VERSION ""

NS_ :

BS_:

BU_: FICM_FD Vector__XXX

BO_ 934 SeatAdjust2_FICM: 8 FICM_FD
 SG_ StTrkAdjReq_DR : 1|2@0+ (1,0) [0|2] ""  Vector__XXX
 SG_ StRtaAdjReq_DR : 3|2@0+ (1,0) [0|2] ""  Vector__XXX
 SG_ StRtaAdjReq_3rdL_FICM : 5|2@0+ (1,0) [0|2] ""  Vector__XXX
 SG_ StRtaAdjReq_3rdR_FICM : 7|2@0+ (1,0) [0|2] ""  Vector__XXX
 SG_ StHtReq_RL_HMI : 10|3@0+ (1,0) [0|4] ""  Vector__XXX
 SG_ StVtReq_RL_HMI : 13|3@0+ (1,0) [0|4] ""  Vector__XXX
 SG_ StPstrCmd_RL : 15|2@0+ (1,0) [0|3] ""  Vector__XXX
 SG_ StHtReq_RR_HMI : 18|3@0+ (1,0) [0|4] ""  Vector__XXX
 SG_ StVtReq_RR_HMI : 21|3@0+ (1,0) [0|4] ""  Vector__XXX
 SG_ StPstrCmd_RR : 23|2@0+ (1,0) [0|3] ""  Vector__XXX
 SG_ StLgRtaAdjReq_3rdR_FICM : 25|2@0+ (1,0) [0|2] ""  Vector__XXX
 SG_ StLgRtaAdjReq_3rdL_FICM : 27|2@0+ (1,0) [0|2] ""  Vector__XXX
 SG_ StTiltAdjReq_DR_FICM : 29|2@0+ (1,0) [0|2] ""  Vector__XXX
 SG_ StPhaAdjReq_DR_FICM : 31|2@0+ (1,0) [0|2] ""  Vector__XXX
 SG_ StSldAdjReq_RL_FICM : 33|2@0+ (1,0) [0|2] ""  Vector__XXX
 SG_ StLgLgthAdjReq_RL_FICM : 35|2@0+ (1,0) [0|2] ""  Vector__XXX
 SG_ StLgRtaAdjReq_RL_FICM : 37|2@0+ (1,0) [0|2] ""  Vector__XXX
 SG_ StSldAdjReq_RR_FICM : 39|2@0+ (1,0) [0|2] ""  Vector__XXX
 SG_ StLgLgthAdjReq_RR_FICM : 41|2@0+ (1,0) [0|2] ""  Vector__XXX
 SG_ StLgRtaAdjReq_RR_FICM : 43|2@0+ (1,0) [0|2] ""  Vector__XXX
 SG_ StHdrstAdjReq_RL_FICM : 45|2@0+ (1,0) [0|2] ""  Vector__XXX
 SG_ StHdrstAdjReq_RR_FICM : 47|2@0+ (1,0) [0|2] ""  Vector__XXX
 SG_ StMemCmd_RL_HMI : 49|2@0+ (1,0) [0|3] ""  Vector__XXX
 SG_ StMemPstnCalloutCmd_RL_HMI : 51|2@0+ (1,0) [0|3] ""  Vector__XXX
 SG_ StMemCmd_RR_HMI : 53|2@0+ (1,0) [0|3] ""  Vector__XXX
 SG_ StMemPstnCalloutCmd_RR_HMI : 55|2@0+ (1,0) [0|3] ""  Vector__XXX
 SG_ StPstrCmd_DR : 57|2@0+ (1,0) [0|3] ""  Vector__XXX
 SG_ StPstrCmd_PR : 59|2@0+ (1,0) [0|3] ""  Vector__XXX

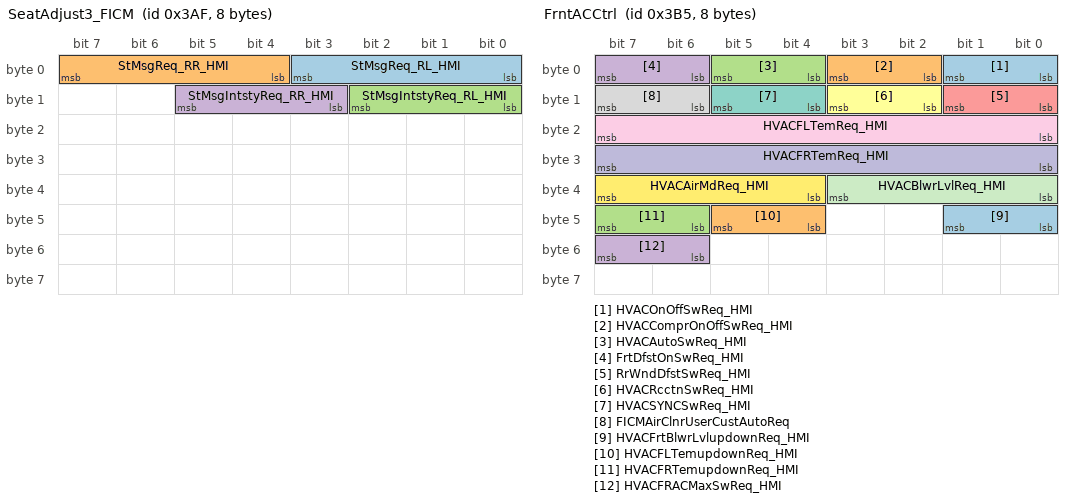
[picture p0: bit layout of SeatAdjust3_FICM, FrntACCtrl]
BO_ 943 SeatAdjust3_FICM: 8 FICM_FD
 SG_ StMsgReq_RL_HMI : 3|4@0+ (1,0) [0|15] ""  Vector__XXX
 SG_ StMsgReq_RR_HMI : 7|4@0+ (1,0) [0|15] ""  Vector__XXX
 SG_ StMsgIntstyReq_RL_HMI : 10|3@0+ (1,0) [0|4] ""  Vector__XXX
 SG_ StMsgIntstyReq_RR_HMI : 13|3@0+ (1,0) [0|4] ""  Vector__XXX

BO_ 944 Settings: 8 FICM_FD
 SG_ SnsSldDrSetReq : 1|2@0+ (1,0) [0|3] ""  Vector__XXX
 SG_ SnsSldDrActnTypSetReq : 4|3@0+ (1,0) [0|7] ""  Vector__XXX
 SG_ PDCBeepOffReq_F : 6|2@0+ (1,0) [0|3] ""  Vector__XXX
 SG_ ShowroomMdSts : 7|1@0+ (1,0) [0|1] ""  Vector__XXX
 SG_ StWelcomeSet_PR : 9|2@0+ (1,0) [0|2] ""  Vector__XXX
 SG_ SldDrOprtMdSt : 11|2@0+ (1,0) [0|3] ""  Vector__XXX
 SG_ FndMyCarSet : 13|2@0+ (1,0) [0|3] ""  Vector__XXX
 SG_ PDCBeepOffReq_R : 15|2@0+ (1,0) [0|3] ""  Vector__XXX
 SG_ RstrFctryDfltSttngRqst : 16|1@0+ (1,0) [0|1] ""  Vector__XXX
 SG_ RemoteLockingFdbckChgReq : 18|2@0+ (1,0) [0|3] ""  Vector__XXX
 SG_ IntLgtOprtMdSet : 20|2@0+ (1,0) [0|3] ""  Vector__XXX
 SG_ VehUnLckFormSet : 22|2@0+ (1,0) [0|3] ""  Vector__XXX
 SG_ SentryMdSetReq : 25|2@0+ (1,0) [0|3] ""  Vector__XXX
 SG_ TmDsplyFmt : 26|1@0+ (1,0) [0|1] ""  Vector__XXX
 SG_ MovingAutoLockChgReq : 29|2@0+ (1,0) [0|3] ""  Vector__XXX
 SG_ LanguageSettingAdj : 35|4@0+ (1,0) [0|15] ""  Vector__XXX
 SG_ DrvMdReq_HMI : 37|2@0+ (1,0) [0|3] ""  Vector__XXX
 SG_ LckAutoWdwClsSet : 39|2@0+ (1,0) [0|3] ""  Vector__XXX
 SG_ AutoUnlockingChgReq : 42|3@0+ (1,0) [0|4] ""  Vector__XXX
 SG_ FolwMeHmSet : 45|3@0+ (1,0) [0|4] ""  Vector__XXX
 SG_ MrrAutoFldSet : 47|2@0+ (1,0) [0|3] ""  Vector__XXX
 SG_ WprSnstvtytSet : 50|3@0+ (1,0) [0|7] ""  Vector__XXX
 SG_ RvsGearActvtRrWprSet : 52|2@0+ (1,0) [0|3] ""  Vector__XXX
 SG_ RainPrvtMdSet : 54|2@0+ (1,0) [0|3] ""  Vector__XXX
 SG_ MemReq : 57|2@0+ (1,0) [0|3] ""  Vector__XXX
 SG_ MemClrReq : 60|3@0+ (1,0) [0|4] ""  Vector__XXX
 SG_ MemCalOtReq : 62|2@0+ (1,0) [0|3] ""  Vector__XXX

BO_ 945 Settings2: 8 FICM_FD
 SG_ FICMOverSpdThreshholdVal : 7|8@0+ (1,0) [0|255] "km/h"  Vector__XXX
 SG_ TempParkReq : 9|2@0+ (1,0) [0|2] ""  Vector__XXX
 SG_ ThemeSettingAdj : 11|2@0+ (1,0) [0|3] ""  Vector__XXX
 SG_ VehMaintenanceSts : 13|2@0+ (1,0) [0|3] ""  Vector__XXX
 SG_ FICMOverSpdSwitchReq : 15|2@0+ (1,0) [0|2] ""  Vector__XXX
 SG_ DrvMdRcmdnDispReqFdbck : 18|3@0+ (1,0) [0|7] ""  Vector__XXX
 SG_ FICMDispRcmdnInfoEnbSts : 19|1@0+ (1,0) [0|1] ""  Vector__XXX
 SG_ HMIMtSwSts_L : 20|1@0+ (1,0) [0|1] ""  Vector__XXX
 SG_ HMICallPhReqSts : 21|1@0+ (1,0) [0|1] ""  Vector__XXX
 SG_ TempParkMdSet : 23|2@0+ (1,0) [0|3] ""  Vector__XXX
 SG_ HMIMtSwSts_R : 24|1@0+ (1,0) [0|1] ""  Vector__XXX
 SG_ RemnDstcDsplyExchgReq : 26|2@0+ (1,0) [0|3] ""  Vector__XXX
 SG_ DspMeasUntSetReq : 28|2@0+ (1,0) [0|3] ""  Vector__XXX
 SG_ IntLgtOffReq : 29|1@0+ (1,0) [0|1] ""  Vector__XXX
 SG_ RemnDstcDsplyCycReq : 31|2@0+ (1,0) [0|3] ""  Vector__XXX
 SG_ ChldLckSw_R : 33|2@0+ (1,0) [0|3] ""  Vector__XXX
 SG_ LockVehRcvrMdSet : 35|2@0+ (1,0) [0|3] ""  Vector__XXX
 SG_ IntltWlcmMdSet : 37|2@0+ (1,0) [0|3] ""  Vector__XXX
 SG_ ThemeSettingAdj_2 : 39|2@0+ (1,0) [0|3] ""  Vector__XXX
 SG_ RunPowMdAutoOffReq : 41|2@0+ (1,0) [0|3] ""  Vector__XXX
 SG_ CPDWrnngLvl : 43|2@0+ (1,0) [0|3] ""  Vector__XXX
 SG_ SldDrCtrlReq_R_HMI : 45|2@0+ (1,0) [0|3] ""  Vector__XXX
 SG_ ChldLckSw_L : 47|2@0+ (1,0) [0|3] ""  Vector__XXX
 SG_ CPDFnSwReq : 53|2@0+ (1,0) [0|3] ""  Vector__XXX
 SG_ RunPowMdAutoOffRmndrFdbck : 55|2@0+ (1,0) [0|3] ""  Vector__XXX
 SG_ ESSSwapCnfmFICM : 56|1@0+ (1,0) [0|1] ""  Vector__XXX
 SG_ ESSSwapCnfmFICMV : 57|1@0+ (1,0) [0|1] ""  Vector__XXX
 SG_ LanguageSettingAdj_2 : 49|8@0+ (1,0) [0|255] ""  Vector__XXX

BO_ 946 BodyCtrl: 8 FICM_FD
 SG_ HdLmpAdjReq : 2|3@0+ (1,0) [0|4] ""  Vector__XXX
 SG_ VisionMdReq : 4|2@0+ (1,0) [0|3] ""  Vector__XXX
 SG_ TlgtOprtMdSt : 6|2@0+ (1,0) [0|3] ""  Vector__XXX
 SG_ TlgtOprtReq : 11|4@0+ (1,0) [0|15] ""  Vector__XXX
 SG_ PDCMainSWReq_ICU : 13|2@0+ (1,0) [0|3] ""  Vector__XXX
 SG_ ChrIndReq_HMI : 15|2@0+ (1,0) [0|3] ""  Vector__XXX
 SG_ WPCEnblReq : 17|2@0+ (1,0) [0|3] ""  Vector__XXX
 SG_ BkltLumSet : 22|5@0+ (5,0) [0|100] "%"  Vector__XXX
 SG_ FrtFogLmpOprtMdSet : 25|2@0+ (1,0) [0|3] ""  Vector__XXX
 SG_ HdLmpOprtMdSet : 28|3@0+ (1,0) [0|4] ""  Vector__XXX
 SG_ FogLmpOprtMdSet : 30|2@0+ (1,0) [0|3] ""  Vector__XXX
 SG_ PMMOFFReq : 32|1@0+ (1,0) [0|1] ""  Vector__XXX
 SG_ TlgtPrkMdPosSt : 39|7@0+ (1,0) [0|100] "%"  Vector__XXX
 SG_ MrrAutoDipSet : 42|3@0+ (1,0) [0|7] ""  Vector__XXX
 SG_ FrtWprOprtReq : 45|3@0+ (1,0) [0|7] ""  Vector__XXX
 SG_ FICMBssMdReq : 47|2@0+ (1,0) [0|3] ""  Vector__XXX
 SG_ BodyCtrl_RllCnt : 51|4@0+ (1,0) [0|15] ""  Vector__XXX
 SG_ PckLgtOprtMdSet : 55|2@0+ (1,0) [0|3] ""  Vector__XXX
 SG_ BodyCtrl_Chksum : 63|8@0+ (1,0) [0|255] ""  Vector__XXX

BO_ 947 Chassis_PowerTrainCtrl: 8 FICM_FD
 SG_ HDCFnSwReq : 1|2@0+ (1,0) [0|3] ""  Vector__XXX
 SG_ ESCFnSwReq : 3|2@0+ (1,0) [0|3] ""  Vector__XXX
 SG_ EPBIgnoffAutoAppFnSwReq : 5|2@0+ (1,0) [0|3] ""  Vector__XXX
 SG_ AVHFnSwReq : 7|2@0+ (1,0) [0|3] ""  Vector__XXX
 SG_ EPBRlseFuSwReq : 9|2@0+ (1,0) [0|3] ""  Vector__XXX
 SG_ EPSCurrModReq : 12|3@0+ (1,0) [0|7] ""  Vector__XXX
 SG_ BrkFlngMdStsReq : 15|3@0+ (1,0) [0|7] ""  Vector__XXX
 SG_ RGNSwReq : 17|2@0+ (1,0) [0|3] ""  Vector__XXX
 SG_ FrtPsngAirbagOnOffReq : 19|2@0+ (1,0) [0|3] ""  Vector__XXX
 SG_ RGNSwReqV : 20|1@0+ (1,0) [0|1] ""  Vector__XXX
 SG_ RGNResReq : 21|1@0+ (1,0) [0|1] ""  Vector__XXX
 SG_ RGNResReqV : 22|1@0+ (1,0) [0|1] ""  Vector__XXX
 SG_ ASSBtnReq : 23|1@0+ (1,0) [0|1] ""  Vector__XXX
 SG_ SBRSetReq_R : 33|2@0+ (1,0) [0|3] ""  Vector__XXX
 SG_ RGNOkNum : 31|14@0+ (1,0) [0|10000] ""  Vector__XXX
 SG_ RGNResNum : 47|8@0+ (1,0) [0|255] ""  Vector__XXX
 SG_ Chassis_PowerTrainCtrl_RllCnt : 51|4@0+ (1,0) [0|15] ""  Vector__XXX
 SG_ CCOFnSoftSw : 53|2@0+ (1,0) [0|3] ""  Vector__XXX
 SG_ WadeModeReq : 55|2@0+ (1,0) [0|3] ""  Vector__XXX
 SG_ Chassis_PowerTrainCtrl_Chksum : 63|8@0+ (1,0) [0|255] ""  Vector__XXX

BO_ 949 FrntACCtrl: 8 FICM_FD
 SG_ HVACOnOffSwReq_HMI : 1|2@0+ (1,0) [0|3] ""  Vector__XXX
 SG_ HVACComprOnOffSwReq_HMI : 3|2@0+ (1,0) [0|3] ""  Vector__XXX
 SG_ HVACAutoSwReq_HMI : 5|2@0+ (1,0) [0|3] ""  Vector__XXX
 SG_ FrtDfstOnSwReq_HMI : 7|2@0+ (1,0) [0|3] ""  Vector__XXX
 SG_ RrWndDfstSwReq_HMI : 9|2@0+ (1,0) [0|3] ""  Vector__XXX
 SG_ HVACRcctnSwReq_HMI : 11|2@0+ (1,0) [0|3] ""  Vector__XXX
 SG_ HVACSYNCSwReq_HMI : 13|2@0+ (1,0) [0|3] ""  Vector__XXX
 SG_ FICMAirClnrUserCustAutoReq : 15|2@0+ (1,0) [0|3] ""  Vector__XXX
 SG_ HVACFLTemReq_HMI : 23|8@0+ (1,0) [17|33] "deg C"  Vector__XXX
 SG_ HVACFRTemReq_HMI : 31|8@0+ (1,0) [17|33] "deg C"  Vector__XXX
 SG_ HVACBlwrLvlReq_HMI : 35|4@0+ (1,0) [0|15] ""  Vector__XXX
 SG_ HVACAirMdReq_HMI : 39|4@0+ (1,0) [0|15] ""  Vector__XXX
 SG_ HVACFrtBlwrLvlupdownReq_HMI : 41|2@0+ (1,0) [0|3] ""  Vector__XXX
 SG_ HVACFLTemupdownReq_HMI : 45|2@0+ (1,0) [0|3] ""  Vector__XXX
 SG_ HVACFRTemupdownReq_HMI : 47|2@0+ (1,0) [0|3] ""  Vector__XXX
 SG_ HVACFRACMaxSwReq_HMI : 55|2@0+ (1,0) [0|3] ""  Vector__XXX

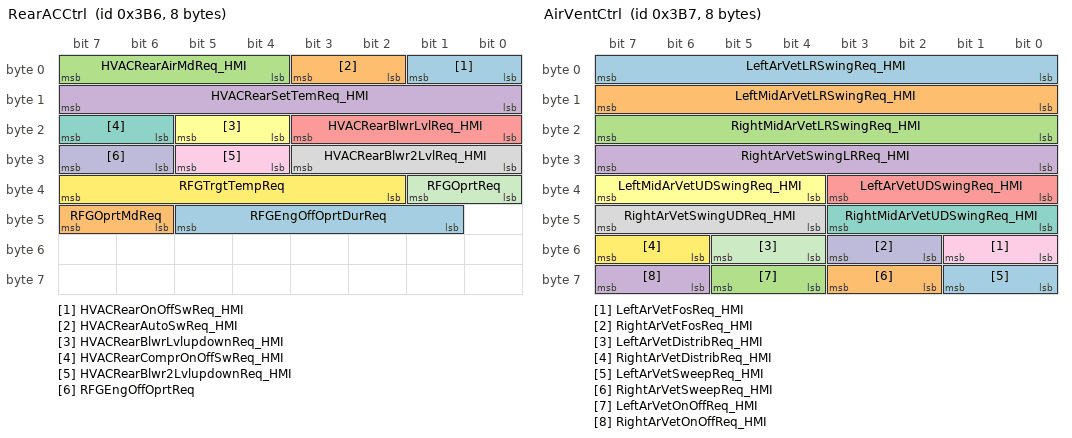
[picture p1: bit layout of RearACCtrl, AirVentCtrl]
BO_ 950 RearACCtrl: 8 FICM_FD
 SG_ HVACRearOnOffSwReq_HMI : 1|2@0+ (1,0) [0|3] ""  Vector__XXX
 SG_ HVACRearAutoSwReq_HMI : 3|2@0+ (1,0) [0|3] ""  Vector__XXX
 SG_ HVACRearAirMdReq_HMI : 7|4@0+ (1,0) [0|15] ""  Vector__XXX
 SG_ HVACRearSetTemReq_HMI : 15|8@0+ (1,0) [17|33] "deg C"  Vector__XXX
 SG_ HVACRearBlwrLvlReq_HMI : 19|4@0+ (1,0) [0|15] ""  Vector__XXX
 SG_ HVACRearBlwrLvlupdownReq_HMI : 21|2@0+ (1,0) [0|3] ""  Vector__XXX
 SG_ HVACRearComprOnOffSwReq_HMI : 23|2@0+ (1,0) [1|3] ""  Vector__XXX
 SG_ HVACRearBlwr2LvlReq_HMI : 27|4@0+ (1,0) [0|15] ""  Vector__XXX
 SG_ HVACRearBlwr2LvlupdownReq_HMI : 29|2@0+ (1,0) [0|3] ""  Vector__XXX
 SG_ RFGEngOffOprtReq : 31|2@0+ (1,0) [0|3] ""  Vector__XXX
 SG_ RFGOprtReq : 33|2@0+ (1,0) [0|3] ""  Vector__XXX
 SG_ RFGTrgtTempReq : 39|6@0+ (1,0) [0|63] "℃"  Vector__XXX
 SG_ RFGEngOffOprtDurReq : 45|5@0+ (1,0) [0|31] "h"  Vector__XXX
 SG_ RFGOprtMdReq : 47|2@0+ (1,0) [0|3] ""  Vector__XXX

BO_ 951 AirVentCtrl: 8 FICM_FD
 SG_ LeftArVetLRSwingReq_HMI : 7|8@0+ (1,0) [0|100] "%"  Vector__XXX
 SG_ LeftMidArVetLRSwingReq_HMI : 15|8@0+ (1,0) [0|100] "%"  Vector__XXX
 SG_ RightMidArVetLRSwingReq_HMI : 23|8@0+ (1,0) [0|100] "%"  Vector__XXX
 SG_ RightArVetSwingLRReq_HMI : 31|8@0+ (1,0) [0|100] "%"  Vector__XXX
 SG_ LeftArVetUDSwingReq_HMI : 35|4@0+ (10,0) [0|100] "%"  Vector__XXX
 SG_ LeftMidArVetUDSwingReq_HMI : 39|4@0+ (10,0) [0|100] "%"  Vector__XXX
 SG_ RightMidArVetUDSwingReq_HMI : 43|4@0+ (10,0) [0|100] "%"  Vector__XXX
 SG_ RightArVetSwingUDReq_HMI : 47|4@0+ (10,0) [0|100] "%"  Vector__XXX
 SG_ LeftArVetFosReq_HMI : 49|2@0+ (1,0) [0|3] ""  Vector__XXX
 SG_ RightArVetFosReq_HMI : 51|2@0+ (1,0) [0|3] ""  Vector__XXX
 SG_ LeftArVetDistribReq_HMI : 53|2@0+ (1,0) [0|3] ""  Vector__XXX
 SG_ RightArVetDistribReq_HMI : 55|2@0+ (1,0) [0|3] ""  Vector__XXX
 SG_ LeftArVetSweepReq_HMI : 57|2@0+ (1,0) [0|3] ""  Vector__XXX
 SG_ RightArVetSweepReq_HMI : 59|2@0+ (1,0) [0|3] ""  Vector__XXX
 SG_ LeftArVetOnOffReq_HMI : 61|2@0+ (1,0) [0|3] ""  Vector__XXX
 SG_ RightArVetOnOffReq_HMI : 63|2@0+ (1,0) [0|3] ""  Vector__XXX

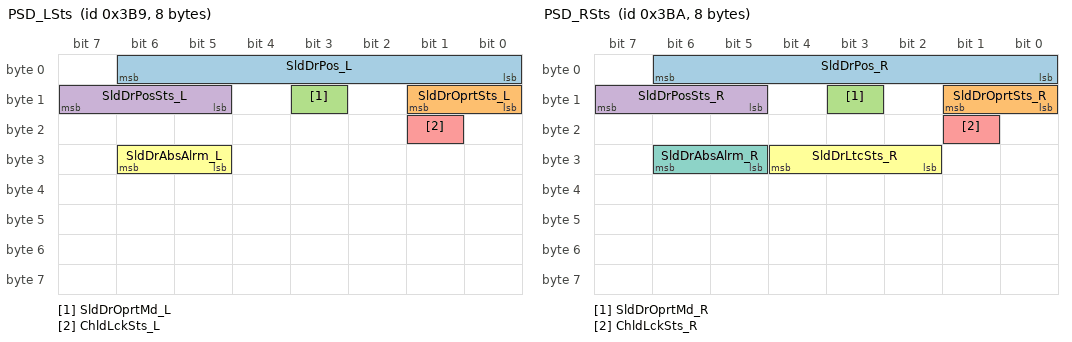
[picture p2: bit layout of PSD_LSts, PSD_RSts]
BO_ 953 PSD_LSts: 8 Vector__XXX
 SG_ SldDrPos_L : 6|7@0+ (1,0) [0|127] "%"  FICM_FD
 SG_ SldDrOprtSts_L : 9|2@0+ (1,0) [0|3] ""  FICM_FD
 SG_ SldDrOprtMd_L : 11|1@0+ (1,0) [0|1] ""  FICM_FD
 SG_ SldDrPosSts_L : 15|3@0+ (1,0) [0|7] ""  FICM_FD
 SG_ ChldLckSts_L : 17|1@0+ (1,0) [0|1] ""  FICM_FD
 SG_ SldDrAbsAlrm_L : 30|2@0+ (1,0) [0|3] ""  FICM_FD

BO_ 954 PSD_RSts: 8 Vector__XXX
 SG_ SldDrPos_R : 6|7@0+ (1,0) [0|127] "%"  FICM_FD
 SG_ SldDrOprtSts_R : 9|2@0+ (1,0) [0|3] ""  FICM_FD
 SG_ SldDrOprtMd_R : 11|1@0+ (1,0) [0|1] ""  FICM_FD
 SG_ SldDrPosSts_R : 15|3@0+ (1,0) [0|7] ""  FICM_FD
 SG_ ChldLckSts_R : 17|1@0+ (1,0) [0|1] ""  FICM_FD
 SG_ SldDrLtcSts_R : 28|3@0+ (1,0) [0|7] ""  FICM_FD
 SG_ SldDrAbsAlrm_R : 30|2@0+ (1,0) [0|3] ""  FICM_FD

BO_ 956 BodyCtrl2: 8 FICM_FD
 SG_ HMIRfLmp1Cmd : 2|2@0+ (1,0) [0|2] ""  Vector__XXX
 SG_ Wdw_DRAutoOprtnReq : 7|5@0+ (5,0) [0|100] "%"  Vector__XXX
 SG_ Wdw_PRAutoOprtnReq : 12|5@0+ (5,0) [0|100] "%"  Vector__XXX
 SG_ AprchngLghtSt : 14|2@0+ (1,0) [0|3] ""  Vector__XXX
 SG_ IntWlcmLampSetReq : 0|2@0+ (1,0) [0|3] ""  Vector__XXX
 SG_ HMIRfLmp2Cmd : 18|2@0+ (1,0) [0|2] ""  Vector__XXX
 SG_ Wdw_RLAutoOprtnReq : 23|5@0+ (5,0) [0|100] "%"  Vector__XXX
 SG_ Wdw_RRAutoOprtnReq : 28|5@0+ (5,0) [0|100] "%"  Vector__XXX
 SG_ DrvrFatigueReminderSetReq : 30|2@0+ (1,0) [0|3] ""  Vector__XXX
 SG_ LogoLgtOnPGearSetReq : 16|2@0+ (1,0) [0|3] ""  Vector__XXX
 SG_ HMIRfLmp3Cmd : 33|2@0+ (1,0) [0|2] ""  Vector__XXX
 SG_ HMIRfLmp4Cmd : 35|2@0+ (1,0) [0|2] ""  Vector__XXX
 SG_ PSRTrgtSlct : 37|2@0+ (1,0) [0|3] ""  Vector__XXX
 SG_ PSRManualOprtReq : 39|2@0+ (1,0) [0|3] ""  Vector__XXX
 SG_ HMIRfLmpTrdRowCmd : 42|2@0+ (1,0) [0|2] ""  Vector__XXX
 SG_ PSRAutoOprtReq : 47|5@0+ (1,0) [0|31] ""  Vector__XXX
 SG_ SRFAutoOprtReq : 52|5@0+ (1,0) [0|31] ""  Vector__XXX
 SG_ SRFManualOprtReq : 54|2@0+ (1,0) [0|3] ""  Vector__XXX
 SG_ HVFuelCmd : 40|2@0+ (1,0) [0|2] ""  Vector__XXX
 SG_ TlgtOprtPosReq : 62|7@0+ (1,0) [0|100] "%"  Vector__XXX

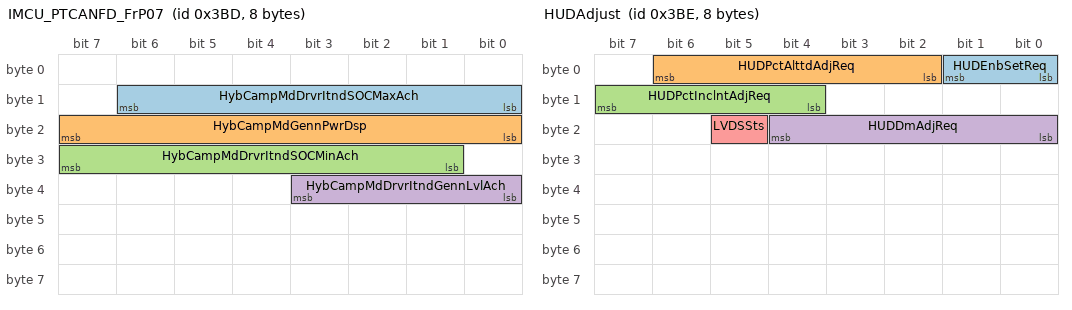
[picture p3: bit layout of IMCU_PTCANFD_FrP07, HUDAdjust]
BO_ 957 IMCU_PTCANFD_FrP07: 8 Vector__XXX
 SG_ HybCampMdDrvrItndSOCMaxAch : 14|7@0+ (1,0) [0|127] ""  FICM_FD
 SG_ HybCampMdGennPwrDsp : 23|8@0+ (0.1,0) [0|25.5] ""  FICM_FD
 SG_ HybCampMdDrvrItndSOCMinAch : 31|7@0+ (1,0) [0|127] ""  FICM_FD
 SG_ HybCampMdDrvrItndGennLvlAch : 35|4@0+ (1,0) [0|15] ""  FICM_FD

BO_ 958 HUDAdjust: 8 FICM_FD
 SG_ HUDEnbSetReq : 1|2@0+ (1,0) [0|3] ""  Vector__XXX
 SG_ HUDPctAlttdAdjReq : 6|5@0+ (1,0) [0|20] ""  Vector__XXX
 SG_ HUDPctInclntAdjReq : 15|4@0+ (1,0) [0|15] ""  Vector__XXX
 SG_ HUDDmAdjReq : 20|5@0+ (1,0) [0|20] ""  Vector__XXX
 SG_ LVDSSts : 21|1@0+ (1,0) [0|1] ""  Vector__XXX

BO_ 965 PersonalSettings: 8 Vector__XXX
 SG_ VehUnLckForm_VAN : 6|3@0+ (1,0) [0|7] ""  FICM_FD
 SG_ RainPrvtMdSts : 8|1@0+ (1,0) [0|1] ""  FICM_FD
 SG_ LckAutoWdwClsSts : 9|1@0+ (1,0) [0|1] ""  FICM_FD
 SG_ StWelcomeSts_DR : 10|1@0+ (1,0) [0|1] ""  FICM_FD
 SG_ TempParkMdSetSts : 11|1@0+ (1,0) [0|1] ""  FICM_FD
 SG_ TempParkMode : 12|1@0+ (1,0) [0|1] ""  FICM_FD
 SG_ VehUnLckForm : 13|1@0+ (1,0) [0|1] ""  FICM_FD
 SG_ LckFdbkSts : 15|2@0+ (1,0) [0|2] ""  FICM_FD
 SG_ MrrAutoDipSts : 17|2@0+ (1,0) [0|3] ""  FICM_FD
 SG_ MrrAutoFldSts : 18|1@0+ (1,0) [0|1] ""  FICM_FD
 SG_ DrvrFatigueReminderSetReqFdbck : 19|1@0+ (1,0) [0|1] ""  FICM_FD
 SG_ StWelcomeSts_PR : 20|1@0+ (1,0) [0|1] ""  FICM_FD
 SG_ FlwMHmSts : 25|2@0+ (1,0) [0|3] ""  FICM_FD
 SG_ IntltWlcmMdSts : 26|1@0+ (1,0) [0|1] ""  FICM_FD
 SG_ LockVehRcvrMdSts : 27|1@0+ (1,0) [0|1] ""  FICM_FD
 SG_ FndMyCarSts : 29|2@0+ (1,0) [0|3] ""  FICM_FD
 SG_ FndMyCarTmSts : 31|2@0+ (1,0) [0|3] ""  FICM_FD
 SG_ DrvMod : 33|2@0+ (1,0) [0|3] ""  FICM_FD
 SG_ DrvMdReqV : 34|1@0+ (1,0) [0|1] ""  FICM_FD
 SG_ MemFdbk : 39|2@0+ (1,0) [0|2] ""  FICM_FD
 SG_ MemClrFdbk : 41|2@0+ (1,0) [0|2] ""  FICM_FD
 SG_ SnsSldDrSetReqFdbck : 42|1@0+ (1,0) [0|1] ""  FICM_FD
 SG_ AutoUnlockingSts : 44|2@0+ (1,0) [0|3] ""  FICM_FD
 SG_ MovingAutoLockSts : 45|1@0+ (1,0) [0|1] ""  FICM_FD
 SG_ iBDUFctryDeftSetFnsh : 47|2@0+ (1,0) [0|3] ""  FICM_FD
 SG_ RunPowMdAutoOffSts : 54|1@0+ (1,0) [0|1] ""  FICM_FD
 SG_ RunPowMdAutoOffRmndrReq : 55|1@0+ (1,0) [0|1] ""  FICM_FD

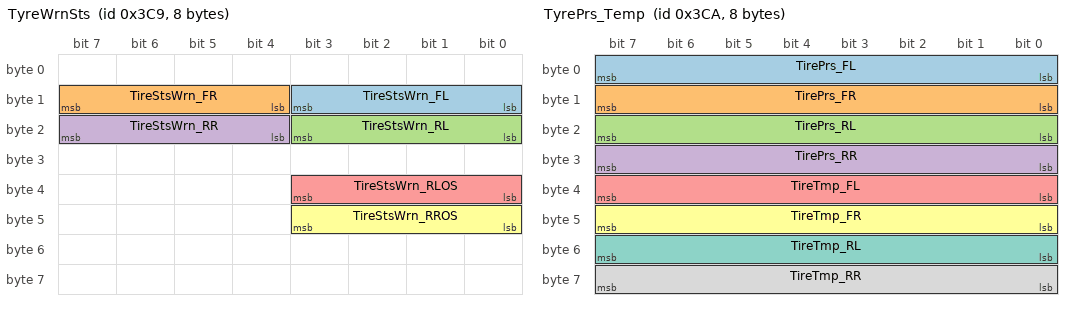
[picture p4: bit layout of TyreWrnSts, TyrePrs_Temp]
BO_ 969 TyreWrnSts: 8 Vector__XXX
 SG_ TireStsWrn_FL : 11|4@0+ (1,0) [0|15] ""  FICM_FD
 SG_ TireStsWrn_FR : 15|4@0+ (1,0) [0|15] ""  FICM_FD
 SG_ TireStsWrn_RL : 19|4@0+ (1,0) [0|15] ""  FICM_FD
 SG_ TireStsWrn_RR : 23|4@0+ (1,0) [0|15] ""  FICM_FD
 SG_ TireStsWrn_RLOS : 35|4@0+ (1,0) [0|15] ""  FICM_FD
 SG_ TireStsWrn_RROS : 43|4@0+ (1,0) [0|15] ""  FICM_FD

BO_ 970 TyrePrs_Temp: 8 Vector__XXX
 SG_ TirePrs_FL : 7|8@0+ (2.75,0) [0|700] "kpa"  FICM_FD
 SG_ TirePrs_FR : 15|8@0+ (2.75,0) [0|700] "kpa"  FICM_FD
 SG_ TirePrs_RL : 23|8@0+ (2.75,0) [0|700] "kpa"  FICM_FD
 SG_ TirePrs_RR : 31|8@0+ (2.75,0) [0|700] "kpa"  FICM_FD
 SG_ TireTmp_FL : 39|8@0+ (1,-60) [-60|194] ""  FICM_FD
 SG_ TireTmp_FR : 47|8@0+ (1,-60) [-60|194] ""  FICM_FD
 SG_ TireTmp_RL : 55|8@0+ (1,-60) [-60|194] ""  FICM_FD
 SG_ TireTmp_RR : 63|8@0+ (1,-60) [-60|194] ""  FICM_FD

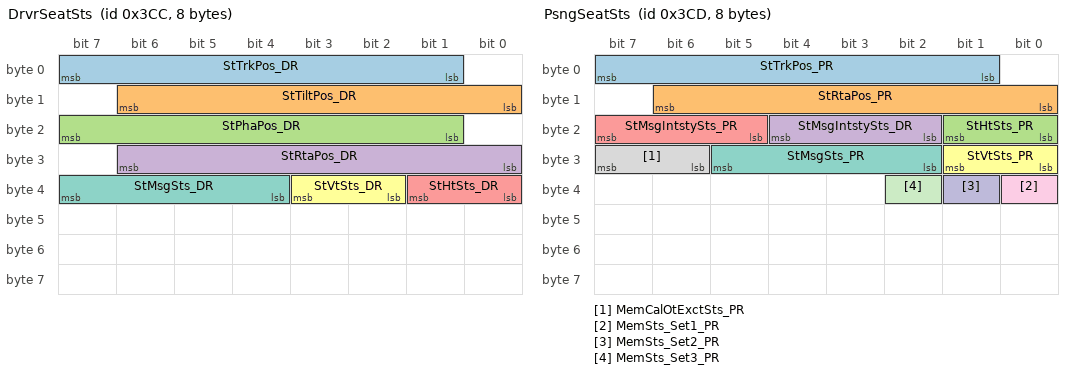
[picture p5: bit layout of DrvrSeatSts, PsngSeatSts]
BO_ 972 DrvrSeatSts: 8 Vector__XXX
 SG_ StTrkPos_DR : 7|7@0+ (1,0) [0|127] "%"  FICM_FD
 SG_ StTiltPos_DR : 14|7@0+ (1,0) [0|127] "%"  FICM_FD
 SG_ StPhaPos_DR : 23|7@0+ (1,0) [0|127] "%"  FICM_FD
 SG_ StRtaPos_DR : 30|7@0+ (1,0) [0|127] "%"  FICM_FD
 SG_ StHtSts_DR : 33|2@0+ (1,0) [0|3] ""  FICM_FD
 SG_ StVtSts_DR : 35|2@0+ (1,0) [0|3] ""  FICM_FD
 SG_ StMsgSts_DR : 39|4@0+ (1,0) [0|15] ""  FICM_FD

BO_ 973 PsngSeatSts: 8 Vector__XXX
 SG_ StTrkPos_PR : 7|7@0+ (1,0) [0|127] "%"  FICM_FD
 SG_ StRtaPos_PR : 14|7@0+ (1,0) [0|127] "%"  FICM_FD
 SG_ StHtSts_PR : 17|2@0+ (1,0) [0|3] ""  FICM_FD
 SG_ StMsgIntstySts_DR : 20|3@0+ (1,0) [0|7] ""  FICM_FD
 SG_ StMsgIntstySts_PR : 23|3@0+ (1,0) [0|7] ""  FICM_FD
 SG_ StVtSts_PR : 25|2@0+ (1,0) [0|3] ""  FICM_FD
 SG_ StMsgSts_PR : 29|4@0+ (1,0) [0|15] ""  FICM_FD
 SG_ MemCalOtExctSts_PR : 31|2@0+ (1,0) [0|3] ""  FICM_FD
 SG_ MemSts_Set1_PR : 32|1@0+ (1,0) [0|1] ""  FICM_FD
 SG_ MemSts_Set2_PR : 33|1@0+ (1,0) [0|1] ""  FICM_FD
 SG_ MemSts_Set3_PR : 34|1@0+ (1,0) [0|1] ""  FICM_FD

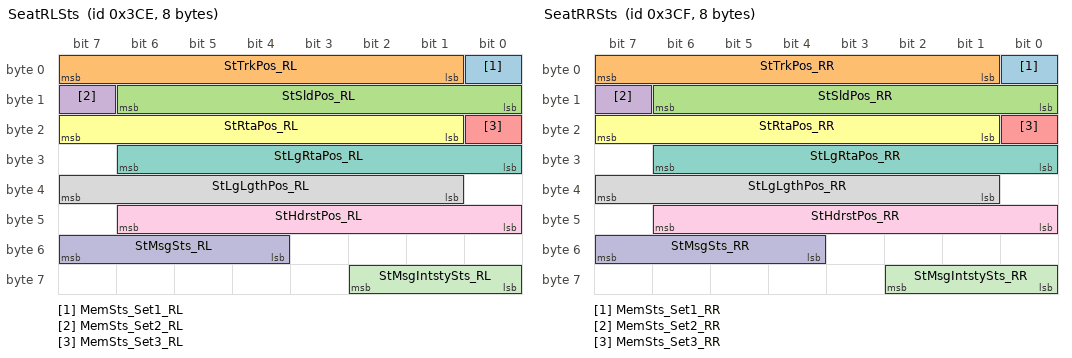
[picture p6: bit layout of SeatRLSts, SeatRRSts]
BO_ 974 SeatRLSts: 8 Vector__XXX
 SG_ MemSts_Set1_RL : 0|1@0+ (1,0) [0|1] ""  FICM_FD
 SG_ StTrkPos_RL : 7|7@0+ (1,0) [0|127] "%"  FICM_FD
 SG_ StSldPos_RL : 14|7@0+ (1,0) [0|127] "%"  FICM_FD
 SG_ MemSts_Set2_RL : 15|1@0+ (1,0) [0|1] ""  FICM_FD
 SG_ MemSts_Set3_RL : 16|1@0+ (1,0) [0|1] ""  FICM_FD
 SG_ StRtaPos_RL : 23|7@0+ (1,0) [0|127] "%"  FICM_FD
 SG_ StLgRtaPos_RL : 30|7@0+ (1,0) [0|127] "%"  FICM_FD
 SG_ StLgLgthPos_RL : 39|7@0+ (1,0) [0|127] "%"  FICM_FD
 SG_ StHdrstPos_RL : 46|7@0+ (1,0) [0|127] "%"  FICM_FD
 SG_ StMsgSts_RL : 55|4@0+ (1,0) [0|15] ""  FICM_FD
 SG_ StMsgIntstySts_RL : 58|3@0+ (1,0) [0|7] ""  FICM_FD

BO_ 975 SeatRRSts: 8 Vector__XXX
 SG_ MemSts_Set1_RR : 0|1@0+ (1,0) [0|1] ""  FICM_FD
 SG_ StTrkPos_RR : 7|7@0+ (1,0) [0|127] "%"  FICM_FD
 SG_ StSldPos_RR : 14|7@0+ (1,0) [0|127] "%"  FICM_FD
 SG_ MemSts_Set2_RR : 15|1@0+ (1,0) [0|1] ""  FICM_FD
 SG_ MemSts_Set3_RR : 16|1@0+ (1,0) [0|1] ""  FICM_FD
 SG_ StRtaPos_RR : 23|7@0+ (1,0) [0|127] "%"  FICM_FD
 SG_ StLgRtaPos_RR : 30|7@0+ (1,0) [0|127] "%"  FICM_FD
 SG_ StLgLgthPos_RR : 39|7@0+ (1,0) [0|127] "%"  FICM_FD
 SG_ StHdrstPos_RR : 46|7@0+ (1,0) [0|127] "%"  FICM_FD
 SG_ StMsgSts_RR : 55|4@0+ (1,0) [0|15] ""  FICM_FD
 SG_ StMsgIntstySts_RR : 58|3@0+ (1,0) [0|7] ""  FICM_FD

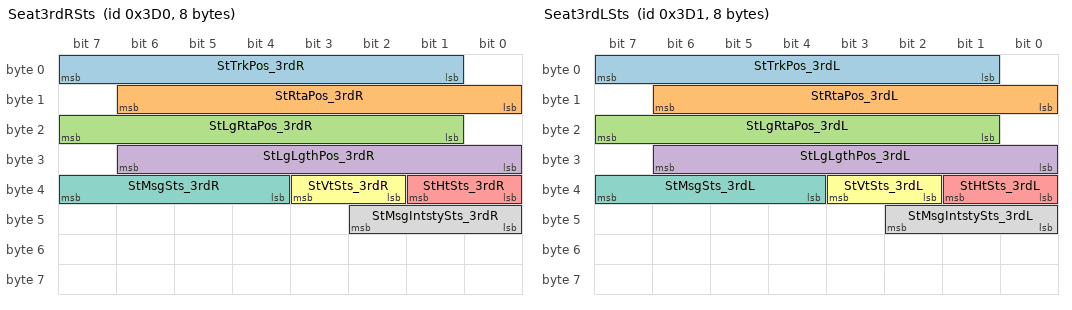
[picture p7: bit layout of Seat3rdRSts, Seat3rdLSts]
BO_ 976 Seat3rdRSts: 8 Vector__XXX
 SG_ StTrkPos_3rdR : 7|7@0+ (1,0) [0|127] ""  FICM_FD
 SG_ StRtaPos_3rdR : 14|7@0+ (1,0) [0|127] ""  FICM_FD
 SG_ StLgRtaPos_3rdR : 23|7@0+ (1,0) [0|127] ""  FICM_FD
 SG_ StLgLgthPos_3rdR : 30|7@0+ (1,0) [0|127] ""  FICM_FD
 SG_ StHtSts_3rdR : 33|2@0+ (1,0) [0|3] ""  FICM_FD
 SG_ StVtSts_3rdR : 35|2@0+ (1,0) [0|3] ""  FICM_FD
 SG_ StMsgSts_3rdR : 39|4@0+ (1,0) [0|15] ""  FICM_FD
 SG_ StMsgIntstySts_3rdR : 42|3@0+ (1,0) [0|7] ""  FICM_FD

BO_ 977 Seat3rdLSts: 8 Vector__XXX
 SG_ StTrkPos_3rdL : 7|7@0+ (1,0) [0|127] ""  FICM_FD
 SG_ StRtaPos_3rdL : 14|7@0+ (1,0) [0|127] ""  FICM_FD
 SG_ StLgRtaPos_3rdL : 23|7@0+ (1,0) [0|127] ""  FICM_FD
 SG_ StLgLgthPos_3rdL : 30|7@0+ (1,0) [0|127] ""  FICM_FD
 SG_ StHtSts_3rdL : 33|2@0+ (1,0) [0|3] ""  FICM_FD
 SG_ StVtSts_3rdL : 35|2@0+ (1,0) [0|3] ""  FICM_FD
 SG_ StMsgSts_3rdL : 39|4@0+ (1,0) [0|15] ""  FICM_FD
 SG_ StMsgIntstySts_3rdL : 42|3@0+ (1,0) [0|7] ""  FICM_FD

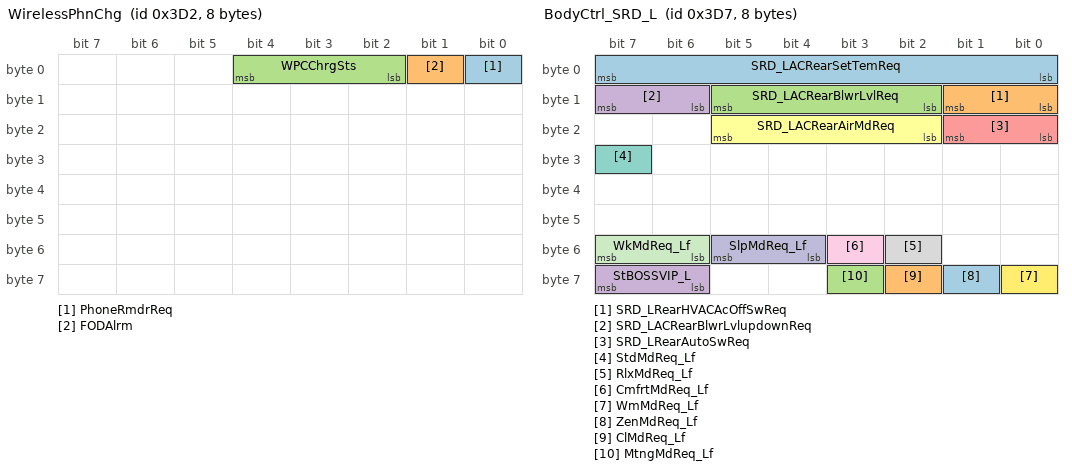
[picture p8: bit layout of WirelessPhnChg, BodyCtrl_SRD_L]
BO_ 978 WirelessPhnChg: 8 Vector__XXX
 SG_ PhoneRmdrReq : 0|1@0+ (1,0) [0|1] ""  FICM_FD
 SG_ FODAlrm : 1|1@0+ (1,0) [0|1] ""  FICM_FD
 SG_ WPCChrgSts : 4|3@0+ (1,0) [0|7] ""  FICM_FD

BO_ 983 BodyCtrl_SRD_L: 8 Vector__XXX
 SG_ SRD_LACRearSetTemReq : 7|8@0+ (1,0) [17|33] ""  FICM_FD
 SG_ SRD_LRearHVACAcOffSwReq : 9|2@0+ (1,0) [0|3] ""  FICM_FD
 SG_ SRD_LACRearBlwrLvlReq : 13|4@0+ (1,0) [0|15] ""  FICM_FD
 SG_ SRD_LACRearBlwrLvlupdownReq : 15|2@0+ (1,0) [0|3] ""  FICM_FD
 SG_ SRD_LRearAutoSwReq : 17|2@0+ (1,0) [0|3] ""  FICM_FD
 SG_ SRD_LACRearAirMdReq : 21|4@0+ (1,0) [0|15] ""  FICM_FD
 SG_ StdMdReq_Lf : 31|1@0+ (1,0) [0|1] ""  FICM_FD
 SG_ RlxMdReq_Lf : 50|1@0+ (1,0) [0|1] ""  FICM_FD
 SG_ CmfrtMdReq_Lf : 51|1@0+ (1,0) [0|1] ""  FICM_FD
 SG_ SlpMdReq_Lf : 53|2@0+ (1,0) [0|3] ""  FICM_FD
 SG_ WkMdReq_Lf : 55|2@0+ (1,0) [0|3] ""  FICM_FD
 SG_ WmMdReq_Lf : 56|1@0+ (1,0) [0|1] ""  FICM_FD
 SG_ ZenMdReq_Lf : 57|1@0+ (1,0) [0|1] ""  FICM_FD
 SG_ ClMdReq_Lf : 58|1@0+ (1,0) [0|1] ""  FICM_FD
 SG_ MtngMdReq_Lf : 59|1@0+ (1,0) [0|1] ""  FICM_FD
 SG_ StBOSSVIP_L : 63|2@0+ (1,0) [0|3] ""  FICM_FD

BO_ 984 BodyCtrl_SRD_R: 8 Vector__XXX
 SG_ SRD_RACRearSetTemReq : 7|8@0+ (1,0) [17|33] ""  FICM_FD
 SG_ SRD_RRearHVACAcOffSwReq : 9|2@0+ (1,0) [0|3] ""  FICM_FD
 SG_ SRD_RACRearBlwrLvlReq : 13|4@0+ (1,0) [0|15] ""  FICM_FD
 SG_ SRD_RACRearBlwrLvlupdownReq : 15|2@0+ (1,0) [0|3] ""  FICM_FD
 SG_ SRD_RRearAutoSwReq : 17|2@0+ (1,0) [0|3] ""  FICM_FD
 SG_ SRD_RACRearAirMdReq : 21|4@0+ (1,0) [0|15] ""  FICM_FD
 SG_ StdMdReq_Rt : 31|1@0+ (1,0) [0|1] ""  FICM_FD
 SG_ RlxMdReq_Rt : 50|1@0+ (1,0) [0|1] ""  FICM_FD
 SG_ CmfrtMdReq_Rt : 51|1@0+ (1,0) [0|1] ""  FICM_FD
 SG_ SlpMdReq_Rt : 53|2@0+ (1,0) [0|3] ""  FICM_FD
 SG_ WkMdReq_Rt : 55|2@0+ (1,0) [0|3] ""  FICM_FD
 SG_ WmMdReq_Rt : 56|1@0+ (1,0) [0|1] ""  FICM_FD
 SG_ ZenMdReq_Rt : 57|1@0+ (1,0) [0|1] ""  FICM_FD
 SG_ ClMdReq_Rt : 58|1@0+ (1,0) [0|1] ""  FICM_FD
 SG_ MtngMdReq_Rt : 59|1@0+ (1,0) [0|1] ""  FICM_FD
 SG_ SmkMdReq_Rt : 61|2@0+ (1,0) [0|3] ""  FICM_FD
 SG_ StBOSSVIP_R : 63|2@0+ (1,0) [0|3] ""  FICM_FD

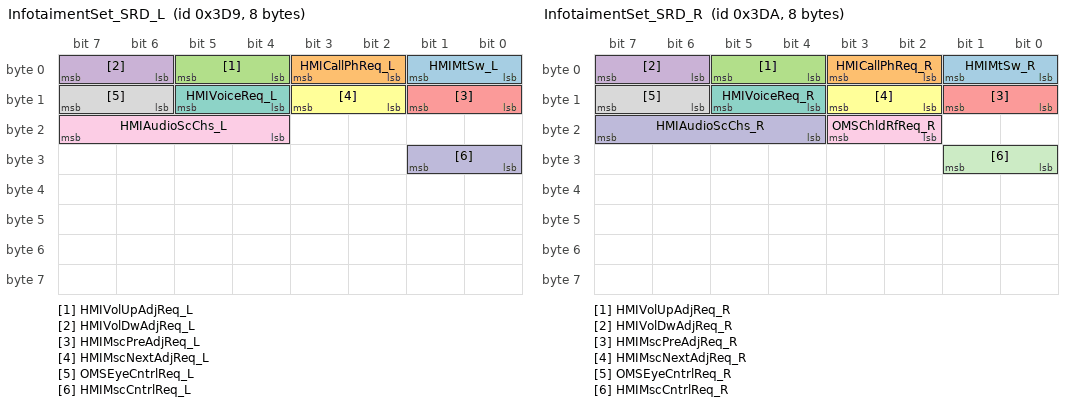
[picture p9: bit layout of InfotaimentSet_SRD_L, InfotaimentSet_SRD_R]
BO_ 985 InfotaimentSet_SRD_L: 8 Vector__XXX
 SG_ HMIMtSw_L : 1|2@0+ (1,0) [0|3] ""  FICM_FD
 SG_ HMICallPhReq_L : 3|2@0+ (1,0) [0|3] ""  FICM_FD
 SG_ HMIVolUpAdjReq_L : 5|2@0+ (1,0) [0|3] ""  FICM_FD
 SG_ HMIVolDwAdjReq_L : 7|2@0+ (1,0) [0|3] ""  FICM_FD
 SG_ HMIMscPreAdjReq_L : 9|2@0+ (1,0) [0|3] ""  FICM_FD
 SG_ HMIMscNextAdjReq_L : 11|2@0+ (1,0) [0|3] ""  FICM_FD
 SG_ HMIVoiceReq_L : 13|2@0+ (1,0) [0|3] ""  FICM_FD
 SG_ OMSEyeCntrlReq_L : 15|2@0+ (1,0) [0|3] ""  FICM_FD
 SG_ HMIAudioScChs_L : 23|4@0+ (1,0) [0|15] ""  FICM_FD
 SG_ HMIMscCntrlReq_L : 25|2@0+ (1,0) [0|3] ""  FICM_FD

BO_ 986 InfotaimentSet_SRD_R: 8 Vector__XXX
 SG_ HMIMtSw_R : 1|2@0+ (1,0) [0|3] ""  FICM_FD
 SG_ HMICallPhReq_R : 3|2@0+ (1,0) [0|3] ""  FICM_FD
 SG_ HMIVolUpAdjReq_R : 5|2@0+ (1,0) [0|3] ""  FICM_FD
 SG_ HMIVolDwAdjReq_R : 7|2@0+ (1,0) [0|3] ""  FICM_FD
 SG_ HMIMscPreAdjReq_R : 9|2@0+ (1,0) [0|3] ""  FICM_FD
 SG_ HMIMscNextAdjReq_R : 11|2@0+ (1,0) [0|3] ""  FICM_FD
 SG_ HMIVoiceReq_R : 13|2@0+ (1,0) [0|3] ""  FICM_FD
 SG_ OMSEyeCntrlReq_R : 15|2@0+ (1,0) [0|3] ""  FICM_FD
 SG_ OMSChldRfReq_R : 19|2@0+ (1,0) [0|3] ""  FICM_FD
 SG_ HMIAudioScChs_R : 23|4@0+ (1,0) [0|15] ""  FICM_FD
 SG_ HMIMscCntrlReq_R : 25|2@0+ (1,0) [0|3] ""  FICM_FD

BO_ 993 RegenerativeLvReq: 8 FICM_FD
 SG_ RgnLvReq_HMI : 2|3@0+ (1,0) [0|7] ""  Vector__XXX
 SG_ RgnLvReq_HMIV : 3|1@0+ (1,0) [0|1] ""  Vector__XXX

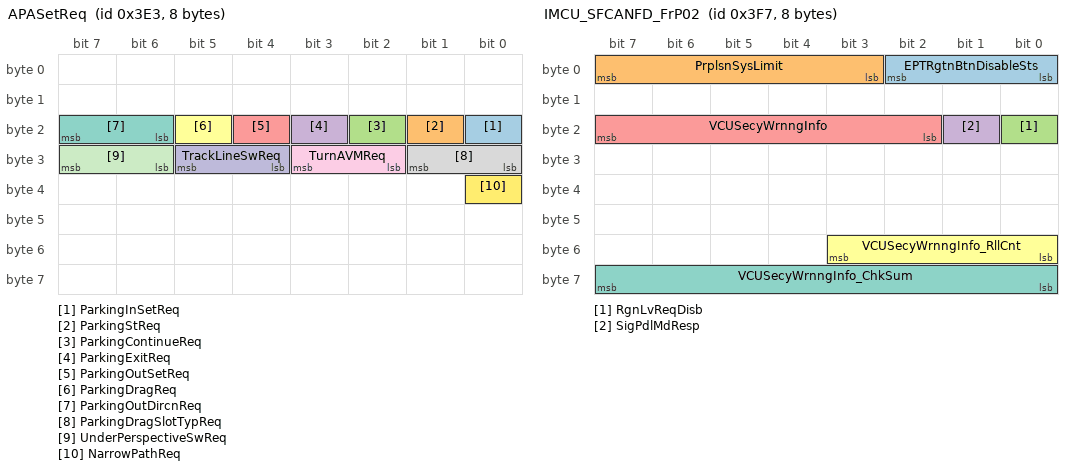
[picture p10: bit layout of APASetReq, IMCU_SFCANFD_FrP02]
BO_ 995 APASetReq: 8 FICM_FD
 SG_ ParkingInSetReq : 16|1@0+ (1,0) [0|1] ""  Vector__XXX
 SG_ ParkingStReq : 17|1@0+ (1,0) [0|1] ""  Vector__XXX
 SG_ ParkingContinueReq : 18|1@0+ (1,0) [0|1] ""  Vector__XXX
 SG_ ParkingExitReq : 19|1@0+ (1,0) [0|1] ""  Vector__XXX
 SG_ ParkingOutSetReq : 20|1@0+ (1,0) [0|1] ""  Vector__XXX
 SG_ ParkingDragReq : 21|1@0+ (1,0) [0|1] ""  Vector__XXX
 SG_ ParkingOutDircnReq : 23|2@0+ (1,0) [0|3] ""  Vector__XXX
 SG_ ParkingDragSlotTypReq : 25|2@0+ (1,0) [0|3] ""  Vector__XXX
 SG_ TurnAVMReq : 27|2@0+ (1,0) [0|3] ""  Vector__XXX
 SG_ TrackLineSwReq : 29|2@0+ (1,0) [0|3] ""  Vector__XXX
 SG_ UnderPerspectiveSwReq : 31|2@0+ (1,0) [0|3] ""  Vector__XXX
 SG_ NarrowPathReq : 32|1@0+ (1,0) [0|1] ""  Vector__XXX

BO_ 1015 IMCU_SFCANFD_FrP02: 8 Vector__XXX
 SG_ EPTRgtnBtnDisableSts : 2|3@0+ (1,0) [0|7] ""  FICM_FD
 SG_ PrplsnSysLimit : 7|5@0+ (1,0) [0|31] ""  FICM_FD
 SG_ RgnLvReqDisb : 16|1@0+ (1,0) [0|1] ""  FICM_FD
 SG_ SigPdlMdResp : 17|1@0+ (1,0) [0|1] ""  FICM_FD
 SG_ VCUSecyWrnngInfo : 23|6@0+ (1,0) [0|63] ""  FICM_FD
 SG_ VCUSecyWrnngInfo_RllCnt : 51|4@0+ (1,0) [0|15] ""  FICM_FD
 SG_ VCUSecyWrnngInfo_ChkSum : 63|8@0+ (1,0) [0|255] ""  FICM_FD

BO_ 1089 AsrNM_FICM: 8 FICM_FD
 SG_ FICM_SrcNdID : 7|8@0+ (1,0) [0|255] ""  Vector__XXX
 SG_ FICM_CBV_RMR : 8|1@0+ (1,0) [0|1] ""  Vector__XXX
 SG_ FICM_CBV_CS : 11|1@0+ (1,0) [0|1] ""  Vector__XXX
 SG_ FICM_CBV_AW : 12|1@0+ (1,0) [0|1] ""  Vector__XXX
 SG_ FICM_CBV_PNI : 14|1@0+ (1,0) [0|1] ""  Vector__XXX
 SG_ FICM_NM_BSMtoRMS : 16|1@0+ (1,0) [0|1] ""  Vector__XXX
 SG_ FICM_NM_PBSMtoRMS : 17|1@0+ (1,0) [0|1] ""  Vector__XXX
 SG_ FICM_NM_RMStoNOS : 18|1@0+ (1,0) [0|1] ""  Vector__XXX
 SG_ FICM_NM_RSStoNOS : 19|1@0+ (1,0) [0|1] ""  Vector__XXX
 SG_ FICM_NM_RSStoRMS : 20|1@0+ (1,0) [0|1] ""  Vector__XXX
 SG_ FICM_NM_NOStoRMS : 21|1@0+ (1,0) [0|1] ""  Vector__XXX
 SG_ FICM_NM_NOSSta : 22|1@0+ (1,0) [0|1] ""  Vector__XXX
 SG_ FICM_NM_RMSSta : 23|1@0+ (1,0) [0|1] ""  Vector__XXX
 SG_ FICM_UD_WR : 31|8@0+ (1,0) [0|255] ""  Vector__XXX
 SG_ FICM_UD_PNC : 39|16@0+ (1,0) [0|65535] ""  Vector__XXX
 SG_ FICM_UD_KWR_IGN : 56|1@0+ (1,0) [0|1] ""  Vector__XXX
 SG_ FICM_UD_KWR_Diag : 57|1@0+ (1,0) [0|1] ""  Vector__XXX
 SG_ FICM_UD_KWR_RMRNotExpired : 58|1@0+ (1,0) [0|1] ""  Vector__XXX
 SG_ FICM_UD_KWR_ECU_Def1 : 59|1@0+ (1,0) [0|1] ""  Vector__XXX
 SG_ FICM_UD_KWR_ECU_Def2 : 60|1@0+ (1,0) [0|1] ""  Vector__XXX
 SG_ FICM_UD_KWR_ECU_Def3 : 61|1@0+ (1,0) [0|1] ""  Vector__XXX
 SG_ FICM_UD_KWR_ECU_Def4 : 62|1@0+ (1,0) [0|1] ""  Vector__XXX
 SG_ FICM_UD_KWR_ECU_Def5 : 63|1@0+ (1,0) [0|1] ""  Vector__XXX
 SG_ FICM_UD_KWR_ECU_Def6 : 48|1@0+ (1,0) [0|1] ""  Vector__XXX
 SG_ FICM_UD_KWR_ECU_Def7 : 49|1@0+ (1,0) [0|1] ""  Vector__XXX
 SG_ FICM_UD_KWR_ECU_Def8 : 50|1@0+ (1,0) [0|1] ""  Vector__XXX
 SG_ FICM_UD_KWR_ECU_Def9 : 51|1@0+ (1,0) [0|1] ""  Vector__XXX
 SG_ FICM_UD_KWR_ECU_Def10 : 52|1@0+ (1,0) [0|1] ""  Vector__XXX
 SG_ FICM_UD_KWR_ECU_Def11 : 53|1@0+ (1,0) [0|1] ""  Vector__XXX
 SG_ FICM_UD_KWR_ECU_Def12 : 54|1@0+ (1,0) [0|1] ""  Vector__XXX
 SG_ FICM_UD_KWR_ECU_Def13 : 55|1@0+ (1,0) [0|1] ""  Vector__XXX

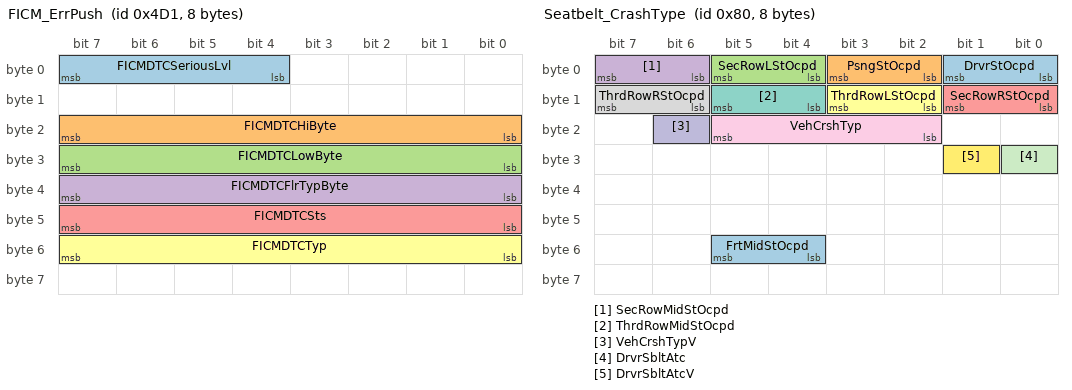
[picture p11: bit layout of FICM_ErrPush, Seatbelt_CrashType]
BO_ 1233 FICM_ErrPush: 8 FICM_FD
 SG_ FICMDTCSeriousLvl : 7|4@0+ (1,0) [0|15] ""  Vector__XXX
 SG_ FICMDTCHiByte : 23|8@0+ (1,0) [0|255] ""  Vector__XXX
 SG_ FICMDTCLowByte : 31|8@0+ (1,0) [0|255] ""  Vector__XXX
 SG_ FICMDTCFlrTypByte : 39|8@0+ (1,0) [0|255] ""  Vector__XXX
 SG_ FICMDTCSts : 47|8@0+ (1,0) [0|255] ""  Vector__XXX
 SG_ FICMDTCTyp : 55|8@0+ (1,0) [0|255] ""  Vector__XXX

BO_ 1745 FICM_Session_Status: 8 FICM_FD
 SG_ FICM_MCUDiagSession : 2|3@0+ (1,0) [0|7] ""  Vector__XXX

BO_ 1857 DiagReq_FICM: 8 Vector__XXX
 SG_ DiagReqData_FICM : 7|64@0+ (1,0) [0|18446744073709551615] ""  FICM_FD

BO_ 1969 DiagResp_FICM: 8 FICM_FD
 SG_ DiagRespData_FICM : 7|64@0+ (1,0) [0|18446744073709551615] ""  Vector__XXX

BO_ 2015 DiagReq_Func: 8 Vector__XXX
 SG_ DiagReqData_Func : 7|64@0+ (1,0) [0|18446744073709551615] ""  FICM_FD

BO_ 128 Seatbelt_CrashType: 8 Vector__XXX
 SG_ DrvrStOcpd : 1|2@0+ (1,0) [0|3] ""  FICM_FD
 SG_ PsngStOcpd : 3|2@0+ (1,0) [0|3] ""  FICM_FD
 SG_ SecRowLStOcpd : 5|2@0+ (1,0) [0|3] ""  FICM_FD
 SG_ SecRowMidStOcpd : 7|2@0+ (1,0) [0|3] ""  FICM_FD
 SG_ SecRowRStOcpd : 9|2@0+ (1,0) [0|3] ""  FICM_FD
 SG_ ThrdRowLStOcpd : 11|2@0+ (1,0) [0|3] ""  FICM_FD
 SG_ ThrdRowMidStOcpd : 13|2@0+ (1,0) [0|3] ""  FICM_FD
 SG_ ThrdRowRStOcpd : 15|2@0+ (1,0) [0|3] ""  FICM_FD
 SG_ VehCrshTyp : 21|4@0+ (1,0) [0|15] ""  FICM_FD
 SG_ VehCrshTypV : 22|1@0+ (1,0) [0|1] ""  FICM_FD
 SG_ DrvrSbltAtc : 24|1@0+ (1,0) [0|1] ""  FICM_FD
 SG_ DrvrSbltAtcV : 25|1@0+ (1,0) [0|1] ""  FICM_FD
 SG_ FrtMidStOcpd : 53|2@0+ (1,0) [0|3] ""  FICM_FD

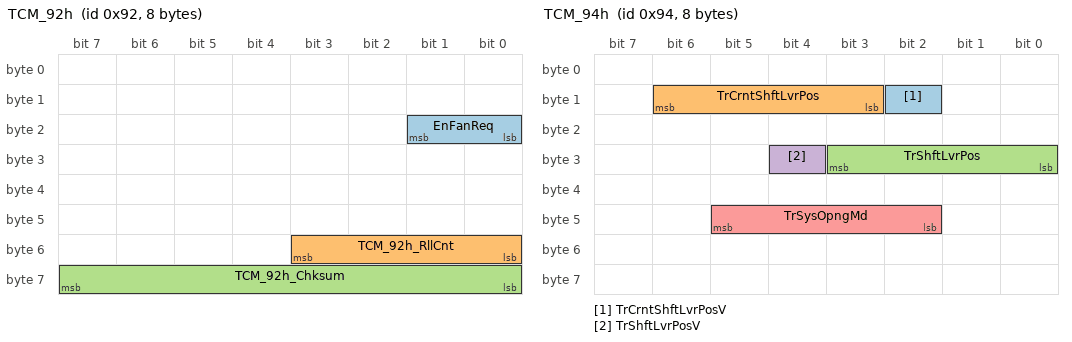
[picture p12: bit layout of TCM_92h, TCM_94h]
BO_ 146 TCM_92h: 8 Vector__XXX
 SG_ EnFanReq : 17|2@0+ (1,0) [0|3] ""  FICM_FD
 SG_ TCM_92h_RllCnt : 51|4@0+ (1,0) [0|15] ""  FICM_FD
 SG_ TCM_92h_Chksum : 63|8@0+ (1,0) [0|255] ""  FICM_FD

BO_ 148 TCM_94h: 8 Vector__XXX
 SG_ TrCrntShftLvrPosV : 10|1@0+ (1,0) [0|1] ""  FICM_FD
 SG_ TrCrntShftLvrPos : 14|4@0+ (1,0) [0|15] ""  FICM_FD
 SG_ TrShftLvrPos : 27|4@0+ (1,0) [0|15] ""  FICM_FD
 SG_ TrShftLvrPosV : 28|1@0+ (1,0) [0|1] ""  FICM_FD
 SG_ TrSysOpngMd : 45|4@0+ (1,0) [0|15] ""  FICM_FD

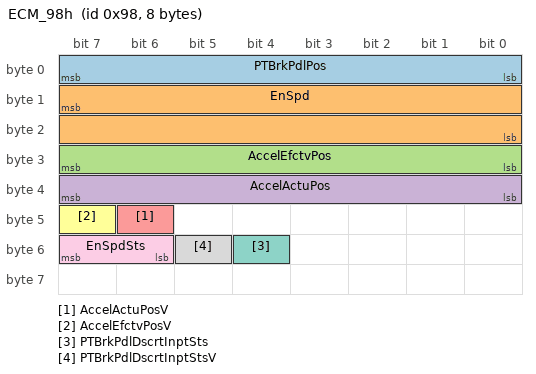
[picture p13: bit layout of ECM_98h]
BO_ 152 ECM_98h: 8 Vector__XXX
 SG_ PTBrkPdlPos : 7|8@0+ (0.4,0) [0|100] "%"  FICM_FD
 SG_ EnSpd : 15|16@0+ (0.25,0) [0|16383.75] "rpm"  FICM_FD
 SG_ AccelEfctvPos : 31|8@0+ (0.4,0) [0|100] "%"  FICM_FD
 SG_ AccelActuPos : 39|8@0+ (0.4,0) [0|100] "%"  FICM_FD
 SG_ AccelActuPosV : 46|1@0+ (1,0) [0|1] ""  FICM_FD
 SG_ AccelEfctvPosV : 47|1@0+ (1,0) [0|1] ""  FICM_FD
 SG_ PTBrkPdlDscrtInptSts : 52|1@0+ (1,0) [0|1] ""  FICM_FD
 SG_ PTBrkPdlDscrtInptStsV : 53|1@0+ (1,0) [0|1] ""  FICM_FD
 SG_ EnSpdSts : 55|2@0+ (1,0) [0|3] ""  FICM_FD

CM_ SG_ 934 StTrkAdjReq_DR "Seat_DR水平动作指令";
CM_ SG_ 934 StRtaAdjReq_DR "Seat_DR椅背动作指令";
CM_ SG_ 934 StRtaAdjReq_3rdL_FICM "Seat_3rdL椅背动作指令";
CM_ SG_ 934 StRtaAdjReq_3rdR_FICM "Seat_3rdR椅背动作指令";
CM_ SG_ 934 StHtReq_RL_HMI "Seat_RL加热命令请求（目前只用低和中）";
CM_ SG_ 934 StVtReq_RL_HMI "Seat_RL通风命令请求（目前只用低和中）";
CM_ SG_ 934 StPstrCmd_RL "Seat_RL座椅姿态命令";
CM_ SG_ 934 StHtReq_RR_HMI "Seat_RR加热命令请求（目前只用低和中）";
CM_ SG_ 934 StVtReq_RR_HMI "Seat_RR通风命令请求（目前只用低和中）";
CM_ SG_ 934 StPstrCmd_RR "Seat_RR座椅姿态命令";
CM_ SG_ 934 StLgRtaAdjReq_3rdR_FICM "Seat_3rdR腿托角度调节指令";
CM_ SG_ 934 StLgRtaAdjReq_3rdL_FICM "Seat_3rdL腿托角度调节指令";
CM_ SG_ 934 StTiltAdjReq_DR_FICM "Seat_DR前提升调节指令";
CM_ SG_ 934 StPhaAdjReq_DR_FICM "Seat_DR后提升调节指令";
CM_ SG_ 934 StSldAdjReq_RL_FICM "Seat_RL侧滑调节指令";
CM_ SG_ 934 StLgLgthAdjReq_RL_FICM "Seat_RL腿托伸展调节指令";
CM_ SG_ 934 StLgRtaAdjReq_RL_FICM "Seat_RL腿托角度调节指令";
CM_ SG_ 934 StSldAdjReq_RR_FICM "Seat_RR侧滑调节指令";
CM_ SG_ 934 StLgLgthAdjReq_RR_FICM "Seat_RR腿托伸展调节指令";
CM_ SG_ 934 StLgRtaAdjReq_RR_FICM "Seat_RR腿托角度调节指令";
CM_ SG_ 934 StHdrstAdjReq_RL_FICM "二排左头枕位置";
CM_ SG_ 934 StHdrstAdjReq_RR_FICM "二排右头枕位置";
CM_ SG_ 934 StMemCmd_RL_HMI "Seat_RL记忆命令";
CM_ SG_ 934 StMemPstnCalloutCmd_RL_HMI "Seat_RL记忆位置调出命令";
CM_ SG_ 934 StMemCmd_RR_HMI "Seat_RR记忆命令";
CM_ SG_ 934 StMemPstnCalloutCmd_RR_HMI "Seat_RR记忆位置调出命令";
CM_ SG_ 934 StPstrCmd_DR "主驾座椅姿态命令";
CM_ SG_ 934 StPstrCmd_PR "副驾座椅姿态命令";

CM_ BO_ 944 "除单 IPK 配置车型外，IPK 都不能发送！！！";
CM_ SG_ 944 ShowroomMdSts "展厅模式状态";
CM_ SG_ 944 SldDrOprtMdSt "移门模式设置";
CM_ SG_ 944 FndMyCarSet "寻车功能反馈方式";
CM_ SG_ 944 PDCBeepOffReq_R "后雷达开关";
CM_ SG_ 944 RstrFctryDfltSttngRqst "恢复出厂设置";
CM_ SG_ 944 RemoteLockingFdbckChgReq "闭锁反馈方式设置";
CM_ SG_ 944 IntLgtOprtMdSet "顶灯工作模式设置请求";
CM_ SG_ 944 VehUnLckFormSet "解锁反馈方式设置";
CM_ SG_ 944 SentryMdSetReq "哨兵模式设置";
CM_ SG_ 944 TmDsplyFmt "时间制式调节";
CM_ SG_ 944 MovingAutoLockChgReq "行车自动闭锁功能设置(预留）";
CM_ SG_ 944 LckAutoWdwClsSet "锁车自动关窗功能设置";
CM_ SG_ 944 AutoUnlockingChgReq "自动解锁设置（预留）";
CM_ SG_ 944 FolwMeHmSet "伴我回家时长设置";
CM_ SG_ 944 MrrAutoFldSet "后视镜自动折叠功能设置";
CM_ SG_ 944 WprSnstvtytSet "语音设置前雨刮灵敏度";
CM_ SG_ 944 RvsGearActvtRrWprSet "倒挡激活后雨刮功能设置";
CM_ SG_ 944 RainPrvtMdSet "雨天自动关窗设置";
CM_ SG_ 944 MemReq "外后视镜记忆";
CM_ SG_ 944 MemClrReq "外后视镜记忆清除";
CM_ SG_ 944 MemCalOtReq "外后视镜记忆调出";

CM_ SG_ 945 TempParkReq "临时停车开关";
CM_ SG_ 945 ThemeSettingAdj "主题";
CM_ SG_ 945 VehMaintenanceSts "保养提醒";
CM_ SG_ 945 DrvMdRcmdnDispReqFdbck "驾驶模式推送-用户操作反馈（ICGM）";
CM_ SG_ 945 FICMDispRcmdnInfoEnbSts "FICM弹框使能";
CM_ SG_ 945 HMIMtSwSts_L "静音状态左侧";
CM_ SG_ 945 HMICallPhReqSts "电话状态";
CM_ SG_ 945 TempParkMdSet "临时停车模式设置";
CM_ SG_ 945 HMIMtSwSts_R "静音状态右侧";
CM_ SG_ 945 IntLgtOffReq "阅读灯关闭请求";
CM_ SG_ 945 ChldLckSw_R "右侧童锁闭锁请求";
CM_ SG_ 945 LockVehRcvrMdSet "锁车回位模式设置";
CM_ SG_ 945 IntltWlcmMdSet "智能迎宾模式设置";
CM_ SG_ 945 RunPowMdAutoOffReq "超时下电开启/关闭请求信号";
CM_ SG_ 945 CPDWrnngLvl "CPD遗留报警等级";
CM_ SG_ 945 SldDrCtrlReq_R_HMI "右滑移门开门请求";
CM_ SG_ 945 ChldLckSw_L "左侧童锁闭锁请求";
CM_ SG_ 945 CPDFnSwReq "CPD功能开关请求";
CM_ SG_ 945 RunPowMdAutoOffRmndrFdbck "超时下电倒计时提醒弹框确认/取消信号";
CM_ SG_ 945 LanguageSettingAdj_2 "语言设置";

CM_ SG_ 946 HdLmpAdjReq "软开关调节大灯高度指令";
CM_ SG_ 946 VisionMdReq "Vision模式请求";
CM_ SG_ 946 TlgtOprtMdSt "尾门工作模式设置";
CM_ SG_ 946 TlgtOprtReq "尾门动作请求";
CM_ SG_ 946 PDCMainSWReq_ICU "ICU端PDC主雷达开关";
CM_ SG_ 946 ChrIndReq_HMI "FICM的充电指示灯使能设置开关";
CM_ SG_ 946 WPCEnblReq "无线充电使能信号";
CM_ SG_ 946 BkltLumSet "背光灯亮度设置";
CM_ SG_ 946 FrtFogLmpOprtMdSet "前雾灯点亮请求";
CM_ SG_ 946 HdLmpOprtMdSet "大灯软开关请求";
CM_ SG_ 946 FogLmpOprtMdSet "雾灯软开关请求(后雾灯开启，前雾灯一定开启）";
CM_ SG_ 946 PMMOFFReq "车辆下电开关(车身域）";
CM_ SG_ 946 TlgtPrkMdPosSt "尾门车库模式开度设置";
CM_ SG_ 946 MrrAutoDipSet "后视镜自动下翻功能设置";
CM_ SG_ 946 FrtWprOprtReq "语音控制前雨刮请求";
CM_ SG_ 946 FICMBssMdReq "FICM老板模式请求";
CM_ SG_ 946 PckLgtOprtMdSet "货斗灯工作模式设置";

CM_ BO_ 947 "除单 IPK 配置车型外，IPK 都不能发送！！！";
CM_ SG_ 947 HDCFnSwReq "开启/关闭HDC个性化设置请求";
CM_ SG_ 947 ESCFnSwReq "开启/关闭ESC个性化设置请求, 单IPK配置由IPK发送";
CM_ SG_ 947 EPBIgnoffAutoAppFnSwReq "开启/关闭“熄火自动夹紧”个性化设置请求";
CM_ SG_ 947 AVHFnSwReq "开启/关闭AVH个性化设置请求";
CM_ SG_ 947 EPBRlseFuSwReq "释放EPB请求";
CM_ SG_ 947 EPSCurrModReq "转向助力模式个性化设置请求
备注：多预留1个bit（为满足＞3种助力模式方案预留）";
CM_ SG_ 947 BrkFlngMdStsReq "制动踏板感模式设置请求";
CM_ SG_ 947 RGNSwReq "一键再生开关请求（只有柴油车）";
CM_ SG_ 947 FrtPsngAirbagOnOffReq "PAB(禁用副驾驶安全气囊请求)";
CM_ SG_ 947 RGNSwReqV "开始/停止再生有效性";
CM_ SG_ 947 RGNResReq "重置DPF";
CM_ SG_ 947 RGNResReqV "重置DPF有效性";
CM_ SG_ 947 ASSBtnReq "启停软开关请求状态";
CM_ SG_ 947 SBRSetReq_R "后排SBR打开关闭请求信号";
CM_ SG_ 947 RGNOkNum "基于大屏操作的原地再生成功次数累计";
CM_ SG_ 947 RGNResNum "基于大屏操作的DPF重置次数累计";
CM_ SG_ 947 WadeModeReq "涉水模式起动发动机请求";

CM_ SG_ 949 HVACOnOffSwReq_HMI "前空调开关请求信号";
CM_ SG_ 949 HVACComprOnOffSwReq_HMI "前空调压缩机开关请求信号";
CM_ SG_ 949 HVACAutoSwReq_HMI "空调自动挡开关请求";
CM_ SG_ 949 FrtDfstOnSwReq_HMI "前除霜开关请求";
CM_ SG_ 949 RrWndDfstSwReq_HMI "后除霜开关请求";
CM_ SG_ 949 HVACRcctnSwReq_HMI "空调内外循环开关请求";
CM_ SG_ 949 HVACSYNCSwReq_HMI "空调同步设置请求";
CM_ SG_ 949 FICMAirClnrUserCustAutoReq "空气净化器自动开关请求(预留，后期会用PM2.5开关代替）";
CM_ SG_ 949 HVACFLTemReq_HMI "前左区温度设置请求";
CM_ SG_ 949 HVACFRTemReq_HMI "前右区温度设置请求";
CM_ SG_ 949 HVACBlwrLvlReq_HMI "前空调风量设置请求";
CM_ SG_ 949 HVACAirMdReq_HMI "前空调风量模式请求";
CM_ SG_ 949 HVACFrtBlwrLvlupdownReq_HMI "前空调风量加减设置请求";
CM_ SG_ 949 HVACFLTemupdownReq_HMI "前空调风量加减设置请求";
CM_ SG_ 949 HVACFRTemupdownReq_HMI "前空调风量加减设置请求";
CM_ SG_ 949 HVACFRACMaxSwReq_HMI "前空调ACMax开关请求";

CM_ SG_ 950 HVACRearOnOffSwReq_HMI "后空调开关请求信号";
CM_ SG_ 950 HVACRearAutoSwReq_HMI "后空调自动挡开关请求";
CM_ SG_ 950 HVACRearAirMdReq_HMI "后空调风量模式请求";
CM_ SG_ 950 HVACRearSetTemReq_HMI "后区温度设置请求";
CM_ SG_ 950 HVACRearBlwrLvlReq_HMI "后空调风量设置请求";
CM_ SG_ 950 HVACRearBlwrLvlupdownReq_HMI "后空调风量加减设置请求";
CM_ SG_ 950 HVACRearComprOnOffSwReq_HMI "后压缩机A/C请求";
CM_ SG_ 950 HVACRearBlwr2LvlReq_HMI "后暖风空调风量设置请求
配置T07A（后冷暖一体空调）：0x0、0x5~0x9不允许发送
配置T07C（后单暖空调）：0x0、0x9不允许发送";
CM_ SG_ 950 HVACRearBlwr2LvlupdownReq_HMI "后暖风空调风量加减设置请求";
CM_ SG_ 950 RFGEngOffOprtReq "冰箱熄火保持请求";
CM_ SG_ 950 RFGOprtReq "冰箱启动/停止开关";
CM_ SG_ 950 RFGTrgtTempReq "冰箱工作的目标温度值请求E = N*1(0℃~50℃)";
CM_ SG_ 950 RFGEngOffOprtDurReq "冰箱熄火保持时长E = N (1h~24h)";
CM_ SG_ 950 RFGOprtMdReq "冰箱的工作模式请求";

CM_ SG_ 953 SldDrPos_L "左移门位置";
CM_ SG_ 953 SldDrOprtSts_L "动作状态";
CM_ SG_ 953 SldDrOprtMd_L "左移门工作模式";
CM_ SG_ 953 SldDrPosSts_L "左移门位置状态";
CM_ SG_ 953 ChldLckSts_L "左移门童锁状态";
CM_ SG_ 953 SldDrAbsAlrm_L "左移门异常提示";

CM_ SG_ 954 SldDrPos_R "右移门位置";
CM_ SG_ 954 SldDrOprtSts_R "动作状态";
CM_ SG_ 954 SldDrOprtMd_R "右移门工作模式";
CM_ SG_ 954 SldDrPosSts_R "右移门位置状态";
CM_ SG_ 954 ChldLckSts_R "右移门童锁状态";
CM_ SG_ 954 SldDrLtcSts_R "右移门锁状态";
CM_ SG_ 954 SldDrAbsAlrm_R "右移门异常提示";

CM_ SG_ 956 HMIRfLmp1Cmd "顶灯1点亮请求";
CM_ SG_ 956 Wdw_DRAutoOprtnReq "车窗DR位置调节命令";
CM_ SG_ 956 Wdw_PRAutoOprtnReq "车窗PR位置调节命令";
CM_ SG_ 956 AprchngLghtSt "迎宾灯功能个性化设置请求";
CM_ SG_ 956 IntWlcmLampSetReq "迎宾灯语设置请求";
CM_ SG_ 956 HMIRfLmp2Cmd "顶灯2点亮请求";
CM_ SG_ 956 Wdw_RLAutoOprtnReq "车窗RL位置调节命令";
CM_ SG_ 956 Wdw_RRAutoOprtnReq "车窗RR位置调节命令";
CM_ SG_ 956 DrvrFatigueReminderSetReq "疲劳驾驶提醒请求";
CM_ SG_ 956 LogoLgtOnPGearSetReq "P档点亮Logo灯设置请求";
CM_ SG_ 956 HMIRfLmp3Cmd "顶灯3点亮请求";
CM_ SG_ 956 HMIRfLmp4Cmd "顶灯4点亮请求";
CM_ SG_ 956 PSRTrgtSlct "后天窗OR遮阳帘目标选择";
CM_ SG_ 956 PSRManualOprtReq "后天窗随动控制";
CM_ SG_ 956 HMIRfLmpTrdRowCmd "三排顶灯点亮请求";
CM_ SG_ 956 PSRAutoOprtReq "后天窗&遮阳帘目标调节位置";
CM_ SG_ 956 SRFAutoOprtReq "前天窗目标调节位置";
CM_ SG_ 956 SRFManualOprtReq "前天窗随动控制";
CM_ SG_ 956 HVFuelCmd "高压油箱开启命令";
CM_ SG_ 956 TlgtOprtPosReq "尾门百分比开门请求";

CM_ SG_ 957 HybCampMdDrvrItndSOCMaxAch "Hybrid Camp Mode Driver Intended State Of Charge Maximum Achieved";
CM_ SG_ 957 HybCampMdGennPwrDsp "Hybrid Camp Mode Generation Power Display";
CM_ SG_ 957 HybCampMdDrvrItndSOCMinAch "Hybrid Camp Mode Driver Intended State Of Charge Minimum Achieved";
CM_ SG_ 957 HybCampMdDrvrItndGennLvlAch "Hybrid Camp Mode Driver Intended Generation Level ";

CM_ SG_ 958 LVDSSts "HUD LVDS状态";

CM_ SG_ 965 VehUnLckForm_VAN "解锁形式（仅VAN车用）";
CM_ SG_ 965 RainPrvtMdSts "雨天关窗功能状态";
CM_ SG_ 965 TempParkMdSetSts "临时停车模式设置状态";
CM_ SG_ 965 TempParkMode "临时停车模式状态";
CM_ SG_ 965 VehUnLckForm "解锁形式";
CM_ SG_ 965 LckFdbkSts "闭锁反馈";
CM_ SG_ 965 MrrAutoDipSts "倒车下翻功能设置反馈";
CM_ SG_ 965 MrrAutoFldSts "后视镜自动折叠功能状态";
CM_ SG_ 965 DrvrFatigueReminderSetReqFdbck "疲劳驾驶提醒请求反馈";
CM_ SG_ 965 StWelcomeSts_PR "副驾座椅迎宾状态";
CM_ SG_ 965 FlwMHmSts "伴我回家功能状态";
CM_ SG_ 965 IntltWlcmMdSts "智能迎宾模式状态";
CM_ SG_ 965 LockVehRcvrMdSts "锁车回位模式状态";
CM_ SG_ 965 FndMyCarSts "寻车反馈形式";
CM_ SG_ 965 FndMyCarTmSts "寻车响应时间";
CM_ SG_ 965 DrvMod "驾驶模式信号";
CM_ SG_ 965 DrvMdReqV "驾驶模式信号有效位";
CM_ SG_ 965 MemFdbk "记忆执行结果";
CM_ SG_ 965 MemClrFdbk "记忆清除执行结果";
CM_ SG_ 965 SnsSldDrSetReqFdbck "开启/关闭功能反馈";
CM_ SG_ 965 MovingAutoLockSts "行车自动闭锁功能设置";
CM_ SG_ 965 iBDUFctryDeftSetFnsh "恢复出厂设置和一键模式设置操作（成功）完成标志位";
CM_ SG_ 965 RunPowMdAutoOffSts "超时下电开启/关闭状态信号";
CM_ SG_ 965 RunPowMdAutoOffRmndrReq "超时下电倒计时提醒弹框请求信号";

CM_ SG_ 969 TireStsWrn_FL "左前轮压力报警";
CM_ SG_ 969 TireStsWrn_FR "右前轮压力报警";
CM_ SG_ 969 TireStsWrn_RL "左后轮压力报警";
CM_ SG_ 969 TireStsWrn_RR "右后轮压力报警";
CM_ SG_ 969 TireStsWrn_RLOS "轮胎状态异常报警_RLOS";
CM_ SG_ 969 TireStsWrn_RROS "轮胎状态异常报警_RROS";

CM_ SG_ 970 TirePrs_FL "左前轮胎压";
CM_ SG_ 970 TirePrs_FR "右前轮胎压";
CM_ SG_ 970 TirePrs_RL "左后轮胎压";
CM_ SG_ 970 TirePrs_RR "右后轮胎压";
CM_ SG_ 970 TireTmp_FL "左前轮温度";
CM_ SG_ 970 TireTmp_FR "右前轮温度";
CM_ SG_ 970 TireTmp_RL "左后轮温度";
CM_ SG_ 970 TireTmp_RR "右后轮温度";

CM_ BO_ 972 "EV&SV65、MILA项目iBDU仅发送StHtSts_DR[不发送其他信号]；其他项目保持SCM_DR发送，iBDU接收";
CM_ SG_ 972 StTrkPos_DR "Seat_DR前后位置";
CM_ SG_ 972 StTiltPos_DR "Seat_DR前提升位置";
CM_ SG_ 972 StPhaPos_DR "Seat_DR后提升位置";
CM_ SG_ 972 StRtaPos_DR "Seat_DR靠背位置";
CM_ SG_ 972 StHtSts_DR "Seat_DR加热状态";
CM_ SG_ 972 StVtSts_DR "Seat_DR通风状态";
CM_ SG_ 972 StMsgSts_DR "座椅按摩状态_DR";

CM_ BO_ 973 "EV&SV65、MILA项目iBDU仅发送StHtSts_PR[不发送其他信号]；其他项目保持SCM_PR发送，iBDU接收";
CM_ SG_ 973 StTrkPos_PR "Seat_PR前后位置";
CM_ SG_ 973 StRtaPos_PR "Seat_PR靠背位置";
CM_ SG_ 973 StHtSts_PR "Seat_PR加热状态";
CM_ SG_ 973 StMsgIntstySts_DR "座椅按摩强度_DR";
CM_ SG_ 973 StMsgIntstySts_PR "座椅按摩强度_PR";
CM_ SG_ 973 StVtSts_PR "Seat_PR通风状态";
CM_ SG_ 973 StMsgSts_PR "座椅按摩状态_PR";
CM_ SG_ 973 MemCalOtExctSts_PR "副驾座椅记忆调出执行状态反馈";

CM_ SG_ 974 StTrkPos_RL "Seat_RL水平位置";
CM_ SG_ 974 StSldPos_RL "Seat_RL侧滑位置";
CM_ SG_ 974 StRtaPos_RL "Seat_RL靠背位置";
CM_ SG_ 974 StLgRtaPos_RL "Seat_RL腿托上下位置";
CM_ SG_ 974 StLgLgthPos_RL "Seat_RL腿托伸展位置";
CM_ SG_ 974 StHdrstPos_RL "Seat_RL头枕位置";
CM_ SG_ 974 StMsgSts_RL "座椅按摩状态_RL";
CM_ SG_ 974 StMsgIntstySts_RL "座椅按摩强度_RL";

CM_ SG_ 975 StTrkPos_RR "Seat_RR水平位置";
CM_ SG_ 975 StSldPos_RR "Seat_RR侧滑位置";
CM_ SG_ 975 StRtaPos_RR "Seat_RR靠背位置";
CM_ SG_ 975 StLgRtaPos_RR "Seat_RR腿托上下位置";
CM_ SG_ 975 StLgLgthPos_RR "Seat_RR腿托伸展位置";
CM_ SG_ 975 StHdrstPos_RR "Seat_RR头枕位置";
CM_ SG_ 975 StMsgSts_RR "座椅按摩状态_RR";
CM_ SG_ 975 StMsgIntstySts_RR "座椅按摩强度_RR";

CM_ SG_ 978 PhoneRmdrReq "手机遗忘提醒";
CM_ SG_ 978 FODAlrm "异物提醒";
CM_ SG_ 978 WPCChrgSts "充电状态";

CM_ SG_ 983 SRD_LACRearSetTemReq "左扶手屏调节温度
SRD_LACRearSetTemRequest";
CM_ SG_ 983 SRD_LRearHVACAcOffSwReq "通过扶手屏控制后排空调开关请求号
SRD_LRearHVACAcOffSwRequest";
CM_ SG_ 983 SRD_LACRearBlwrLvlReq "通过扶手屏控制后空调风量请求";
CM_ SG_ 983 SRD_LACRearBlwrLvlupdownReq "通过扶手屏加减控制后空调风量（预留）";
CM_ SG_ 983 SRD_LRearAutoSwReq "通过扶手屏控制后空调自动模式开关请求";
CM_ SG_ 983 SRD_LACRearAirMdReq "通过扶手屏控制空调出风模式";
CM_ SG_ 983 StdMdReq_Lf "左扶手屏标准模式请求";
CM_ SG_ 983 RlxMdReq_Lf "左扶手屏小憩模式请求";
CM_ SG_ 983 CmfrtMdReq_Lf "左扶手屏舒畅模式请求 ";
CM_ SG_ 983 SlpMdReq_Lf "左扶手屏一键深度放松模式请求
SleepModeRequest_Left";
CM_ SG_ 983 WkMdReq_Lf "左扶手屏一键工作模式请求
WorkModeRequest_Left";
CM_ SG_ 983 WmMdReq_Lf "左扶手屏温暖模式请求";
CM_ SG_ 983 ZenMdReq_Lf "左扶手屏禅境模式请求";
CM_ SG_ 983 ClMdReq_Lf "左扶手屏清凉模式请求";
CM_ SG_ 983 MtngMdReq_Lf "左扶手屏会议模式请求";
CM_ SG_ 983 StBOSSVIP_L "座椅水平目标位置(老板按键功能)
Seat Track Position Command";

CM_ SG_ 984 SRD_RACRearSetTemReq "左扶手屏调节温度
SRD_LACRearSetTemRequest";
CM_ SG_ 984 SRD_RRearHVACAcOffSwReq "通过扶手屏控制后排空调开关请求号
SRD_LRearHVACAcOffSwRequest";
CM_ SG_ 984 SRD_RACRearBlwrLvlReq "通过扶手屏控制后空调风量请求";
CM_ SG_ 984 SRD_RACRearBlwrLvlupdownReq "通过扶手屏加减控制后空调风量（预留）";
CM_ SG_ 984 SRD_RRearAutoSwReq "通过扶手屏控制后空调自动模式开关请求";
CM_ SG_ 984 SRD_RACRearAirMdReq "通过扶手屏控制空调出风模式";
CM_ SG_ 984 StdMdReq_Rt "右扶手屏标准模式请求";
CM_ SG_ 984 RlxMdReq_Rt "右扶手屏小憩模式请求";
CM_ SG_ 984 CmfrtMdReq_Rt "右扶手屏舒畅模式请求 ";
CM_ SG_ 984 SlpMdReq_Rt "右扶手屏一键深度放松模式请求
SleepModeRequest_Left";
CM_ SG_ 984 WkMdReq_Rt "右扶手屏一键工作模式请求
WorkModeRequest_Left";
CM_ SG_ 984 WmMdReq_Rt "右扶手屏温暖模式请求";
CM_ SG_ 984 ZenMdReq_Rt "右扶手屏禅境模式请求";
CM_ SG_ 984 ClMdReq_Rt "右扶手屏清凉模式请求";
CM_ SG_ 984 MtngMdReq_Rt "右扶手屏会议模式请求";
CM_ SG_ 984 SmkMdReq_Rt "右扶手屏一键抽烟（通风）模式请求
SmokingModeRequest_Left";
CM_ SG_ 984 StBOSSVIP_R "座椅靠背目标位置(老板按键功能)
Seat Rotation Position Command";

CM_ SG_ 985 HMIMtSw_L "HMIMuteSwitch";
CM_ SG_ 985 HMICallPhReq_L "HMICall the PhoneRequest";
CM_ SG_ 985 HMIVolUpAdjReq_L "HMIVolumeAdjustment(音量增加）(开环）（需要UI设计时，
无需考虑状态变化，只做成加减 与方控保持一致）";
CM_ SG_ 985 HMIVolDwAdjReq_L "HMIVolumeAdjustment(音量减少）(开环）";
CM_ SG_ 985 HMIMscPreAdjReq_L "HMIMusicAdj(音乐上一首）(开环）";
CM_ SG_ 985 HMIMscNextAdjReq_L "HMIMusicAdj(音乐下一首）(开环）";
CM_ SG_ 985 HMIVoiceReq_L "语音识别开关请求（预留）(开环）";
CM_ SG_ 985 OMSEyeCntrlReq_L "OMS眼动开关个性化设置（左扶手屏)
OMSEyeControlRequest";
CM_ SG_ 985 HMIAudioScChs_L "音源选择切换请求";
CM_ SG_ 985 HMIMscCntrlReq_L "音乐暂停/播放请求";

CM_ SG_ 986 HMIMtSw_R "HMIMuteSwitch";
CM_ SG_ 986 HMICallPhReq_R "HMICall the PhoneRequest";
CM_ SG_ 986 HMIVolUpAdjReq_R "HMIVolumeAdjustment(音量增加）(开环）（需要UI设计时，
无需考虑状态变化，只做成加减 与方控保持一致）";
CM_ SG_ 986 HMIVolDwAdjReq_R "HMIVolumeAdjustment(音量减少）(开环）";
CM_ SG_ 986 HMIMscPreAdjReq_R "HMIMusicAdj(音乐上一首）(开环）";
CM_ SG_ 986 HMIMscNextAdjReq_R "HMIMusicAdj(音乐下一首）(开环）";
CM_ SG_ 986 HMIVoiceReq_R "语音识别开关请求（预留）(开环）";
CM_ SG_ 986 OMSEyeCntrlReq_R "OMS眼动开关个性化设置（左扶手屏)
OMSEyeControlRequest";
CM_ SG_ 986 OMSChldRfReq_R "OMS儿童遗留功能开关请求
OMSChildLeftRequest";
CM_ SG_ 986 HMIAudioScChs_R "音源选择切换请求";
CM_ SG_ 986 HMIMscCntrlReq_R "音乐暂停/播放请求";

CM_ SG_ 995 ParkingInSetReq "FICM发送进入泊入界面请求";
CM_ SG_ 995 ParkingStReq "FICM发送泊车界面泊车开始请求";
CM_ SG_ 995 ParkingContinueReq "FICM发送泊车界面泊车继续请求";
CM_ SG_ 995 ParkingExitReq "FICM发送泊车界面泊车退出请求";
CM_ SG_ 995 ParkingOutSetReq "FICM发送泊车泊出界面请求";
CM_ SG_ 995 ParkingDragReq "FICM发送泊车界面拖拽泊车请求";
CM_ SG_ 995 ParkingOutDircnReq "FICM发送泊出方向请求";
CM_ SG_ 995 ParkingDragSlotTypReq "FICM发送拖拽车位类型请求";
CM_ SG_ 995 TurnAVMReq "转向触发全景请求";
CM_ SG_ 995 TrackLineSwReq "轨迹线开关请求";
CM_ SG_ 995 UnderPerspectiveSwReq "车底透视请求";
CM_ SG_ 995 NarrowPathReq "窄路通行开关请求";

CM_ SG_ 1015 PrplsnSysLimit "仪表文字提示";
CM_ SG_ 1015 SigPdlMdResp "单踏板开启状态";

CM_ SG_ 1089 FICM_NM_BSMtoRMS "CAN网络管理状态从总线睡眠模式进入重复消息状态";
CM_ SG_ 1089 FICM_NM_PBSMtoRMS "CAN网络管理状态从总线预睡眠模式进入重复消息状态";
CM_ SG_ 1089 FICM_NM_RMStoNOS "CAN网络管理状态从重复消息状态进入正常运行状态";
CM_ SG_ 1089 FICM_NM_RSStoNOS "CAN网络管理状态从准备睡眠状态进入正常运行状态";
CM_ SG_ 1089 FICM_NM_RSStoRMS "CAN网络管理状态从准备睡眠状态进入重复消息状态";
CM_ SG_ 1089 FICM_NM_NOStoRMS "CAN网络管理状态从正常运行状态进入重复消息状态";
CM_ SG_ 1089 FICM_NM_NOSSta "CAN网络管理处于正常运行状态";
CM_ SG_ 1089 FICM_NM_RMSSta "CAN网络管理处于重复消息状态";
CM_ SG_ 1089 FICM_UD_WR "指示ECU 的唤醒原因";
CM_ SG_ 1089 FICM_UD_KWR_IGN "指示ECU 保持唤醒的原因：电源模式";
CM_ SG_ 1089 FICM_UD_KWR_Diag "指示ECU 保持唤醒的原因：诊断";
CM_ SG_ 1089 FICM_UD_KWR_RMRNotExpired "指示ECU 保持唤醒的原因：重复消息时间未到期";
CM_ SG_ 1089 FICM_UD_KWR_ECU_Def1 "指示ECU 保持唤醒的原因：ECU定义1";
CM_ SG_ 1089 FICM_UD_KWR_ECU_Def2 "指示ECU 保持唤醒的原因：ECU定义2";
CM_ SG_ 1089 FICM_UD_KWR_ECU_Def3 "指示ECU 保持唤醒的原因：ECU定义3";
CM_ SG_ 1089 FICM_UD_KWR_ECU_Def4 "指示ECU 保持唤醒的原因：ECU定义4";
CM_ SG_ 1089 FICM_UD_KWR_ECU_Def5 "指示ECU 保持唤醒的原因：ECU定义5";
CM_ SG_ 1089 FICM_UD_KWR_ECU_Def6 "指示ECU 保持唤醒的原因：ECU定义6";
CM_ SG_ 1089 FICM_UD_KWR_ECU_Def7 "指示ECU 保持唤醒的原因：ECU定义7";
CM_ SG_ 1089 FICM_UD_KWR_ECU_Def8 "指示ECU 保持唤醒的原因：ECU定义8";
CM_ SG_ 1089 FICM_UD_KWR_ECU_Def9 "指示ECU 保持唤醒的原因：ECU定义9";
CM_ SG_ 1089 FICM_UD_KWR_ECU_Def10 "指示ECU 保持唤醒的原因：ECU定义10";
CM_ SG_ 1089 FICM_UD_KWR_ECU_Def11 "指示ECU 保持唤醒的原因：ECU定义11";
CM_ SG_ 1089 FICM_UD_KWR_ECU_Def12 "指示ECU 保持唤醒的原因：ECU定义12";
CM_ SG_ 1089 FICM_UD_KWR_ECU_Def13 "指示ECU 保持唤醒的原因：ECU定义13";

CM_ SG_ 1233 FICMDTCSeriousLvl "具体信号定义可参考诊断技术规范";
CM_ SG_ 1233 FICMDTCHiByte "具体信号定义可参考诊断技术规范";
CM_ SG_ 1233 FICMDTCLowByte "具体信号定义可参考诊断技术规范";
CM_ SG_ 1233 FICMDTCFlrTypByte "具体信号定义可参考诊断技术规范";
CM_ SG_ 1233 FICMDTCSts "具体信号定义可参考诊断技术规范";
CM_ SG_ 1233 FICMDTCTyp "具体信号定义可参考诊断技术规范";

CM_ SG_ 1857 DiagReqData_FICM "诊断请求物理寻址";

CM_ SG_ 1969 DiagRespData_FICM "诊断响应";

CM_ SG_ 2015 DiagReqData_Func "诊断请求功能寻址";

CM_ SG_ 128 VehCrshTyp "Vehicle Crash Type";
CM_ SG_ 128 DrvrSbltAtc "Driver Seatbelt buckle Switch Status";
CM_ SG_ 128 DrvrSbltAtcV "Driver Seatbelt buckle Switch Status Validity";
CM_ SG_ 128 FrtMidStOcpd "前排中间座占位信号";

CM_ SG_ 146 EnFanReq "This signal is transmitted by powertrain control unit TCM. It stands for the cooling requirement from transmission side. For PWM type cooling fan, it stands for the duty ratio output requirement.";

CM_ SG_ 148 TrCrntShftLvrPosV "Validity of the Trasmission Current Shift Lever Position。";
CM_ SG_ 148 TrCrntShftLvrPos "It represents the actual shift level positon. ";
CM_ SG_ 148 TrShftLvrPos "Transmission Shift Lever Position provides an indication of the state of the transmission lever position as selected by the driver. In automatic transmissions, vehicle standards define the order of ranges to be Park, Reverse and Neutral, followed by one or more forward ranges. If powertrain detects that the transmission shift lever system is between states, this signal shall be set to Between Ranges.
In vehicle using Electronic Range Selection (Tap Up/Down Mode Request is set to 'Enable Electronic Range Select') this signal will reflect the forward range selected by the driver by ERS switches.
The IPK shall use this signal for displaying the range selected.";
CM_ SG_ 148 TrShftLvrPosV "If any diagnostics determine that the sensor information used to create Transmission Shift Lever Position is unreliable and a corresponding emissions related DTC has been set, this signal shall be set to Invalid.";

CM_ SG_ 152 PTBrkPdlPos "This signal is received by powertrain control unit TCM. It is used by creep control function and neutral idle control function.";
CM_ SG_ 152 EnSpd "This signal is transmitted by powertrain control unit ECM. It represents the unfiltered, high resolution engine speed in revolutions per minute, determined from the engine sensors available.";
CM_ SG_ 152 AccelEfctvPos "This signal is transmitted by the ECM. It represents
the larger of the driver request via the accelerator
pedal (pedal position, mode switches and other
parameters as well as filtering) and vehicle speed
control request. When cruise control is active, this
signal is calculated based on cruise torque requirement. When cruise control is not active, this signal equals to “Accelerator Actual Position”.If “Accelerator Actual Position Validity” is “Invalid”,
“Accelerator Effective Position” should always be “0”";
CM_ SG_ 152 AccelActuPos "Accelerator Actual Position” will not be used by ECM to honor driver's torque request, but will be used to control the throttle position in KL15 state.Throttle position should have linear relationship with accelerator pedal position.When the validity flag is received as “Invalid”, ECM should consider “Accelerator Actual Postion”as 0. ";
CM_ SG_ 152 AccelActuPosV "When either one sensor input failure or two sensor
inputs are not coherent, “Electric Powertrain
Accelerator Actual Position Validity” will be set to 'Invalid'. “Electric Powertrain Accelerator Actual Position” should always be 0 in this situation. ";
CM_ SG_ 152 AccelEfctvPosV "Accelerator Effective Position Validty( to ADAS)";
CM_ SG_ 152 PTBrkPdlDscrtInptSts "Powertrain Brake Pedal Discrete Input Status
The ECM shall report the state of the hardwire brake switch input through this signal. This signal only indicates whether the brake pedal has been applied, and it is not necessarily indicative of the state of the stop lamps.";
CM_ SG_ 152 PTBrkPdlDscrtInptStsV "If ECM detects the incoherency error of the brake switches input, the validity flag should be set to
“Invalid”. At the same time, “Electric Powertrain Brake
Pedal Discrete Input Status” should be set to “Brake
Applied”.";
CM_ SG_ 152 EnSpdSts "This signal is transmitted by powertrain control unit ECM. It should be used together with Engine Speed.
Degraded Operation:
This signal should be set to “Degraded Operation” if a
diagnostic code is set for the primary sensor providing
the data and a backup value is being calculated from
other than the primary sensor. Primary sensor is used to be crankshaft position sensor and backup sensor is used to be camshaft position sensor.
Normal Operation:
It will be set to “Normal Operation” when the ECM has not determined that there are diagnostic faults of the engine speed sensor or engine speed system.
Invalid:
It should be set to “Invalid” if the diagnostic code is set
for the primary sensor, and no backup value is available or backup sensor is also failure.";
BA_DEF_ SG_  "GenSigTimeoutValue" INT 0 65535;
BA_DEF_ BO_  "DiagState" ENUM  "no","yes";
BA_DEF_ BO_  "GenMsgNrOfRepetition" INT 0 65535;
BA_DEF_ BO_  "GenMsgSendType" ENUM  "Cyclic","NotUsed","NotUsed","NotUsed","NotUsed","NotUsed","NotUsed","IfActive","NoMsgSendType","NotUsed";
BA_DEF_ SG_  "SignalLongName" STRING ;
BA_DEF_ BO_  "VFrameFormat" ENUM  "StandardCAN","ExtendedCAN","reserved","J1939PG","reserved","reserved","reserved","reserved","reserved","reserved","reserved","reserved","reserved","reserved","StandardCAN_FD","ExtendedCAN_FD";
BA_DEF_ BO_  "NmMessage" ENUM  "no","yes";
BA_DEF_ BO_  "GenMsgDelayTime" INT 0 65535;
BA_DEF_ BO_  "GenMsgILSupport" ENUM  "no","yes";
BA_DEF_ BO_  "GenMsgStartDelayTime" INT 0 65535;
BA_DEF_ BO_  "NmAsrMessage" ENUM  "no","yes";
BA_DEF_ BO_  "DiagRequest" ENUM  "no","yes";
BA_DEF_ BO_  "DiagResponse" ENUM  "no","yes";
BA_DEF_ BO_  "GenMsgCycleTimeFast" INT 0 65535;
BA_DEF_ BO_  "GenMsgCycleTime" INT 0 30000;
BA_DEF_ SG_  "GenSigStartValue" INT 0 65535;
BA_DEF_ SG_  "GenSigInactiveValue" HEX 0 65535;
BA_DEF_ SG_  "GenSigSendType" ENUM  "Cyclic","OnWrite","OnWriteWithRepetition","OnChange","OnChangeWithRepetition","IfActive","IfActiveWithRepetition","NoSigSendType","OnChangeAndIfActive","OnChangeAndIfActiveWithRepetition";
BA_DEF_REL_ BU_SG_REL_  "GenSigTimeoutTime" INT 0 65535;
BA_DEF_DEF_  "GenSigTimeoutValue" 0;
BA_DEF_DEF_  "DiagState" "no";
BA_DEF_DEF_  "GenMsgNrOfRepetition" 0;
BA_DEF_DEF_  "GenMsgSendType" "NoMsgSendType";
BA_DEF_DEF_  "SignalLongName" "";
BA_DEF_DEF_  "VFrameFormat" "StandardCAN";
BA_DEF_DEF_  "NmMessage" "no";
BA_DEF_DEF_  "GenMsgDelayTime" 0;
BA_DEF_DEF_  "GenMsgILSupport" "no";
BA_DEF_DEF_  "GenMsgStartDelayTime" 0;
BA_DEF_DEF_  "NmAsrMessage" "no";
BA_DEF_DEF_  "DiagRequest" "no";
BA_DEF_DEF_  "DiagResponse" "no";
BA_DEF_DEF_  "GenMsgCycleTimeFast" 0;
BA_DEF_DEF_  "GenMsgCycleTime" 0;
BA_DEF_DEF_  "GenSigStartValue" 0;
BA_DEF_DEF_  "GenSigInactiveValue" 0;
BA_DEF_DEF_  "GenSigSendType" "NoSigSendType";
BA_DEF_DEF_REL_ "GenSigTimeoutTime" 0;

BA_ "GenMsgSendType" BO_ 934 0;
BA_ "GenMsgStartDelayTime" BO_ 934 20;
BA_ "GenMsgCycleTime" BO_ 934 500;
BA_ "GenMsgILSupport" BO_ 934 1;
BA_ "GenMsgCycleTimeFast" BO_ 934 40;
BA_ "GenMsgNrOfRepetition" BO_ 934 3;
BA_ "GenMsgDelayTime" BO_ 934 20;
BA_ "VFrameFormat" BO_ 934 14;

BA_ "GenSigSendType" SG_ 934 StTrkAdjReq_DR 4;
BA_ "SignalLongName" SG_ 934 StTrkAdjReq_DR "Seat Track Adjust Request_DR";

BA_ "GenSigSendType" SG_ 934 StRtaAdjReq_DR 4;
BA_ "SignalLongName" SG_ 934 StRtaAdjReq_DR "Seat Rotation Adjust Request_DR";

BA_ "GenSigSendType" SG_ 934 StRtaAdjReq_3rdL_FICM 4;
BA_ "SignalLongName" SG_ 934 StRtaAdjReq_3rdL_FICM "Seat Rotation Adjust Request_3rdL";

BA_ "GenSigSendType" SG_ 934 StRtaAdjReq_3rdR_FICM 4;
BA_ "SignalLongName" SG_ 934 StRtaAdjReq_3rdR_FICM "Seat Rotation Adjust Request_3rdR";

BA_ "GenSigSendType" SG_ 934 StHtReq_RL_HMI 4;
BA_ "SignalLongName" SG_ 934 StHtReq_RL_HMI "SeatHeatRequest_RL_HMI";

BA_ "GenSigSendType" SG_ 934 StVtReq_RL_HMI 4;
BA_ "SignalLongName" SG_ 934 StVtReq_RL_HMI "SeatVentRequest_RL_HMI";

BA_ "GenSigSendType" SG_ 934 StPstrCmd_RL 4;
BA_ "SignalLongName" SG_ 934 StPstrCmd_RL "Seat_RLPostureCommamd";

BA_ "GenSigSendType" SG_ 934 StHtReq_RR_HMI 4;
BA_ "SignalLongName" SG_ 934 StHtReq_RR_HMI "SeatHeatRequest_RR_HMI";

BA_ "GenSigSendType" SG_ 934 StVtReq_RR_HMI 4;
BA_ "SignalLongName" SG_ 934 StVtReq_RR_HMI "SeatVentRequest_RR_HMI";

BA_ "GenSigSendType" SG_ 934 StPstrCmd_RR 4;
BA_ "SignalLongName" SG_ 934 StPstrCmd_RR "Seat_RRPostureCommamd";

BA_ "GenSigSendType" SG_ 934 StLgRtaAdjReq_3rdR_FICM 4;
BA_ "SignalLongName" SG_ 934 StLgRtaAdjReq_3rdR_FICM "Seat Legsupport Rotation Adjust Request_3rdR";

BA_ "GenSigSendType" SG_ 934 StLgRtaAdjReq_3rdL_FICM 4;
BA_ "SignalLongName" SG_ 934 StLgRtaAdjReq_3rdL_FICM "Seat Legsupport Rotation Adjust Request_3rdL";

BA_ "GenSigSendType" SG_ 934 StTiltAdjReq_DR_FICM 4;
BA_ "SignalLongName" SG_ 934 StTiltAdjReq_DR_FICM "Seat Tilt Adjust Request_DR";

BA_ "GenSigSendType" SG_ 934 StPhaAdjReq_DR_FICM 4;
BA_ "SignalLongName" SG_ 934 StPhaAdjReq_DR_FICM "Seat Pha Adjust Request_DR";

BA_ "GenSigSendType" SG_ 934 StSldAdjReq_RL_FICM 4;
BA_ "SignalLongName" SG_ 934 StSldAdjReq_RL_FICM "Seat Slide Adjust Request_RL";

BA_ "GenSigSendType" SG_ 934 StLgLgthAdjReq_RL_FICM 4;
BA_ "SignalLongName" SG_ 934 StLgLgthAdjReq_RL_FICM "Seat Legsupport Length Adjust Request_RL";

BA_ "GenSigSendType" SG_ 934 StLgRtaAdjReq_RL_FICM 4;
BA_ "SignalLongName" SG_ 934 StLgRtaAdjReq_RL_FICM "Seat Legsupport Rotation Adjust Request_RL";

BA_ "GenSigSendType" SG_ 934 StSldAdjReq_RR_FICM 4;
BA_ "SignalLongName" SG_ 934 StSldAdjReq_RR_FICM "Seat Slide Adjust Request_RR";

BA_ "GenSigSendType" SG_ 934 StLgLgthAdjReq_RR_FICM 4;
BA_ "SignalLongName" SG_ 934 StLgLgthAdjReq_RR_FICM "Seat Legsupport Length Adjust Request_RR";

BA_ "GenSigSendType" SG_ 934 StLgRtaAdjReq_RR_FICM 4;
BA_ "SignalLongName" SG_ 934 StLgRtaAdjReq_RR_FICM "Seat Legsupport Rotation Adjust Request_RR";

BA_ "GenSigSendType" SG_ 934 StHdrstAdjReq_RL_FICM 4;
BA_ "SignalLongName" SG_ 934 StHdrstAdjReq_RL_FICM "Seat Headrest Adjust Request_RL_FICM";

BA_ "GenSigSendType" SG_ 934 StHdrstAdjReq_RR_FICM 4;
BA_ "SignalLongName" SG_ 934 StHdrstAdjReq_RR_FICM "Seat Headrest Adjust Request_RR_FICM";

BA_ "GenSigSendType" SG_ 934 StMemCmd_RL_HMI 4;
BA_ "SignalLongName" SG_ 934 StMemCmd_RL_HMI "SeatMemoryCommand_RL_HMI";

BA_ "GenSigSendType" SG_ 934 StMemPstnCalloutCmd_RL_HMI 4;
BA_ "SignalLongName" SG_ 934 StMemPstnCalloutCmd_RL_HMI "SeatMemoryPositionCalloutCommamd_RL_HMI";

BA_ "GenSigSendType" SG_ 934 StMemCmd_RR_HMI 4;
BA_ "SignalLongName" SG_ 934 StMemCmd_RR_HMI "SeatMemoryCommand_RR_HMI";

BA_ "GenSigSendType" SG_ 934 StMemPstnCalloutCmd_RR_HMI 4;
BA_ "SignalLongName" SG_ 934 StMemPstnCalloutCmd_RR_HMI "SeatMemoryPositionCalloutCommamd_RR_HMI";

BA_ "GenSigSendType" SG_ 934 StPstrCmd_DR 4;
BA_ "SignalLongName" SG_ 934 StPstrCmd_DR "Seat_DRPostureCommamd";

BA_ "GenSigSendType" SG_ 934 StPstrCmd_PR 4;
BA_ "SignalLongName" SG_ 934 StPstrCmd_PR "Seat_PRPostureCommamd";

BA_ "GenMsgSendType" BO_ 943 0;
BA_ "GenMsgStartDelayTime" BO_ 943 20;
BA_ "GenMsgCycleTime" BO_ 943 500;
BA_ "GenMsgILSupport" BO_ 943 1;
BA_ "GenMsgCycleTimeFast" BO_ 943 40;
BA_ "GenMsgNrOfRepetition" BO_ 943 3;
BA_ "GenMsgDelayTime" BO_ 943 20;
BA_ "VFrameFormat" BO_ 943 14;

BA_ "GenSigSendType" SG_ 943 StMsgReq_RL_HMI 4;
BA_ "SignalLongName" SG_ 943 StMsgReq_RL_HMI "Seat Massage Request_RL_HMI";

BA_ "GenSigSendType" SG_ 943 StMsgReq_RR_HMI 4;
BA_ "SignalLongName" SG_ 943 StMsgReq_RR_HMI "Seat Massage Request_RR_HMI";

BA_ "GenSigSendType" SG_ 943 StMsgIntstyReq_RL_HMI 4;
BA_ "SignalLongName" SG_ 943 StMsgIntstyReq_RL_HMI "Seat Massage Intensity Request_RL_HMI";

BA_ "GenSigSendType" SG_ 943 StMsgIntstyReq_RR_HMI 4;
BA_ "SignalLongName" SG_ 943 StMsgIntstyReq_RR_HMI "Seat Massage Intensity Request_RR_HMI";

BA_ "GenMsgSendType" BO_ 944 0;
BA_ "GenMsgStartDelayTime" BO_ 944 10;
BA_ "GenMsgCycleTime" BO_ 944 500;
BA_ "GenMsgILSupport" BO_ 944 1;
BA_ "GenMsgCycleTimeFast" BO_ 944 40;
BA_ "GenMsgNrOfRepetition" BO_ 944 3;
BA_ "GenMsgDelayTime" BO_ 944 20;
BA_ "VFrameFormat" BO_ 944 14;

BA_ "GenSigSendType" SG_ 944 SnsSldDrSetReq 4;
BA_ "SignalLongName" SG_ 944 SnsSldDrSetReq "Sensing Sliding Door Set Request";

BA_ "GenSigSendType" SG_ 944 SnsSldDrActnTypSetReq 4;
BA_ "SignalLongName" SG_ 944 SnsSldDrActnTypSetReq "Sensing Sliding Door Action Type Set Req";

BA_ "GenSigSendType" SG_ 944 PDCBeepOffReq_F 4;
BA_ "SignalLongName" SG_ 944 PDCBeepOffReq_F "PDC Beep Off Request_Rear";

BA_ "GenSigSendType" SG_ 944 ShowroomMdSts 0;
BA_ "SignalLongName" SG_ 944 ShowroomMdSts "Showroom Mode Status";

BA_ "GenSigSendType" SG_ 944 StWelcomeSet_PR 4;
BA_ "SignalLongName" SG_ 944 StWelcomeSet_PR "Seat Welcome Set_PR";

BA_ "GenSigSendType" SG_ 944 SldDrOprtMdSt 4;
BA_ "SignalLongName" SG_ 944 SldDrOprtMdSt "Sliding Door Operation Mode Set";

BA_ "GenSigSendType" SG_ 944 FndMyCarSet 4;
BA_ "SignalLongName" SG_ 944 FndMyCarSet "Find My Car Feedback Mode Set";

BA_ "GenSigSendType" SG_ 944 PDCBeepOffReq_R 4;
BA_ "SignalLongName" SG_ 944 PDCBeepOffReq_R "PDC Beep Off Request_Front";

BA_ "GenSigSendType" SG_ 944 RstrFctryDfltSttngRqst 4;
BA_ "SignalLongName" SG_ 944 RstrFctryDfltSttngRqst "Restore Factory Default Setting Request";

BA_ "GenSigSendType" SG_ 944 RemoteLockingFdbckChgReq 4;
BA_ "SignalLongName" SG_ 944 RemoteLockingFdbckChgReq "RemoteLockingFeedbackChangeRequest";

BA_ "GenSigSendType" SG_ 944 IntLgtOprtMdSet 4;
BA_ "SignalLongName" SG_ 944 IntLgtOprtMdSet "Interior Lighting Mode Set";

BA_ "GenSigSendType" SG_ 944 VehUnLckFormSet 4;
BA_ "SignalLongName" SG_ 944 VehUnLckFormSet "Vehicle Unlock Form Set";

BA_ "GenSigSendType" SG_ 944 SentryMdSetReq 4;
BA_ "SignalLongName" SG_ 944 SentryMdSetReq "Sentry Mode Set Request";

BA_ "GenSigSendType" SG_ 944 TmDsplyFmt 0;
BA_ "SignalLongName" SG_ 944 TmDsplyFmt "TimeDisplayFomat";

BA_ "GenSigSendType" SG_ 944 MovingAutoLockChgReq 4;
BA_ "SignalLongName" SG_ 944 MovingAutoLockChgReq "MovingAutoLockChangeRequest";

BA_ "GenSigSendType" SG_ 944 LanguageSettingAdj 0;
BA_ "SignalLongName" SG_ 944 LanguageSettingAdj "LanguageSettingAdjustment";

BA_ "GenSigSendType" SG_ 944 DrvMdReq_HMI 4;
BA_ "SignalLongName" SG_ 944 DrvMdReq_HMI "DriveModeRequestHMI";

BA_ "GenSigSendType" SG_ 944 LckAutoWdwClsSet 4;
BA_ "SignalLongName" SG_ 944 LckAutoWdwClsSet "Lock Auto Window Close Function Set";

BA_ "GenSigSendType" SG_ 944 AutoUnlockingChgReq 4;
BA_ "SignalLongName" SG_ 944 AutoUnlockingChgReq "AutoUnlockingChangeRequest";

BA_ "GenSigSendType" SG_ 944 FolwMeHmSet 4;
BA_ "SignalLongName" SG_ 944 FolwMeHmSet "Follow Me Home Function Set";

BA_ "GenSigSendType" SG_ 944 MrrAutoFldSet 4;
BA_ "SignalLongName" SG_ 944 MrrAutoFldSet "Mirror Auto Fold Function Set";

BA_ "GenSigSendType" SG_ 944 WprSnstvtytSet 4;
BA_ "SignalLongName" SG_ 944 WprSnstvtytSet "Front Wiper Sensitivity Set";

BA_ "GenSigSendType" SG_ 944 RvsGearActvtRrWprSet 4;
BA_ "SignalLongName" SG_ 944 RvsGearActvtRrWprSet "Reverse Gear Activate Rear Wiper Function Set";

BA_ "GenSigSendType" SG_ 944 RainPrvtMdSet 4;
BA_ "SignalLongName" SG_ 944 RainPrvtMdSet "Rain Prevent Mode Set";

BA_ "GenSigSendType" SG_ 944 MemReq 4;
BA_ "SignalLongName" SG_ 944 MemReq "Memorize Request";

BA_ "GenSigSendType" SG_ 944 MemClrReq 4;
BA_ "SignalLongName" SG_ 944 MemClrReq "Memorize Clear Request";

BA_ "GenSigSendType" SG_ 944 MemCalOtReq 4;
BA_ "SignalLongName" SG_ 944 MemCalOtReq "Memorization Call Out Request";

BA_ "GenMsgSendType" BO_ 945 0;
BA_ "GenMsgStartDelayTime" BO_ 945 10;
BA_ "GenMsgCycleTime" BO_ 945 500;
BA_ "GenMsgILSupport" BO_ 945 1;
BA_ "GenMsgCycleTimeFast" BO_ 945 40;
BA_ "GenMsgNrOfRepetition" BO_ 945 3;
BA_ "GenMsgDelayTime" BO_ 945 20;
BA_ "VFrameFormat" BO_ 945 14;

BA_ "GenSigSendType" SG_ 945 FICMOverSpdThreshholdVal 4;
BA_ "SignalLongName" SG_ 945 FICMOverSpdThreshholdVal "FICM Over Speed Threshhold Value";

BA_ "GenSigSendType" SG_ 945 TempParkReq 4;
BA_ "SignalLongName" SG_ 945 TempParkReq "Temporary Park Request";

BA_ "GenSigSendType" SG_ 945 ThemeSettingAdj 0;
BA_ "SignalLongName" SG_ 945 ThemeSettingAdj "ThemeSettingAdjustment";

BA_ "GenSigSendType" SG_ 945 VehMaintenanceSts 0;
BA_ "SignalLongName" SG_ 945 VehMaintenanceSts "Vehicle Maintenance Status";

BA_ "GenSigSendType" SG_ 945 FICMOverSpdSwitchReq 4;
BA_ "SignalLongName" SG_ 945 FICMOverSpdSwitchReq "FICM Over Speed Switch Request";

BA_ "GenSigSendType" SG_ 945 DrvMdRcmdnDispReqFdbck 4;
BA_ "SignalLongName" SG_ 945 DrvMdRcmdnDispReqFdbck "Drive Mode Recommendation Display Request Feedback";

BA_ "GenSigSendType" SG_ 945 FICMDispRcmdnInfoEnbSts 4;
BA_ "SignalLongName" SG_ 945 FICMDispRcmdnInfoEnbSts "FICM Display Recommendation Information Enable Status";
BA_ "GenSigStartValue" SG_ 945 FICMDispRcmdnInfoEnbSts 1;

BA_ "GenSigSendType" SG_ 945 HMIMtSwSts_L 0;
BA_ "SignalLongName" SG_ 945 HMIMtSwSts_L "HMIMuteSwitchStatus Left";
BA_ "GenSigStartValue" SG_ 945 HMIMtSwSts_L 1;

BA_ "GenSigSendType" SG_ 945 HMICallPhReqSts 0;
BA_ "SignalLongName" SG_ 945 HMICallPhReqSts "HMICall the PhoneRequestStatus";
BA_ "GenSigStartValue" SG_ 945 HMICallPhReqSts 1;

BA_ "GenSigSendType" SG_ 945 TempParkMdSet 4;
BA_ "SignalLongName" SG_ 945 TempParkMdSet "Temporary Park Mode Set";

BA_ "GenSigSendType" SG_ 945 HMIMtSwSts_R 0;
BA_ "SignalLongName" SG_ 945 HMIMtSwSts_R "HMIMuteSwitchStatus Right";
BA_ "GenSigStartValue" SG_ 945 HMIMtSwSts_R 1;

BA_ "GenSigSendType" SG_ 945 RemnDstcDsplyExchgReq 4;
BA_ "SignalLongName" SG_ 945 RemnDstcDsplyExchgReq "RemainDistanceDispalyExchangeRequest";

BA_ "GenSigSendType" SG_ 945 DspMeasUntSetReq 4;
BA_ "SignalLongName" SG_ 945 DspMeasUntSetReq "DisplayMeasureUnitSetRequest";

BA_ "GenSigSendType" SG_ 945 IntLgtOffReq 4;
BA_ "SignalLongName" SG_ 945 IntLgtOffReq "Interior Light Off Request";

BA_ "GenSigSendType" SG_ 945 RemnDstcDsplyCycReq 4;
BA_ "SignalLongName" SG_ 945 RemnDstcDsplyCycReq "Remain Distance Dispaly Cycle Request";

BA_ "GenSigSendType" SG_ 945 ChldLckSw_R 4;
BA_ "SignalLongName" SG_ 945 ChldLckSw_R "Child Lock Switch_Right";

BA_ "GenSigSendType" SG_ 945 LockVehRcvrMdSet 4;
BA_ "SignalLongName" SG_ 945 LockVehRcvrMdSet "LockVehicleRecoverModeSet";

BA_ "GenSigSendType" SG_ 945 IntltWlcmMdSet 4;
BA_ "SignalLongName" SG_ 945 IntltWlcmMdSet "IntelligentWelcomeModeSet";

BA_ "GenSigSendType" SG_ 945 ThemeSettingAdj_2 0;
BA_ "SignalLongName" SG_ 945 ThemeSettingAdj_2 "ThemeSettingAdjustment_2";

BA_ "GenSigSendType" SG_ 945 RunPowMdAutoOffReq 4;
BA_ "SignalLongName" SG_ 945 RunPowMdAutoOffReq "RUN Power Mode Auto Off Request";

BA_ "GenSigSendType" SG_ 945 CPDWrnngLvl 0;
BA_ "SignalLongName" SG_ 945 CPDWrnngLvl "CPD Warning Level";

BA_ "GenSigSendType" SG_ 945 SldDrCtrlReq_R_HMI 4;
BA_ "SignalLongName" SG_ 945 SldDrCtrlReq_R_HMI "Sliding Door Control Reqeust Right HMI";

BA_ "GenSigSendType" SG_ 945 ChldLckSw_L 4;
BA_ "SignalLongName" SG_ 945 ChldLckSw_L "Child Lock Switch_Left";

BA_ "GenSigSendType" SG_ 945 CPDFnSwReq 4;
BA_ "SignalLongName" SG_ 945 CPDFnSwReq "CPDFunctionSwitchRequest";

BA_ "GenSigSendType" SG_ 945 RunPowMdAutoOffRmndrFdbck 4;
BA_ "SignalLongName" SG_ 945 RunPowMdAutoOffRmndrFdbck "RUN Power Mode Auto Off Reminder Feedback";

BA_ "GenSigSendType" SG_ 945 ESSSwapCnfmFICM 0;
BA_ "SignalLongName" SG_ 945 ESSSwapCnfmFICM "Energy Storage System Swap Confirm Front Infotainment Control Module";

BA_ "GenSigSendType" SG_ 945 ESSSwapCnfmFICMV 0;
BA_ "SignalLongName" SG_ 945 ESSSwapCnfmFICMV "Energy Storage System Swap Confirm Front Infotainment Control Module Validity";
BA_ "GenSigTimeoutValue" SG_ 945 ESSSwapCnfmFICMV 1;
BA_ "GenSigStartValue" SG_ 945 ESSSwapCnfmFICMV 1;

BA_ "GenSigSendType" SG_ 945 LanguageSettingAdj_2 0;
BA_ "SignalLongName" SG_ 945 LanguageSettingAdj_2 "LanguageSettingAdjustment_2";

BA_ "GenMsgSendType" BO_ 946 0;
BA_ "GenMsgStartDelayTime" BO_ 946 10;
BA_ "GenMsgCycleTime" BO_ 946 500;
BA_ "GenMsgILSupport" BO_ 946 1;
BA_ "GenMsgCycleTimeFast" BO_ 946 40;
BA_ "GenMsgNrOfRepetition" BO_ 946 3;
BA_ "GenMsgDelayTime" BO_ 946 20;
BA_ "VFrameFormat" BO_ 946 14;

BA_ "GenSigSendType" SG_ 946 HdLmpAdjReq 4;
BA_ "SignalLongName" SG_ 946 HdLmpAdjReq "Head Lamp Level Adjust Request";

BA_ "GenSigSendType" SG_ 946 VisionMdReq 4;
BA_ "SignalLongName" SG_ 946 VisionMdReq "Vision Mode Request";

BA_ "GenSigSendType" SG_ 946 TlgtOprtMdSt 4;
BA_ "SignalLongName" SG_ 946 TlgtOprtMdSt "Tailgate Operation Mode Set";

BA_ "GenSigSendType" SG_ 946 TlgtOprtReq 4;
BA_ "SignalLongName" SG_ 946 TlgtOprtReq "Tailgate Operation Request";

BA_ "GenSigSendType" SG_ 946 PDCMainSWReq_ICU 4;
BA_ "SignalLongName" SG_ 946 PDCMainSWReq_ICU "PDC Main Switch Request_ICU";

BA_ "GenSigSendType" SG_ 946 ChrIndReq_HMI 4;
BA_ "SignalLongName" SG_ 946 ChrIndReq_HMI "Charging Indicate Request_HMI";

BA_ "GenSigSendType" SG_ 946 WPCEnblReq 4;
BA_ "SignalLongName" SG_ 946 WPCEnblReq "Wireless Powered Charging Enable Request";

BA_ "GenSigSendType" SG_ 946 BkltLumSet 4;
BA_ "SignalLongName" SG_ 946 BkltLumSet "Backlight Luminance Set";

BA_ "GenSigSendType" SG_ 946 FrtFogLmpOprtMdSet 4;
BA_ "SignalLongName" SG_ 946 FrtFogLmpOprtMdSet "Front Fog Lamp Operation Mode Set";

BA_ "GenSigSendType" SG_ 946 HdLmpOprtMdSet 4;
BA_ "SignalLongName" SG_ 946 HdLmpOprtMdSet "Head Lamp Operation Mode Set";

BA_ "GenSigSendType" SG_ 946 FogLmpOprtMdSet 4;
BA_ "SignalLongName" SG_ 946 FogLmpOprtMdSet "Fog Lamp Operation Mode Set";

BA_ "GenSigSendType" SG_ 946 PMMOFFReq 4;
BA_ "SignalLongName" SG_ 946 PMMOFFReq "PMMOFFRequest";

BA_ "GenSigSendType" SG_ 946 TlgtPrkMdPosSt 4;
BA_ "SignalLongName" SG_ 946 TlgtPrkMdPosSt "Tailgate Park Mode Position Set";
BA_ "GenSigStartValue" SG_ 946 TlgtPrkMdPosSt 127;

BA_ "GenSigSendType" SG_ 946 MrrAutoDipSet 4;
BA_ "SignalLongName" SG_ 946 MrrAutoDipSet "Mirror Auto Dip Set";

BA_ "GenSigSendType" SG_ 946 FrtWprOprtReq 4;
BA_ "SignalLongName" SG_ 946 FrtWprOprtReq "Front Wiper Operation Request";

BA_ "GenSigSendType" SG_ 946 FICMBssMdReq 4;
BA_ "SignalLongName" SG_ 946 FICMBssMdReq "FICMBossModeRequest";

BA_ "GenSigSendType" SG_ 946 BodyCtrl_RllCnt 0;
BA_ "SignalLongName" SG_ 946 BodyCtrl_RllCnt "BodyCtrl Rolling Counter";

BA_ "GenSigSendType" SG_ 946 PckLgtOprtMdSet 4;
BA_ "SignalLongName" SG_ 946 PckLgtOprtMdSet "Packing Lighting Operation Mode Set";

BA_ "GenSigSendType" SG_ 946 BodyCtrl_Chksum 0;
BA_ "SignalLongName" SG_ 946 BodyCtrl_Chksum "BodyCtrl Checksum";

BA_ "GenMsgSendType" BO_ 947 0;
BA_ "GenMsgStartDelayTime" BO_ 947 10;
BA_ "GenMsgCycleTime" BO_ 947 500;
BA_ "GenMsgILSupport" BO_ 947 1;
BA_ "GenMsgCycleTimeFast" BO_ 947 30;
BA_ "GenMsgNrOfRepetition" BO_ 947 5;
BA_ "GenMsgDelayTime" BO_ 947 30;
BA_ "VFrameFormat" BO_ 947 14;

BA_ "GenSigSendType" SG_ 947 HDCFnSwReq 4;
BA_ "SignalLongName" SG_ 947 HDCFnSwReq "HDCFunctionSwitchRequest";

BA_ "GenSigSendType" SG_ 947 ESCFnSwReq 4;
BA_ "SignalLongName" SG_ 947 ESCFnSwReq "ESCFunctionSwitchRequest";

BA_ "GenSigSendType" SG_ 947 EPBIgnoffAutoAppFnSwReq 4;
BA_ "SignalLongName" SG_ 947 EPBIgnoffAutoAppFnSwReq "EPBIgnoffAutoapplyFunctionSwitchRequest";

BA_ "GenSigSendType" SG_ 947 AVHFnSwReq 4;
BA_ "SignalLongName" SG_ 947 AVHFnSwReq "AVHFunctionSwitchRequest";

BA_ "GenSigSendType" SG_ 947 EPBRlseFuSwReq 4;
BA_ "SignalLongName" SG_ 947 EPBRlseFuSwReq "EPBReleaseFunctionSwitchRequest";

BA_ "GenSigSendType" SG_ 947 EPSCurrModReq 4;
BA_ "SignalLongName" SG_ 947 EPSCurrModReq "EPS current Mode Request";

BA_ "GenSigSendType" SG_ 947 BrkFlngMdStsReq 4;
BA_ "SignalLongName" SG_ 947 BrkFlngMdStsReq "Brake Feeling Mode Status Request";

BA_ "GenSigSendType" SG_ 947 RGNSwReq 4;
BA_ "SignalLongName" SG_ 947 RGNSwReq "Regeneration Switch Request";

BA_ "GenSigSendType" SG_ 947 FrtPsngAirbagOnOffReq 4;
BA_ "SignalLongName" SG_ 947 FrtPsngAirbagOnOffReq "Front Passange Airbag On or Off Request";

BA_ "GenSigSendType" SG_ 947 RGNSwReqV 4;
BA_ "SignalLongName" SG_ 947 RGNSwReqV "RGN Switch Request Valid";

BA_ "GenSigSendType" SG_ 947 RGNResReq 4;
BA_ "SignalLongName" SG_ 947 RGNResReq "RGN Reset Request";

BA_ "GenSigSendType" SG_ 947 RGNResReqV 4;
BA_ "SignalLongName" SG_ 947 RGNResReqV "RGN Reset Request Valid";

BA_ "GenSigSendType" SG_ 947 ASSBtnReq 4;
BA_ "SignalLongName" SG_ 947 ASSBtnReq "Auto Stop Start Button Request";

BA_ "GenSigSendType" SG_ 947 SBRSetReq_R 4;
BA_ "SignalLongName" SG_ 947 SBRSetReq_R "Seatbelt Reminder Set Request_Rear";

BA_ "GenSigSendType" SG_ 947 RGNOkNum 0;
BA_ "SignalLongName" SG_ 947 RGNOkNum "RGN Ok Number";

BA_ "GenSigSendType" SG_ 947 RGNResNum 0;
BA_ "SignalLongName" SG_ 947 RGNResNum "RGN Reset Number";

BA_ "GenSigSendType" SG_ 947 Chassis_PowerTrainCtrl_RllCnt 0;
BA_ "SignalLongName" SG_ 947 Chassis_PowerTrainCtrl_RllCnt "Chassis_PowerTrainCtrl Rolling Counter";

BA_ "GenSigSendType" SG_ 947 CCOFnSoftSw 4;
BA_ "SignalLongName" SG_ 947 CCOFnSoftSw "CCO Function Soft Switch";
BA_ "GenSigTimeoutValue" SG_ 947 CCOFnSoftSw 3;
BA_ "GenSigStartValue" SG_ 947 CCOFnSoftSw 3;

BA_ "GenSigSendType" SG_ 947 WadeModeReq 4;
BA_ "SignalLongName" SG_ 947 WadeModeReq "Wade Mode Request";

BA_ "GenSigSendType" SG_ 947 Chassis_PowerTrainCtrl_Chksum 0;
BA_ "SignalLongName" SG_ 947 Chassis_PowerTrainCtrl_Chksum "Chassis_PowerTrainCtrl Checksum";

BA_ "GenMsgSendType" BO_ 949 0;
BA_ "GenMsgStartDelayTime" BO_ 949 15;
BA_ "GenMsgCycleTime" BO_ 949 500;
BA_ "GenMsgILSupport" BO_ 949 1;
BA_ "GenMsgCycleTimeFast" BO_ 949 40;
BA_ "GenMsgNrOfRepetition" BO_ 949 3;
BA_ "GenMsgDelayTime" BO_ 949 20;
BA_ "VFrameFormat" BO_ 949 14;

BA_ "GenSigSendType" SG_ 949 HVACOnOffSwReq_HMI 4;
BA_ "SignalLongName" SG_ 949 HVACOnOffSwReq_HMI "HVACOnOffSwitchRequest_HMI";

BA_ "GenSigSendType" SG_ 949 HVACComprOnOffSwReq_HMI 4;
BA_ "SignalLongName" SG_ 949 HVACComprOnOffSwReq_HMI "HVACCompressOnOffSwRequest_HMI";

BA_ "GenSigSendType" SG_ 949 HVACAutoSwReq_HMI 4;
BA_ "SignalLongName" SG_ 949 HVACAutoSwReq_HMI "HVACAutoSwitchRequest_HMI";

BA_ "GenSigSendType" SG_ 949 FrtDfstOnSwReq_HMI 4;
BA_ "SignalLongName" SG_ 949 FrtDfstOnSwReq_HMI "FrontDefrostOnSwRequest_HMI";

BA_ "GenSigSendType" SG_ 949 RrWndDfstSwReq_HMI 4;
BA_ "SignalLongName" SG_ 949 RrWndDfstSwReq_HMI "RrWindowDefrostSwRequest_HMI";

BA_ "GenSigSendType" SG_ 949 HVACRcctnSwReq_HMI 4;
BA_ "SignalLongName" SG_ 949 HVACRcctnSwReq_HMI "HVACRcctnSwitchRequest_HMI";

BA_ "GenSigSendType" SG_ 949 HVACSYNCSwReq_HMI 4;
BA_ "SignalLongName" SG_ 949 HVACSYNCSwReq_HMI "HVACSYNCSwitchRequest_HMI";

BA_ "GenSigSendType" SG_ 949 FICMAirClnrUserCustAutoReq 4;
BA_ "SignalLongName" SG_ 949 FICMAirClnrUserCustAutoReq "Air Cleaner User Customization Auto Work Request";

BA_ "GenSigSendType" SG_ 949 HVACFLTemReq_HMI 4;
BA_ "SignalLongName" SG_ 949 HVACFLTemReq_HMI "HVACFLTemperatureRequest_HMI";
BA_ "GenSigStartValue" SG_ 949 HVACFLTemReq_HMI 255;

BA_ "GenSigSendType" SG_ 949 HVACFRTemReq_HMI 4;
BA_ "SignalLongName" SG_ 949 HVACFRTemReq_HMI "HVACFRTemperatureRequest_HMI";
BA_ "GenSigStartValue" SG_ 949 HVACFRTemReq_HMI 255;

BA_ "GenSigSendType" SG_ 949 HVACBlwrLvlReq_HMI 4;
BA_ "SignalLongName" SG_ 949 HVACBlwrLvlReq_HMI "HVACBlowrLevelRequest_HMI";
BA_ "GenSigStartValue" SG_ 949 HVACBlwrLvlReq_HMI 15;

BA_ "GenSigSendType" SG_ 949 HVACAirMdReq_HMI 4;
BA_ "SignalLongName" SG_ 949 HVACAirMdReq_HMI "HVACAirModeRequest_HMI";
BA_ "GenSigStartValue" SG_ 949 HVACAirMdReq_HMI 15;

BA_ "GenSigSendType" SG_ 949 HVACFrtBlwrLvlupdownReq_HMI 4;
BA_ "SignalLongName" SG_ 949 HVACFrtBlwrLvlupdownReq_HMI "HVACFrontBlowrLevelupdownRequest_HMI";

BA_ "GenSigSendType" SG_ 949 HVACFLTemupdownReq_HMI 4;
BA_ "SignalLongName" SG_ 949 HVACFLTemupdownReq_HMI "HVACFrontLeftTemperatureUpDownRequest_HMI";

BA_ "GenSigSendType" SG_ 949 HVACFRTemupdownReq_HMI 4;
BA_ "SignalLongName" SG_ 949 HVACFRTemupdownReq_HMI "HVACFrontRightTemperatureUpDownRequest_HMI";

BA_ "GenSigSendType" SG_ 949 HVACFRACMaxSwReq_HMI 4;
BA_ "SignalLongName" SG_ 949 HVACFRACMaxSwReq_HMI "HVACFront AC Max Switch Request_HMI";

BA_ "GenMsgSendType" BO_ 950 0;
BA_ "GenMsgStartDelayTime" BO_ 950 15;
BA_ "GenMsgCycleTime" BO_ 950 500;
BA_ "GenMsgILSupport" BO_ 950 1;
BA_ "GenMsgCycleTimeFast" BO_ 950 40;
BA_ "GenMsgNrOfRepetition" BO_ 950 3;
BA_ "GenMsgDelayTime" BO_ 950 20;
BA_ "VFrameFormat" BO_ 950 14;

BA_ "GenSigSendType" SG_ 950 HVACRearOnOffSwReq_HMI 4;
BA_ "SignalLongName" SG_ 950 HVACRearOnOffSwReq_HMI "HVACRearOnOffSwitchRequest_HMI";

BA_ "GenSigSendType" SG_ 950 HVACRearAutoSwReq_HMI 4;
BA_ "SignalLongName" SG_ 950 HVACRearAutoSwReq_HMI "HVACRearAutoSwitchRequest_HMI";

BA_ "GenSigSendType" SG_ 950 HVACRearAirMdReq_HMI 4;
BA_ "SignalLongName" SG_ 950 HVACRearAirMdReq_HMI "HVACRearAirModeRequest_HMI";
BA_ "GenSigStartValue" SG_ 950 HVACRearAirMdReq_HMI 15;

BA_ "GenSigSendType" SG_ 950 HVACRearSetTemReq_HMI 4;
BA_ "SignalLongName" SG_ 950 HVACRearSetTemReq_HMI "HVACRearSetTemperatureRequest_HMI";
BA_ "GenSigStartValue" SG_ 950 HVACRearSetTemReq_HMI 255;

BA_ "GenSigSendType" SG_ 950 HVACRearBlwrLvlReq_HMI 4;
BA_ "SignalLongName" SG_ 950 HVACRearBlwrLvlReq_HMI "HVACRearBlowrLevelRequest_HMI";
BA_ "GenSigStartValue" SG_ 950 HVACRearBlwrLvlReq_HMI 15;

BA_ "GenSigSendType" SG_ 950 HVACRearBlwrLvlupdownReq_HMI 4;
BA_ "SignalLongName" SG_ 950 HVACRearBlwrLvlupdownReq_HMI "HVACRearBlowrLevelupdownRequest_HMI";

BA_ "GenSigSendType" SG_ 950 HVACRearComprOnOffSwReq_HMI 4;
BA_ "SignalLongName" SG_ 950 HVACRearComprOnOffSwReq_HMI "HVACRearCompressOnOffSwRequest_HMI";

BA_ "GenSigSendType" SG_ 950 HVACRearBlwr2LvlReq_HMI 4;
BA_ "SignalLongName" SG_ 950 HVACRearBlwr2LvlReq_HMI "HVACRearBlowr2LevelRequest_HMI";
BA_ "GenSigStartValue" SG_ 950 HVACRearBlwr2LvlReq_HMI 15;

BA_ "GenSigSendType" SG_ 950 HVACRearBlwr2LvlupdownReq_HMI 4;
BA_ "SignalLongName" SG_ 950 HVACRearBlwr2LvlupdownReq_HMI "HVACRearBlowr2LevelupdownRequest_HMI";

BA_ "GenSigSendType" SG_ 950 RFGEngOffOprtReq 4;
BA_ "SignalLongName" SG_ 950 RFGEngOffOprtReq "Refrigerator Engine off Operation Request";
BA_ "GenSigTimeoutValue" SG_ 950 RFGEngOffOprtReq 3;
BA_ "GenSigStartValue" SG_ 950 RFGEngOffOprtReq 3;

BA_ "GenSigSendType" SG_ 950 RFGOprtReq 4;
BA_ "SignalLongName" SG_ 950 RFGOprtReq "Refrigerator Operation Request";
BA_ "GenSigTimeoutValue" SG_ 950 RFGOprtReq 3;
BA_ "GenSigStartValue" SG_ 950 RFGOprtReq 3;

BA_ "GenSigSendType" SG_ 950 RFGTrgtTempReq 4;
BA_ "SignalLongName" SG_ 950 RFGTrgtTempReq "Refrigerator Target Temperature Request";
BA_ "GenSigTimeoutValue" SG_ 950 RFGTrgtTempReq 63;
BA_ "GenSigStartValue" SG_ 950 RFGTrgtTempReq 63;

BA_ "GenSigSendType" SG_ 950 RFGEngOffOprtDurReq 4;
BA_ "SignalLongName" SG_ 950 RFGEngOffOprtDurReq "Refrigerator Engine off Operation Duration Request";
BA_ "GenSigTimeoutValue" SG_ 950 RFGEngOffOprtDurReq 31;
BA_ "GenSigStartValue" SG_ 950 RFGEngOffOprtDurReq 31;

BA_ "GenSigSendType" SG_ 950 RFGOprtMdReq 4;
BA_ "SignalLongName" SG_ 950 RFGOprtMdReq "Refrigerator Operation Mode Request";
BA_ "GenSigTimeoutValue" SG_ 950 RFGOprtMdReq 3;
BA_ "GenSigStartValue" SG_ 950 RFGOprtMdReq 3;

BA_ "GenMsgSendType" BO_ 951 0;
BA_ "GenMsgStartDelayTime" BO_ 951 15;
BA_ "GenMsgCycleTime" BO_ 951 500;
BA_ "GenMsgILSupport" BO_ 951 1;
BA_ "GenMsgCycleTimeFast" BO_ 951 60;
BA_ "GenMsgNrOfRepetition" BO_ 951 3;
BA_ "GenMsgDelayTime" BO_ 951 20;
BA_ "VFrameFormat" BO_ 951 14;

BA_ "GenSigSendType" SG_ 951 LeftArVetLRSwingReq_HMI 4;
BA_ "SignalLongName" SG_ 951 LeftArVetLRSwingReq_HMI "Left Air Vent Left Right Swing Request";

BA_ "GenSigSendType" SG_ 951 LeftMidArVetLRSwingReq_HMI 4;
BA_ "SignalLongName" SG_ 951 LeftMidArVetLRSwingReq_HMI "Left Middle Air Vent Left Right Swing Request";

BA_ "GenSigSendType" SG_ 951 RightMidArVetLRSwingReq_HMI 4;
BA_ "SignalLongName" SG_ 951 RightMidArVetLRSwingReq_HMI "Right Middle Air Vent Left Right Swing Request";

BA_ "GenSigSendType" SG_ 951 RightArVetSwingLRReq_HMI 4;
BA_ "SignalLongName" SG_ 951 RightArVetSwingLRReq_HMI "Right Air Vent Left Right Swing Request";

BA_ "GenSigSendType" SG_ 951 LeftArVetUDSwingReq_HMI 4;
BA_ "SignalLongName" SG_ 951 LeftArVetUDSwingReq_HMI "Left Air Vent Up Down Swing Request";

BA_ "GenSigSendType" SG_ 951 LeftMidArVetUDSwingReq_HMI 4;
BA_ "SignalLongName" SG_ 951 LeftMidArVetUDSwingReq_HMI "Left Middle Air Vent Up Down Swing Request";

BA_ "GenSigSendType" SG_ 951 RightMidArVetUDSwingReq_HMI 4;
BA_ "SignalLongName" SG_ 951 RightMidArVetUDSwingReq_HMI "Right Middle Air Vent Up Down Swing Request";

BA_ "GenSigSendType" SG_ 951 RightArVetSwingUDReq_HMI 4;
BA_ "SignalLongName" SG_ 951 RightArVetSwingUDReq_HMI "Right Air Vent Up Down Swing Request";

BA_ "GenSigSendType" SG_ 951 LeftArVetFosReq_HMI 4;
BA_ "SignalLongName" SG_ 951 LeftArVetFosReq_HMI "Left Air Vent Focus Request";

BA_ "GenSigSendType" SG_ 951 RightArVetFosReq_HMI 4;
BA_ "SignalLongName" SG_ 951 RightArVetFosReq_HMI "Right Air Vent Focus Request";

BA_ "GenSigSendType" SG_ 951 LeftArVetDistribReq_HMI 4;
BA_ "SignalLongName" SG_ 951 LeftArVetDistribReq_HMI "Left Air Vent Distribute Request";

BA_ "GenSigSendType" SG_ 951 RightArVetDistribReq_HMI 4;
BA_ "SignalLongName" SG_ 951 RightArVetDistribReq_HMI "Right Air Vent Distribute Request";

BA_ "GenSigSendType" SG_ 951 LeftArVetSweepReq_HMI 4;
BA_ "SignalLongName" SG_ 951 LeftArVetSweepReq_HMI "Left Air Vent Sweep Request";

BA_ "GenSigSendType" SG_ 951 RightArVetSweepReq_HMI 4;
BA_ "SignalLongName" SG_ 951 RightArVetSweepReq_HMI "Right Air Vent Sweep Request";

BA_ "GenSigSendType" SG_ 951 LeftArVetOnOffReq_HMI 4;
BA_ "SignalLongName" SG_ 951 LeftArVetOnOffReq_HMI "Left Air Vent On Off Request";

BA_ "GenSigSendType" SG_ 951 RightArVetOnOffReq_HMI 4;
BA_ "SignalLongName" SG_ 951 RightArVetOnOffReq_HMI "Right Air Vent On Off Request";

BA_ "GenMsgSendType" BO_ 953 0;
BA_ "GenMsgStartDelayTime" BO_ 953 10;
BA_ "GenMsgCycleTime" BO_ 953 500;
BA_ "GenMsgILSupport" BO_ 953 1;
BA_ "GenMsgCycleTimeFast" BO_ 953 40;
BA_ "GenMsgNrOfRepetition" BO_ 953 3;
BA_ "GenMsgDelayTime" BO_ 953 20;
BA_ "VFrameFormat" BO_ 953 14;

BA_ "GenSigSendType" SG_ 953 SldDrPos_L 0;
BA_ "SignalLongName" SG_ 953 SldDrPos_L "Sliding Door Position Left";
BA_ "GenSigStartValue" SG_ 953 SldDrPos_L 127;

BA_ "GenSigSendType" SG_ 953 SldDrOprtSts_L 4;
BA_ "SignalLongName" SG_ 953 SldDrOprtSts_L "Sliding Door Operation Status Left";

BA_ "GenSigSendType" SG_ 953 SldDrOprtMd_L 4;
BA_ "SignalLongName" SG_ 953 SldDrOprtMd_L "Sliding Door Operation Mode Left";

BA_ "GenSigSendType" SG_ 953 SldDrPosSts_L 4;
BA_ "SignalLongName" SG_ 953 SldDrPosSts_L "Sliding Door Position Status Left";

BA_ "GenSigSendType" SG_ 953 ChldLckSts_L 4;
BA_ "SignalLongName" SG_ 953 ChldLckSts_L "Child Lock Status_Left";

BA_ "GenSigSendType" SG_ 953 SldDrAbsAlrm_L 4;
BA_ "SignalLongName" SG_ 953 SldDrAbsAlrm_L "Sliding Door Abuse Alarm Left";

BA_ "GenMsgSendType" BO_ 954 0;
BA_ "GenMsgStartDelayTime" BO_ 954 10;
BA_ "GenMsgCycleTime" BO_ 954 500;
BA_ "GenMsgILSupport" BO_ 954 1;
BA_ "GenMsgCycleTimeFast" BO_ 954 40;
BA_ "GenMsgNrOfRepetition" BO_ 954 3;
BA_ "GenMsgDelayTime" BO_ 954 20;
BA_ "VFrameFormat" BO_ 954 14;

BA_ "GenSigSendType" SG_ 954 SldDrPos_R 0;
BA_ "SignalLongName" SG_ 954 SldDrPos_R "Sliding Door Position Left";
BA_ "GenSigStartValue" SG_ 954 SldDrPos_R 127;

BA_ "GenSigSendType" SG_ 954 SldDrOprtSts_R 4;
BA_ "SignalLongName" SG_ 954 SldDrOprtSts_R "Sliding Door Operation Status Left";

BA_ "GenSigSendType" SG_ 954 SldDrOprtMd_R 4;
BA_ "SignalLongName" SG_ 954 SldDrOprtMd_R "Sliding Door Operation Mode Left";

BA_ "GenSigSendType" SG_ 954 SldDrPosSts_R 4;
BA_ "SignalLongName" SG_ 954 SldDrPosSts_R "Sliding Door Position Status Left";

BA_ "GenSigSendType" SG_ 954 ChldLckSts_R 4;
BA_ "SignalLongName" SG_ 954 ChldLckSts_R "Child Lock Status_Right";

BA_ "GenSigSendType" SG_ 954 SldDrLtcSts_R 4;
BA_ "SignalLongName" SG_ 954 SldDrLtcSts_R "Sliding Door Latch Status Right";

BA_ "GenSigSendType" SG_ 954 SldDrAbsAlrm_R 4;
BA_ "SignalLongName" SG_ 954 SldDrAbsAlrm_R "Sliding Door Abuse Alarm Right";

BA_ "GenMsgSendType" BO_ 956 0;
BA_ "GenMsgStartDelayTime" BO_ 956 10;
BA_ "GenMsgCycleTime" BO_ 956 500;
BA_ "GenMsgILSupport" BO_ 956 1;
BA_ "GenMsgCycleTimeFast" BO_ 956 40;
BA_ "GenMsgNrOfRepetition" BO_ 956 3;
BA_ "GenMsgDelayTime" BO_ 956 20;
BA_ "VFrameFormat" BO_ 956 14;

BA_ "GenSigSendType" SG_ 956 HMIRfLmp1Cmd 4;
BA_ "SignalLongName" SG_ 956 HMIRfLmp1Cmd "HMIRoofLamp1Command";

BA_ "GenSigSendType" SG_ 956 Wdw_DRAutoOprtnReq 4;
BA_ "SignalLongName" SG_ 956 Wdw_DRAutoOprtnReq "Window_DRAutoOperaiotnRequest_HMI";
BA_ "GenSigStartValue" SG_ 956 Wdw_DRAutoOprtnReq 31;

BA_ "GenSigSendType" SG_ 956 Wdw_PRAutoOprtnReq 4;
BA_ "SignalLongName" SG_ 956 Wdw_PRAutoOprtnReq "Window_PRAutoOperaiotnRequest_HMI";
BA_ "GenSigStartValue" SG_ 956 Wdw_PRAutoOprtnReq 31;

BA_ "GenSigSendType" SG_ 956 AprchngLghtSt 4;
BA_ "SignalLongName" SG_ 956 AprchngLghtSt "ApprochingLightSet";

BA_ "GenSigSendType" SG_ 956 IntWlcmLampSetReq 4;
BA_ "SignalLongName" SG_ 956 IntWlcmLampSetReq "Intelligent Welcome Lamp Set Request";

BA_ "GenSigSendType" SG_ 956 HMIRfLmp2Cmd 4;
BA_ "SignalLongName" SG_ 956 HMIRfLmp2Cmd "HMIRoofLamp2Command";

BA_ "GenSigSendType" SG_ 956 Wdw_RLAutoOprtnReq 4;
BA_ "SignalLongName" SG_ 956 Wdw_RLAutoOprtnReq "Window_RLAutoOperaiotnRequest_HMI";
BA_ "GenSigStartValue" SG_ 956 Wdw_RLAutoOprtnReq 31;

BA_ "GenSigSendType" SG_ 956 Wdw_RRAutoOprtnReq 4;
BA_ "SignalLongName" SG_ 956 Wdw_RRAutoOprtnReq "Window_RRAutoOperaiotnRequest_HMI";
BA_ "GenSigStartValue" SG_ 956 Wdw_RRAutoOprtnReq 31;

BA_ "GenSigSendType" SG_ 956 DrvrFatigueReminderSetReq 4;
BA_ "SignalLongName" SG_ 956 DrvrFatigueReminderSetReq "DriverFatigueReminderSetRequest";

BA_ "GenSigSendType" SG_ 956 LogoLgtOnPGearSetReq 4;
BA_ "SignalLongName" SG_ 956 LogoLgtOnPGearSetReq "Logo Light On Park Gear Set Request";

BA_ "GenSigSendType" SG_ 956 HMIRfLmp3Cmd 4;
BA_ "SignalLongName" SG_ 956 HMIRfLmp3Cmd "HMIRoofLamp3Command";

BA_ "GenSigSendType" SG_ 956 HMIRfLmp4Cmd 4;
BA_ "SignalLongName" SG_ 956 HMIRfLmp4Cmd "HMIRoofLamp4Command";

BA_ "GenSigSendType" SG_ 956 PSRTrgtSlct 4;
BA_ "SignalLongName" SG_ 956 PSRTrgtSlct "Sunroof Control Target Select";

BA_ "GenSigSendType" SG_ 956 PSRManualOprtReq 4;
BA_ "SignalLongName" SG_ 956 PSRManualOprtReq "PSR Manual Operation Request";

BA_ "GenSigSendType" SG_ 956 HMIRfLmpTrdRowCmd 4;
BA_ "SignalLongName" SG_ 956 HMIRfLmpTrdRowCmd "HMIRoofLampThirdRowCommand";

BA_ "GenSigSendType" SG_ 956 PSRAutoOprtReq 4;
BA_ "SignalLongName" SG_ 956 PSRAutoOprtReq "Sunroof Auto Operation Request";
BA_ "GenSigStartValue" SG_ 956 PSRAutoOprtReq 31;

BA_ "GenSigSendType" SG_ 956 SRFAutoOprtReq 4;
BA_ "SignalLongName" SG_ 956 SRFAutoOprtReq "Sunroof Auto Operation Request";
BA_ "GenSigStartValue" SG_ 956 SRFAutoOprtReq 31;

BA_ "GenSigSendType" SG_ 956 SRFManualOprtReq 4;
BA_ "SignalLongName" SG_ 956 SRFManualOprtReq "Sunroof Manual Operation Request";

BA_ "GenSigSendType" SG_ 956 HVFuelCmd 4;
BA_ "SignalLongName" SG_ 956 HVFuelCmd "High Voltage Fuel Command";

BA_ "GenSigSendType" SG_ 956 TlgtOprtPosReq 4;
BA_ "SignalLongName" SG_ 956 TlgtOprtPosReq "Tailgate Operation Position Request";
BA_ "GenSigStartValue" SG_ 956 TlgtOprtPosReq 127;

BA_ "GenMsgSendType" BO_ 957 0;
BA_ "GenMsgStartDelayTime" BO_ 957 10;
BA_ "GenMsgCycleTime" BO_ 957 100;
BA_ "GenMsgILSupport" BO_ 957 1;
BA_ "VFrameFormat" BO_ 957 14;

BA_ "GenSigSendType" SG_ 957 HybCampMdDrvrItndSOCMaxAch 0;
BA_ "SignalLongName" SG_ 957 HybCampMdDrvrItndSOCMaxAch "Hybrid Camp Mode Driver Intended State Of Charge Maximum Achieved";

BA_ "GenSigSendType" SG_ 957 HybCampMdGennPwrDsp 0;
BA_ "SignalLongName" SG_ 957 HybCampMdGennPwrDsp "Hybrid Camp Mode Generation Power Display";

BA_ "GenSigSendType" SG_ 957 HybCampMdDrvrItndSOCMinAch 0;
BA_ "SignalLongName" SG_ 957 HybCampMdDrvrItndSOCMinAch "Hybrid Camp Mode Driver Intended State Of Charge Minimum Achieved";

BA_ "GenSigSendType" SG_ 957 HybCampMdDrvrItndGennLvlAch 0;
BA_ "SignalLongName" SG_ 957 HybCampMdDrvrItndGennLvlAch "Hybrid Camp Mode Driver Intended Generation Level";

BA_ "GenMsgSendType" BO_ 958 0;
BA_ "GenMsgStartDelayTime" BO_ 958 10;
BA_ "GenMsgCycleTime" BO_ 958 500;
BA_ "GenMsgILSupport" BO_ 958 1;
BA_ "GenMsgCycleTimeFast" BO_ 958 40;
BA_ "GenMsgNrOfRepetition" BO_ 958 3;
BA_ "GenMsgDelayTime" BO_ 958 20;
BA_ "VFrameFormat" BO_ 958 14;

BA_ "GenSigSendType" SG_ 958 HUDEnbSetReq 4;
BA_ "SignalLongName" SG_ 958 HUDEnbSetReq "HUD Enable Set Request";

BA_ "GenSigSendType" SG_ 958 HUDPctAlttdAdjReq 4;
BA_ "SignalLongName" SG_ 958 HUDPctAlttdAdjReq "HUD Picture Altitude Adjust Request";
BA_ "GenSigTimeoutValue" SG_ 958 HUDPctAlttdAdjReq 31;
BA_ "GenSigStartValue" SG_ 958 HUDPctAlttdAdjReq 31;

BA_ "GenSigSendType" SG_ 958 HUDPctInclntAdjReq 4;
BA_ "SignalLongName" SG_ 958 HUDPctInclntAdjReq "HUD Picture Inclination Adjust Request";
BA_ "GenSigTimeoutValue" SG_ 958 HUDPctInclntAdjReq 15;
BA_ "GenSigStartValue" SG_ 958 HUDPctInclntAdjReq 15;

BA_ "GenSigSendType" SG_ 958 HUDDmAdjReq 4;
BA_ "SignalLongName" SG_ 958 HUDDmAdjReq "HUD Dimming Adjust Request";
BA_ "GenSigTimeoutValue" SG_ 958 HUDDmAdjReq 31;
BA_ "GenSigStartValue" SG_ 958 HUDDmAdjReq 31;

BA_ "GenSigSendType" SG_ 958 LVDSSts 0;
BA_ "SignalLongName" SG_ 958 LVDSSts "LVDS Status";

BA_ "GenMsgSendType" BO_ 965 0;
BA_ "GenMsgStartDelayTime" BO_ 965 20;
BA_ "GenMsgCycleTime" BO_ 965 200;
BA_ "GenMsgILSupport" BO_ 965 1;
BA_ "GenMsgCycleTimeFast" BO_ 965 40;
BA_ "GenMsgNrOfRepetition" BO_ 965 3;
BA_ "GenMsgDelayTime" BO_ 965 20;
BA_ "VFrameFormat" BO_ 965 14;

BA_ "GenSigSendType" SG_ 965 VehUnLckForm_VAN 0;
BA_ "SignalLongName" SG_ 965 VehUnLckForm_VAN "Vehicle Unlock Form for VAN";

BA_ "GenSigSendType" SG_ 965 RainPrvtMdSts 0;
BA_ "SignalLongName" SG_ 965 RainPrvtMdSts "Rain Prevent Mode Status";

BA_ "GenSigSendType" SG_ 965 LckAutoWdwClsSts 0;
BA_ "SignalLongName" SG_ 965 LckAutoWdwClsSts "Lock Auto Window Close Function Status";

BA_ "GenSigSendType" SG_ 965 StWelcomeSts_DR 0;
BA_ "SignalLongName" SG_ 965 StWelcomeSts_DR "Seat Welcome Status_DR";

BA_ "GenSigSendType" SG_ 965 TempParkMdSetSts 0;
BA_ "SignalLongName" SG_ 965 TempParkMdSetSts "Temporary Park Mode Set Status";

BA_ "GenSigSendType" SG_ 965 TempParkMode 0;
BA_ "SignalLongName" SG_ 965 TempParkMode "Temporary Park Mode";

BA_ "GenSigSendType" SG_ 965 VehUnLckForm 0;
BA_ "SignalLongName" SG_ 965 VehUnLckForm "Vehicle Unlock Form";

BA_ "GenSigSendType" SG_ 965 LckFdbkSts 0;
BA_ "SignalLongName" SG_ 965 LckFdbkSts "Lock Feedback Present";

BA_ "GenSigSendType" SG_ 965 MrrAutoDipSts 0;
BA_ "SignalLongName" SG_ 965 MrrAutoDipSts "Mirror Auto Dipping Status";

BA_ "GenSigSendType" SG_ 965 MrrAutoFldSts 0;
BA_ "SignalLongName" SG_ 965 MrrAutoFldSts "Mirror Auto Fold Status";

BA_ "GenSigSendType" SG_ 965 DrvrFatigueReminderSetReqFdbck 0;
BA_ "SignalLongName" SG_ 965 DrvrFatigueReminderSetReqFdbck "Driver Fatigue Reminder Set Request Feedback";

BA_ "GenSigSendType" SG_ 965 StWelcomeSts_PR 0;
BA_ "SignalLongName" SG_ 965 StWelcomeSts_PR "Seat Welcome Status_PR";

BA_ "GenSigSendType" SG_ 965 FlwMHmSts 0;
BA_ "SignalLongName" SG_ 965 FlwMHmSts "Follow Me Home Status";

BA_ "GenSigSendType" SG_ 965 IntltWlcmMdSts 0;
BA_ "SignalLongName" SG_ 965 IntltWlcmMdSts "IntelligentWelcomeModeStatus";

BA_ "GenSigSendType" SG_ 965 LockVehRcvrMdSts 0;
BA_ "SignalLongName" SG_ 965 LockVehRcvrMdSts "LockVehicleRecoverModeStatus";

BA_ "GenSigSendType" SG_ 965 FndMyCarSts 0;
BA_ "SignalLongName" SG_ 965 FndMyCarSts "Find My Car Feedback Mode";

BA_ "GenSigSendType" SG_ 965 FndMyCarTmSts 0;
BA_ "SignalLongName" SG_ 965 FndMyCarTmSts "Find My Car Duration Time";

BA_ "GenSigSendType" SG_ 965 DrvMod 0;
BA_ "SignalLongName" SG_ 965 DrvMod "DriveMode";

BA_ "GenSigSendType" SG_ 965 DrvMdReqV 0;
BA_ "SignalLongName" SG_ 965 DrvMdReqV "DriveModeRequestValidity";

BA_ "GenSigSendType" SG_ 965 MemFdbk 4;
BA_ "SignalLongName" SG_ 965 MemFdbk "Memorization Feedback";

BA_ "GenSigSendType" SG_ 965 MemClrFdbk 4;
BA_ "SignalLongName" SG_ 965 MemClrFdbk "Memorization Clear Feedback";

BA_ "GenSigSendType" SG_ 965 SnsSldDrSetReqFdbck 4;
BA_ "SignalLongName" SG_ 965 SnsSldDrSetReqFdbck "Sensing Sliding Door Set Request Feedback";

BA_ "GenSigSendType" SG_ 965 AutoUnlockingSts 0;
BA_ "SignalLongName" SG_ 965 AutoUnlockingSts "Auto unlocking status";

BA_ "GenSigSendType" SG_ 965 MovingAutoLockSts 0;
BA_ "SignalLongName" SG_ 965 MovingAutoLockSts "MovingAutoLockStatus";

BA_ "GenSigSendType" SG_ 965 iBDUFctryDeftSetFnsh 0;
BA_ "SignalLongName" SG_ 965 iBDUFctryDeftSetFnsh "IBDU Factory Default Setting Finished";

BA_ "GenSigSendType" SG_ 965 RunPowMdAutoOffSts 0;
BA_ "SignalLongName" SG_ 965 RunPowMdAutoOffSts "RUN Power Mode Auto Off Status";

BA_ "GenSigSendType" SG_ 965 RunPowMdAutoOffRmndrReq 0;
BA_ "SignalLongName" SG_ 965 RunPowMdAutoOffRmndrReq "RUN Power Mode Auto Off Reminder Request";

BA_ "GenMsgSendType" BO_ 969 0;
BA_ "GenMsgStartDelayTime" BO_ 969 30;
BA_ "GenMsgCycleTime" BO_ 969 500;
BA_ "GenMsgILSupport" BO_ 969 1;
BA_ "VFrameFormat" BO_ 969 14;

BA_ "GenSigSendType" SG_ 969 TireStsWrn_FL 0;
BA_ "SignalLongName" SG_ 969 TireStsWrn_FL "Tire in Abnormal Status Warning_Front Left";

BA_ "GenSigSendType" SG_ 969 TireStsWrn_FR 0;
BA_ "SignalLongName" SG_ 969 TireStsWrn_FR "Tire in Abnormal Status Warning_Front Right";

BA_ "GenSigSendType" SG_ 969 TireStsWrn_RL 0;
BA_ "SignalLongName" SG_ 969 TireStsWrn_RL "Tire in Abnormal Status Warning_Rear Left";

BA_ "GenSigSendType" SG_ 969 TireStsWrn_RR 0;
BA_ "SignalLongName" SG_ 969 TireStsWrn_RR "Tire in Abnormal Status Warning_Rear Right";

BA_ "GenSigSendType" SG_ 969 TireStsWrn_RLOS 0;
BA_ "SignalLongName" SG_ 969 TireStsWrn_RLOS "Tire in Abnormal Status Warning_ Rear Left Outer Sensor";

BA_ "GenSigSendType" SG_ 969 TireStsWrn_RROS 0;
BA_ "SignalLongName" SG_ 969 TireStsWrn_RROS "Tire in Abnormal Status Warning_ Rear Right Outer Sensor";

BA_ "GenMsgSendType" BO_ 970 0;
BA_ "GenMsgStartDelayTime" BO_ 970 30;
BA_ "GenMsgCycleTime" BO_ 970 500;
BA_ "GenMsgILSupport" BO_ 970 1;
BA_ "VFrameFormat" BO_ 970 14;

BA_ "GenSigSendType" SG_ 970 TirePrs_FL 0;
BA_ "SignalLongName" SG_ 970 TirePrs_FL "Tire Pressure_Front Left";

BA_ "GenSigSendType" SG_ 970 TirePrs_FR 0;
BA_ "SignalLongName" SG_ 970 TirePrs_FR "Tire Pressure_Front Right";

BA_ "GenSigSendType" SG_ 970 TirePrs_RL 0;
BA_ "SignalLongName" SG_ 970 TirePrs_RL "Tire Pressure_Rear Left";

BA_ "GenSigSendType" SG_ 970 TirePrs_RR 0;
BA_ "SignalLongName" SG_ 970 TirePrs_RR "Tire Pressure_Rear Right";

BA_ "GenSigSendType" SG_ 970 TireTmp_FL 0;
BA_ "SignalLongName" SG_ 970 TireTmp_FL "Tire Temprature_Front Left";

BA_ "GenSigSendType" SG_ 970 TireTmp_FR 0;
BA_ "SignalLongName" SG_ 970 TireTmp_FR "Tire Temprature_Front Right";

BA_ "GenSigSendType" SG_ 970 TireTmp_RL 0;
BA_ "SignalLongName" SG_ 970 TireTmp_RL "Tire Temprature_Rear Left";

BA_ "GenSigSendType" SG_ 970 TireTmp_RR 0;
BA_ "SignalLongName" SG_ 970 TireTmp_RR "Tire Temprature_Rear Right";

BA_ "GenMsgSendType" BO_ 972 0;
BA_ "GenMsgStartDelayTime" BO_ 972 10;
BA_ "GenMsgCycleTime" BO_ 972 500;
BA_ "GenMsgILSupport" BO_ 972 1;
BA_ "VFrameFormat" BO_ 972 14;

BA_ "GenSigSendType" SG_ 972 StTrkPos_DR 0;
BA_ "SignalLongName" SG_ 972 StTrkPos_DR "Seat Track Position_DR";
BA_ "GenSigStartValue" SG_ 972 StTrkPos_DR 127;

BA_ "GenSigSendType" SG_ 972 StTiltPos_DR 0;
BA_ "SignalLongName" SG_ 972 StTiltPos_DR "Seat Tilt Position_DR";
BA_ "GenSigStartValue" SG_ 972 StTiltPos_DR 127;

BA_ "GenSigSendType" SG_ 972 StPhaPos_DR 0;
BA_ "SignalLongName" SG_ 972 StPhaPos_DR "Seat Pha Position_DR";
BA_ "GenSigStartValue" SG_ 972 StPhaPos_DR 127;

BA_ "GenSigSendType" SG_ 972 StRtaPos_DR 0;
BA_ "SignalLongName" SG_ 972 StRtaPos_DR "Seat Rotation Position_DR";
BA_ "GenSigStartValue" SG_ 972 StRtaPos_DR 127;

BA_ "GenSigSendType" SG_ 972 StHtSts_DR 0;
BA_ "SignalLongName" SG_ 972 StHtSts_DR "Seat Heat Status_DR";

BA_ "GenSigSendType" SG_ 972 StVtSts_DR 0;
BA_ "SignalLongName" SG_ 972 StVtSts_DR "Seat Vent Status_DR";

BA_ "GenSigSendType" SG_ 972 StMsgSts_DR 0;
BA_ "SignalLongName" SG_ 972 StMsgSts_DR "Seat Massage Status_DR";

BA_ "GenMsgSendType" BO_ 973 0;
BA_ "GenMsgStartDelayTime" BO_ 973 10;
BA_ "GenMsgCycleTime" BO_ 973 500;
BA_ "GenMsgILSupport" BO_ 973 1;
BA_ "GenMsgCycleTimeFast" BO_ 973 40;
BA_ "GenMsgNrOfRepetition" BO_ 973 3;
BA_ "GenMsgDelayTime" BO_ 973 20;
BA_ "VFrameFormat" BO_ 973 14;

BA_ "GenSigSendType" SG_ 973 StTrkPos_PR 0;
BA_ "SignalLongName" SG_ 973 StTrkPos_PR "Seat Track Position_PR";
BA_ "GenSigStartValue" SG_ 973 StTrkPos_PR 127;

BA_ "GenSigSendType" SG_ 973 StRtaPos_PR 0;
BA_ "SignalLongName" SG_ 973 StRtaPos_PR "Seat Rotation Position_PR";
BA_ "GenSigStartValue" SG_ 973 StRtaPos_PR 127;

BA_ "GenSigSendType" SG_ 973 StHtSts_PR 0;
BA_ "SignalLongName" SG_ 973 StHtSts_PR "Seat Heat Status_PR";

BA_ "GenSigSendType" SG_ 973 StMsgIntstySts_DR 0;
BA_ "SignalLongName" SG_ 973 StMsgIntstySts_DR "Seat Massage Intensity Status_DR";

BA_ "GenSigSendType" SG_ 973 StMsgIntstySts_PR 0;
BA_ "SignalLongName" SG_ 973 StMsgIntstySts_PR "Seat Massage Intensity Status_PR";

BA_ "GenSigSendType" SG_ 973 StVtSts_PR 0;
BA_ "SignalLongName" SG_ 973 StVtSts_PR "Seat Vent Status_PR";

BA_ "GenSigSendType" SG_ 973 StMsgSts_PR 0;
BA_ "SignalLongName" SG_ 973 StMsgSts_PR "Seat Massage Status_PR";

BA_ "GenSigSendType" SG_ 973 MemCalOtExctSts_PR 4;
BA_ "SignalLongName" SG_ 973 MemCalOtExctSts_PR "Memorization Callout Execution status_PR";

BA_ "GenSigSendType" SG_ 973 MemSts_Set1_PR 4;
BA_ "SignalLongName" SG_ 973 MemSts_Set1_PR "Seat_PR Memorization Status Set1";

BA_ "GenSigSendType" SG_ 973 MemSts_Set2_PR 4;
BA_ "SignalLongName" SG_ 973 MemSts_Set2_PR "Seat_PR Memorization Status Set2";

BA_ "GenSigSendType" SG_ 973 MemSts_Set3_PR 4;
BA_ "SignalLongName" SG_ 973 MemSts_Set3_PR "Seat_PR Memorization Status Set3";

BA_ "GenMsgSendType" BO_ 974 0;
BA_ "GenMsgStartDelayTime" BO_ 974 10;
BA_ "GenMsgCycleTime" BO_ 974 500;
BA_ "GenMsgILSupport" BO_ 974 1;
BA_ "GenMsgCycleTimeFast" BO_ 974 40;
BA_ "GenMsgNrOfRepetition" BO_ 974 3;
BA_ "GenMsgDelayTime" BO_ 974 20;
BA_ "VFrameFormat" BO_ 974 14;

BA_ "GenSigSendType" SG_ 974 MemSts_Set1_RL 4;
BA_ "SignalLongName" SG_ 974 MemSts_Set1_RL "Seat_RL Memorization Status Set1";

BA_ "GenSigSendType" SG_ 974 StTrkPos_RL 0;
BA_ "SignalLongName" SG_ 974 StTrkPos_RL "Seat Track Position_RL";
BA_ "GenSigStartValue" SG_ 974 StTrkPos_RL 127;

BA_ "GenSigSendType" SG_ 974 StSldPos_RL 0;
BA_ "SignalLongName" SG_ 974 StSldPos_RL "Seat Slide Position_RL";
BA_ "GenSigStartValue" SG_ 974 StSldPos_RL 127;

BA_ "GenSigSendType" SG_ 974 MemSts_Set2_RL 4;
BA_ "SignalLongName" SG_ 974 MemSts_Set2_RL "Seat_RL Memorization Status Set2";

BA_ "GenSigSendType" SG_ 974 MemSts_Set3_RL 4;
BA_ "SignalLongName" SG_ 974 MemSts_Set3_RL "Seat_RL Memorization Status Set3";

BA_ "GenSigSendType" SG_ 974 StRtaPos_RL 0;
BA_ "SignalLongName" SG_ 974 StRtaPos_RL "Seat Rotation Position_RL";
BA_ "GenSigStartValue" SG_ 974 StRtaPos_RL 127;

BA_ "GenSigSendType" SG_ 974 StLgRtaPos_RL 0;
BA_ "SignalLongName" SG_ 974 StLgRtaPos_RL "Seat Legsupport Rotation Position_RL";
BA_ "GenSigStartValue" SG_ 974 StLgRtaPos_RL 127;

BA_ "GenSigSendType" SG_ 974 StLgLgthPos_RL 0;
BA_ "SignalLongName" SG_ 974 StLgLgthPos_RL "Seat Legsupport Length Position_RL";
BA_ "GenSigStartValue" SG_ 974 StLgLgthPos_RL 127;

BA_ "GenSigSendType" SG_ 974 StHdrstPos_RL 0;
BA_ "SignalLongName" SG_ 974 StHdrstPos_RL "Seat Headrest Position_RL";
BA_ "GenSigStartValue" SG_ 974 StHdrstPos_RL 127;

BA_ "GenSigSendType" SG_ 974 StMsgSts_RL 0;
BA_ "SignalLongName" SG_ 974 StMsgSts_RL "Seat Massage Status_RL";

BA_ "GenSigSendType" SG_ 974 StMsgIntstySts_RL 0;
BA_ "SignalLongName" SG_ 974 StMsgIntstySts_RL "Seat Massage Intensity Status_RL";

BA_ "GenMsgSendType" BO_ 975 0;
BA_ "GenMsgStartDelayTime" BO_ 975 10;
BA_ "GenMsgCycleTime" BO_ 975 500;
BA_ "GenMsgILSupport" BO_ 975 1;
BA_ "GenMsgCycleTimeFast" BO_ 975 40;
BA_ "GenMsgNrOfRepetition" BO_ 975 3;
BA_ "GenMsgDelayTime" BO_ 975 20;
BA_ "VFrameFormat" BO_ 975 14;

BA_ "GenSigSendType" SG_ 975 MemSts_Set1_RR 4;
BA_ "SignalLongName" SG_ 975 MemSts_Set1_RR "Seat_RR Memorization Status Set1";

BA_ "GenSigSendType" SG_ 975 StTrkPos_RR 0;
BA_ "SignalLongName" SG_ 975 StTrkPos_RR "Seat Track Position_RR";
BA_ "GenSigStartValue" SG_ 975 StTrkPos_RR 127;

BA_ "GenSigSendType" SG_ 975 StSldPos_RR 0;
BA_ "SignalLongName" SG_ 975 StSldPos_RR "Seat Slide Position_RR";
BA_ "GenSigStartValue" SG_ 975 StSldPos_RR 127;

BA_ "GenSigSendType" SG_ 975 MemSts_Set2_RR 4;
BA_ "SignalLongName" SG_ 975 MemSts_Set2_RR "Seat_RR Memorization Status Set2";

BA_ "GenSigSendType" SG_ 975 MemSts_Set3_RR 4;
BA_ "SignalLongName" SG_ 975 MemSts_Set3_RR "Seat_RR Memorization Status Set3";

BA_ "GenSigSendType" SG_ 975 StRtaPos_RR 0;
BA_ "SignalLongName" SG_ 975 StRtaPos_RR "Seat Rotation Position_RR";
BA_ "GenSigStartValue" SG_ 975 StRtaPos_RR 127;

BA_ "GenSigSendType" SG_ 975 StLgRtaPos_RR 0;
BA_ "SignalLongName" SG_ 975 StLgRtaPos_RR "Seat Legsupport Rotation Position_RR";
BA_ "GenSigStartValue" SG_ 975 StLgRtaPos_RR 127;

BA_ "GenSigSendType" SG_ 975 StLgLgthPos_RR 0;
BA_ "SignalLongName" SG_ 975 StLgLgthPos_RR "Seat Legsupport Length Position_RR";
BA_ "GenSigStartValue" SG_ 975 StLgLgthPos_RR 127;

BA_ "GenSigSendType" SG_ 975 StHdrstPos_RR 0;
BA_ "SignalLongName" SG_ 975 StHdrstPos_RR "Seat Headrest Position_RR";
BA_ "GenSigStartValue" SG_ 975 StHdrstPos_RR 127;

BA_ "GenSigSendType" SG_ 975 StMsgSts_RR 0;
BA_ "SignalLongName" SG_ 975 StMsgSts_RR "Seat Massage Status_RR";

BA_ "GenSigSendType" SG_ 975 StMsgIntstySts_RR 0;
BA_ "SignalLongName" SG_ 975 StMsgIntstySts_RR "Seat Massage Intensity Status_RR";

BA_ "GenMsgSendType" BO_ 976 0;
BA_ "GenMsgStartDelayTime" BO_ 976 10;
BA_ "GenMsgCycleTime" BO_ 976 500;
BA_ "GenMsgILSupport" BO_ 976 1;
BA_ "GenMsgCycleTimeFast" BO_ 976 40;
BA_ "GenMsgNrOfRepetition" BO_ 976 3;
BA_ "GenMsgDelayTime" BO_ 976 20;
BA_ "VFrameFormat" BO_ 976 14;

BA_ "GenSigSendType" SG_ 976 StTrkPos_3rdR 0;
BA_ "SignalLongName" SG_ 976 StTrkPos_3rdR "Seat Track Position_3rdR";
BA_ "GenSigStartValue" SG_ 976 StTrkPos_3rdR 127;

BA_ "GenSigSendType" SG_ 976 StRtaPos_3rdR 0;
BA_ "SignalLongName" SG_ 976 StRtaPos_3rdR "Seat Rotation Position_3rdR";
BA_ "GenSigStartValue" SG_ 976 StRtaPos_3rdR 127;

BA_ "GenSigSendType" SG_ 976 StLgRtaPos_3rdR 0;
BA_ "SignalLongName" SG_ 976 StLgRtaPos_3rdR "Seat Legsupport Rotation Position_3rdR";
BA_ "GenSigStartValue" SG_ 976 StLgRtaPos_3rdR 127;

BA_ "GenSigSendType" SG_ 976 StLgLgthPos_3rdR 0;
BA_ "SignalLongName" SG_ 976 StLgLgthPos_3rdR "Seat Legsupport Length Position_3rdR";
BA_ "GenSigStartValue" SG_ 976 StLgLgthPos_3rdR 127;

BA_ "GenSigSendType" SG_ 976 StHtSts_3rdR 0;
BA_ "SignalLongName" SG_ 976 StHtSts_3rdR "Seat Heat Status_3rdR";

BA_ "GenSigSendType" SG_ 976 StVtSts_3rdR 0;
BA_ "SignalLongName" SG_ 976 StVtSts_3rdR "Seat Vent Status_3rdR";

BA_ "GenSigSendType" SG_ 976 StMsgSts_3rdR 0;
BA_ "SignalLongName" SG_ 976 StMsgSts_3rdR "Seat Massage Status_3rdR";

BA_ "GenSigSendType" SG_ 976 StMsgIntstySts_3rdR 0;
BA_ "SignalLongName" SG_ 976 StMsgIntstySts_3rdR "Seat Massage Intensity Status_3rdR";

BA_ "GenMsgSendType" BO_ 977 0;
BA_ "GenMsgStartDelayTime" BO_ 977 10;
BA_ "GenMsgCycleTime" BO_ 977 500;
BA_ "GenMsgILSupport" BO_ 977 1;
BA_ "GenMsgCycleTimeFast" BO_ 977 40;
BA_ "GenMsgNrOfRepetition" BO_ 977 3;
BA_ "GenMsgDelayTime" BO_ 977 20;
BA_ "VFrameFormat" BO_ 977 14;

BA_ "GenSigSendType" SG_ 977 StTrkPos_3rdL 0;
BA_ "SignalLongName" SG_ 977 StTrkPos_3rdL "Seat Track Position_3rdL";
BA_ "GenSigStartValue" SG_ 977 StTrkPos_3rdL 127;

BA_ "GenSigSendType" SG_ 977 StRtaPos_3rdL 0;
BA_ "SignalLongName" SG_ 977 StRtaPos_3rdL "Seat Rotation Position_3rdL";
BA_ "GenSigStartValue" SG_ 977 StRtaPos_3rdL 127;

BA_ "GenSigSendType" SG_ 977 StLgRtaPos_3rdL 0;
BA_ "SignalLongName" SG_ 977 StLgRtaPos_3rdL "Seat Legsupport Rotation Position_3rdL";
BA_ "GenSigStartValue" SG_ 977 StLgRtaPos_3rdL 127;

BA_ "GenSigSendType" SG_ 977 StLgLgthPos_3rdL 0;
BA_ "SignalLongName" SG_ 977 StLgLgthPos_3rdL "Seat Legsupport Length Position_3rdL";
BA_ "GenSigStartValue" SG_ 977 StLgLgthPos_3rdL 127;

BA_ "GenSigSendType" SG_ 977 StHtSts_3rdL 0;
BA_ "SignalLongName" SG_ 977 StHtSts_3rdL "Seat Heat Status_3rdL";

BA_ "GenSigSendType" SG_ 977 StVtSts_3rdL 0;
BA_ "SignalLongName" SG_ 977 StVtSts_3rdL "Seat Vent Status_3rdL";

BA_ "GenSigSendType" SG_ 977 StMsgSts_3rdL 0;
BA_ "SignalLongName" SG_ 977 StMsgSts_3rdL "Seat Massage Status_3rdL";

BA_ "GenSigSendType" SG_ 977 StMsgIntstySts_3rdL 0;
BA_ "SignalLongName" SG_ 977 StMsgIntstySts_3rdL "Seat Massage Intensity Status_3rdL";

BA_ "GenMsgSendType" BO_ 978 0;
BA_ "GenMsgStartDelayTime" BO_ 978 10;
BA_ "GenMsgCycleTime" BO_ 978 500;
BA_ "GenMsgILSupport" BO_ 978 1;
BA_ "GenMsgCycleTimeFast" BO_ 978 40;
BA_ "GenMsgNrOfRepetition" BO_ 978 3;
BA_ "GenMsgDelayTime" BO_ 978 20;
BA_ "VFrameFormat" BO_ 978 14;

BA_ "GenSigSendType" SG_ 978 PhoneRmdrReq 4;
BA_ "SignalLongName" SG_ 978 PhoneRmdrReq "Phone Reminder Request";

BA_ "GenSigSendType" SG_ 978 FODAlrm 4;
BA_ "SignalLongName" SG_ 978 FODAlrm "FOD Alarm";

BA_ "GenSigSendType" SG_ 978 WPCChrgSts 0;
BA_ "SignalLongName" SG_ 978 WPCChrgSts "WPC Charging Status";

BA_ "GenMsgSendType" BO_ 983 0;
BA_ "GenMsgStartDelayTime" BO_ 983 10;
BA_ "GenMsgCycleTime" BO_ 983 500;
BA_ "GenMsgILSupport" BO_ 983 1;
BA_ "GenMsgCycleTimeFast" BO_ 983 40;
BA_ "GenMsgNrOfRepetition" BO_ 983 3;
BA_ "GenMsgDelayTime" BO_ 983 20;
BA_ "VFrameFormat" BO_ 983 14;

BA_ "GenSigSendType" SG_ 983 SRD_LACRearSetTemReq 4;
BA_ "SignalLongName" SG_ 983 SRD_LACRearSetTemReq "SRD_LACRearSetTemRequest";

BA_ "GenSigSendType" SG_ 983 SRD_LRearHVACAcOffSwReq 4;
BA_ "SignalLongName" SG_ 983 SRD_LRearHVACAcOffSwReq "SRD_LRearHVACAcOffSwRequest";

BA_ "GenSigSendType" SG_ 983 SRD_LACRearBlwrLvlReq 4;
BA_ "SignalLongName" SG_ 983 SRD_LACRearBlwrLvlReq "SRD_LACRearBlwrLvlRequest";

BA_ "GenSigSendType" SG_ 983 SRD_LACRearBlwrLvlupdownReq 4;
BA_ "SignalLongName" SG_ 983 SRD_LACRearBlwrLvlupdownReq "SRD_LACRearBlwrLvlupdownRequest";

BA_ "GenSigSendType" SG_ 983 SRD_LRearAutoSwReq 4;
BA_ "SignalLongName" SG_ 983 SRD_LRearAutoSwReq "SRD_LRearAutoSwRequest";

BA_ "GenSigSendType" SG_ 983 SRD_LACRearAirMdReq 4;
BA_ "SignalLongName" SG_ 983 SRD_LACRearAirMdReq "SRD_LACRearAirMdRequest";

BA_ "GenSigSendType" SG_ 983 StdMdReq_Lf 4;
BA_ "SignalLongName" SG_ 983 StdMdReq_Lf "StandardModeRequest_Left";

BA_ "GenSigSendType" SG_ 983 RlxMdReq_Lf 4;
BA_ "SignalLongName" SG_ 983 RlxMdReq_Lf "RelaxModeRequest_Left";

BA_ "GenSigSendType" SG_ 983 CmfrtMdReq_Lf 4;
BA_ "SignalLongName" SG_ 983 CmfrtMdReq_Lf "ComfortModeRequest_Left";

BA_ "GenSigSendType" SG_ 983 SlpMdReq_Lf 4;
BA_ "SignalLongName" SG_ 983 SlpMdReq_Lf "SleepModeRequest_Left";

BA_ "GenSigSendType" SG_ 983 WkMdReq_Lf 4;
BA_ "SignalLongName" SG_ 983 WkMdReq_Lf "WorkModeRequest_Left";

BA_ "GenSigSendType" SG_ 983 WmMdReq_Lf 4;
BA_ "SignalLongName" SG_ 983 WmMdReq_Lf "WarmingModeRequest_Left";

BA_ "GenSigSendType" SG_ 983 ZenMdReq_Lf 4;
BA_ "SignalLongName" SG_ 983 ZenMdReq_Lf "ZenModeRequest_Left";

BA_ "GenSigSendType" SG_ 983 ClMdReq_Lf 4;
BA_ "SignalLongName" SG_ 983 ClMdReq_Lf "CoolingModeRequest_Left";

BA_ "GenSigSendType" SG_ 983 MtngMdReq_Lf 4;
BA_ "SignalLongName" SG_ 983 MtngMdReq_Lf "MeetingModeRequest_Left";

BA_ "GenSigSendType" SG_ 983 StBOSSVIP_L 4;
BA_ "SignalLongName" SG_ 983 StBOSSVIP_L "Seat Track Position Command";

BA_ "GenMsgSendType" BO_ 984 0;
BA_ "GenMsgStartDelayTime" BO_ 984 10;
BA_ "GenMsgCycleTime" BO_ 984 500;
BA_ "GenMsgILSupport" BO_ 984 1;
BA_ "GenMsgCycleTimeFast" BO_ 984 40;
BA_ "GenMsgNrOfRepetition" BO_ 984 3;
BA_ "GenMsgDelayTime" BO_ 984 20;
BA_ "VFrameFormat" BO_ 984 14;

BA_ "GenSigSendType" SG_ 984 SRD_RACRearSetTemReq 4;
BA_ "SignalLongName" SG_ 984 SRD_RACRearSetTemReq "SRD_RACRearSetTemRequest";

BA_ "GenSigSendType" SG_ 984 SRD_RRearHVACAcOffSwReq 4;
BA_ "SignalLongName" SG_ 984 SRD_RRearHVACAcOffSwReq "SRD_RRearHVACAcOffSwRequest";

BA_ "GenSigSendType" SG_ 984 SRD_RACRearBlwrLvlReq 4;
BA_ "SignalLongName" SG_ 984 SRD_RACRearBlwrLvlReq "SRD_RACRearBlwrLvlRequest";

BA_ "GenSigSendType" SG_ 984 SRD_RACRearBlwrLvlupdownReq 4;
BA_ "SignalLongName" SG_ 984 SRD_RACRearBlwrLvlupdownReq "SRD_RACRearBlwrLvlupdownRequest";

BA_ "GenSigSendType" SG_ 984 SRD_RRearAutoSwReq 4;
BA_ "SignalLongName" SG_ 984 SRD_RRearAutoSwReq "SRD_RRearAutoSwRequest";

BA_ "GenSigSendType" SG_ 984 SRD_RACRearAirMdReq 4;
BA_ "SignalLongName" SG_ 984 SRD_RACRearAirMdReq "SRD_RACRearAirMdRequest";

BA_ "GenSigSendType" SG_ 984 StdMdReq_Rt 4;
BA_ "SignalLongName" SG_ 984 StdMdReq_Rt "StandardModeRequest_Right";

BA_ "GenSigSendType" SG_ 984 RlxMdReq_Rt 4;
BA_ "SignalLongName" SG_ 984 RlxMdReq_Rt "RelaxModeRequest_Right";

BA_ "GenSigSendType" SG_ 984 CmfrtMdReq_Rt 4;
BA_ "SignalLongName" SG_ 984 CmfrtMdReq_Rt "ComfortModeRequest_Right";

BA_ "GenSigSendType" SG_ 984 SlpMdReq_Rt 4;
BA_ "SignalLongName" SG_ 984 SlpMdReq_Rt "SleepModeRequest_Right";

BA_ "GenSigSendType" SG_ 984 WkMdReq_Rt 4;
BA_ "SignalLongName" SG_ 984 WkMdReq_Rt "WorkModeRequest_Right";

BA_ "GenSigSendType" SG_ 984 WmMdReq_Rt 4;
BA_ "SignalLongName" SG_ 984 WmMdReq_Rt "WarmingModeRequest_Right";

BA_ "GenSigSendType" SG_ 984 ZenMdReq_Rt 4;
BA_ "SignalLongName" SG_ 984 ZenMdReq_Rt "ZenModeRequest_Right";

BA_ "GenSigSendType" SG_ 984 ClMdReq_Rt 4;
BA_ "SignalLongName" SG_ 984 ClMdReq_Rt "CoolingModeRequest_Right";

BA_ "GenSigSendType" SG_ 984 MtngMdReq_Rt 4;
BA_ "SignalLongName" SG_ 984 MtngMdReq_Rt "MeetingModeRequest_Right";

BA_ "GenSigSendType" SG_ 984 SmkMdReq_Rt 4;
BA_ "SignalLongName" SG_ 984 SmkMdReq_Rt "SmokingModeRequest_Right";

BA_ "GenSigSendType" SG_ 984 StBOSSVIP_R 4;
BA_ "SignalLongName" SG_ 984 StBOSSVIP_R "Seat Rotation Position Command";

BA_ "GenMsgSendType" BO_ 985 0;
BA_ "GenMsgStartDelayTime" BO_ 985 10;
BA_ "GenMsgCycleTime" BO_ 985 500;
BA_ "GenMsgILSupport" BO_ 985 1;
BA_ "GenMsgCycleTimeFast" BO_ 985 40;
BA_ "GenMsgNrOfRepetition" BO_ 985 3;
BA_ "GenMsgDelayTime" BO_ 985 20;
BA_ "VFrameFormat" BO_ 985 14;

BA_ "GenSigSendType" SG_ 985 HMIMtSw_L 4;
BA_ "SignalLongName" SG_ 985 HMIMtSw_L "HMIMuteSwitch";

BA_ "GenSigSendType" SG_ 985 HMICallPhReq_L 4;
BA_ "SignalLongName" SG_ 985 HMICallPhReq_L "HMICall the PhoneRequest";

BA_ "GenSigSendType" SG_ 985 HMIVolUpAdjReq_L 4;
BA_ "SignalLongName" SG_ 985 HMIVolUpAdjReq_L "HMIVolumeAdjustment Up";

BA_ "GenSigSendType" SG_ 985 HMIVolDwAdjReq_L 4;
BA_ "SignalLongName" SG_ 985 HMIVolDwAdjReq_L "HMIVolumeAdjustment Down";

BA_ "GenSigSendType" SG_ 985 HMIMscPreAdjReq_L 4;
BA_ "SignalLongName" SG_ 985 HMIMscPreAdjReq_L "HMIMusicAdj";

BA_ "GenSigSendType" SG_ 985 HMIMscNextAdjReq_L 4;
BA_ "SignalLongName" SG_ 985 HMIMscNextAdjReq_L "HMIMusicAdj";

BA_ "GenSigSendType" SG_ 985 HMIVoiceReq_L 4;
BA_ "SignalLongName" SG_ 985 HMIVoiceReq_L "HMIVoiceReq_L";

BA_ "GenSigSendType" SG_ 985 OMSEyeCntrlReq_L 4;
BA_ "SignalLongName" SG_ 985 OMSEyeCntrlReq_L "OMSEyeControlRequest";

BA_ "GenSigSendType" SG_ 985 HMIAudioScChs_L 4;
BA_ "SignalLongName" SG_ 985 HMIAudioScChs_L "HMIAudioSourceChoose_Left";

BA_ "GenSigSendType" SG_ 985 HMIMscCntrlReq_L 4;
BA_ "SignalLongName" SG_ 985 HMIMscCntrlReq_L "HMIMusicControlRequest_Left";

BA_ "GenMsgSendType" BO_ 986 0;
BA_ "GenMsgStartDelayTime" BO_ 986 10;
BA_ "GenMsgCycleTime" BO_ 986 500;
BA_ "GenMsgILSupport" BO_ 986 1;
BA_ "GenMsgCycleTimeFast" BO_ 986 40;
BA_ "GenMsgNrOfRepetition" BO_ 986 3;
BA_ "GenMsgDelayTime" BO_ 986 20;
BA_ "VFrameFormat" BO_ 986 14;

BA_ "GenSigSendType" SG_ 986 HMIMtSw_R 4;
BA_ "SignalLongName" SG_ 986 HMIMtSw_R "HMIMuteSwitch";

BA_ "GenSigSendType" SG_ 986 HMICallPhReq_R 4;
BA_ "SignalLongName" SG_ 986 HMICallPhReq_R "HMICall the PhoneRequest";

BA_ "GenSigSendType" SG_ 986 HMIVolUpAdjReq_R 4;
BA_ "SignalLongName" SG_ 986 HMIVolUpAdjReq_R "HMIVolumeAdjustment Up";

BA_ "GenSigSendType" SG_ 986 HMIVolDwAdjReq_R 4;
BA_ "SignalLongName" SG_ 986 HMIVolDwAdjReq_R "HMIVolumeAdjustment Down";

BA_ "GenSigSendType" SG_ 986 HMIMscPreAdjReq_R 4;
BA_ "SignalLongName" SG_ 986 HMIMscPreAdjReq_R "HMIMusicAdj";

BA_ "GenSigSendType" SG_ 986 HMIMscNextAdjReq_R 4;
BA_ "SignalLongName" SG_ 986 HMIMscNextAdjReq_R "HMIMusicAdj";

BA_ "GenSigSendType" SG_ 986 HMIVoiceReq_R 4;
BA_ "SignalLongName" SG_ 986 HMIVoiceReq_R "HMIVoiceReq_R";

BA_ "GenSigSendType" SG_ 986 OMSEyeCntrlReq_R 4;
BA_ "SignalLongName" SG_ 986 OMSEyeCntrlReq_R "OMSEyeControlRequest";

BA_ "GenSigSendType" SG_ 986 OMSChldRfReq_R 4;
BA_ "SignalLongName" SG_ 986 OMSChldRfReq_R "OMSChildLeftRequest";

BA_ "GenSigSendType" SG_ 986 HMIAudioScChs_R 4;
BA_ "SignalLongName" SG_ 986 HMIAudioScChs_R "HMIAudioSourceChoose_Right";

BA_ "GenSigSendType" SG_ 986 HMIMscCntrlReq_R 4;
BA_ "SignalLongName" SG_ 986 HMIMscCntrlReq_R "HMIMusicControlRequest_Right";

BA_ "GenMsgSendType" BO_ 993 0;
BA_ "GenMsgStartDelayTime" BO_ 993 10;
BA_ "GenMsgCycleTime" BO_ 993 500;
BA_ "GenMsgILSupport" BO_ 993 1;
BA_ "GenMsgCycleTimeFast" BO_ 993 40;
BA_ "GenMsgNrOfRepetition" BO_ 993 3;
BA_ "GenMsgDelayTime" BO_ 993 20;
BA_ "VFrameFormat" BO_ 993 14;

BA_ "GenSigSendType" SG_ 993 RgnLvReq_HMI 4;
BA_ "SignalLongName" SG_ 993 RgnLvReq_HMI "Regenerative Level Request HMI";

BA_ "GenSigSendType" SG_ 993 RgnLvReq_HMIV 4;
BA_ "SignalLongName" SG_ 993 RgnLvReq_HMIV "Regenerative Level Request HMI Validity";
BA_ "GenSigTimeoutValue" SG_ 993 RgnLvReq_HMIV 1;
BA_ "GenSigStartValue" SG_ 993 RgnLvReq_HMIV 1;

BA_ "GenMsgSendType" BO_ 995 0;
BA_ "GenMsgStartDelayTime" BO_ 995 30;
BA_ "GenMsgCycleTime" BO_ 995 500;
BA_ "GenMsgILSupport" BO_ 995 1;
BA_ "GenMsgCycleTimeFast" BO_ 995 40;
BA_ "GenMsgNrOfRepetition" BO_ 995 3;
BA_ "GenMsgDelayTime" BO_ 995 20;
BA_ "VFrameFormat" BO_ 995 14;

BA_ "GenSigSendType" SG_ 995 ParkingInSetReq 4;
BA_ "SignalLongName" SG_ 995 ParkingInSetReq "Parking In Set Request";

BA_ "GenSigSendType" SG_ 995 ParkingStReq 4;
BA_ "SignalLongName" SG_ 995 ParkingStReq "Parking Start Request";

BA_ "GenSigSendType" SG_ 995 ParkingContinueReq 4;
BA_ "SignalLongName" SG_ 995 ParkingContinueReq "Parking Continue Request";

BA_ "GenSigSendType" SG_ 995 ParkingExitReq 4;
BA_ "SignalLongName" SG_ 995 ParkingExitReq "Parking Exit Request";

BA_ "GenSigSendType" SG_ 995 ParkingOutSetReq 4;
BA_ "SignalLongName" SG_ 995 ParkingOutSetReq "Parking Out Set Request";

BA_ "GenSigSendType" SG_ 995 ParkingDragReq 4;
BA_ "SignalLongName" SG_ 995 ParkingDragReq "Parking Drag Request";

BA_ "GenSigSendType" SG_ 995 ParkingOutDircnReq 4;
BA_ "SignalLongName" SG_ 995 ParkingOutDircnReq "Parking Out Direction Request";

BA_ "GenSigSendType" SG_ 995 ParkingDragSlotTypReq 4;
BA_ "SignalLongName" SG_ 995 ParkingDragSlotTypReq "Parking Drag Slot Type Request";

BA_ "GenSigSendType" SG_ 995 TurnAVMReq 4;
BA_ "SignalLongName" SG_ 995 TurnAVMReq "Turn AVM Request";

BA_ "GenSigSendType" SG_ 995 TrackLineSwReq 4;
BA_ "SignalLongName" SG_ 995 TrackLineSwReq "Track Line Switch Request";

BA_ "GenSigSendType" SG_ 995 UnderPerspectiveSwReq 4;
BA_ "SignalLongName" SG_ 995 UnderPerspectiveSwReq "Under Perspective Switch Request";

BA_ "GenSigSendType" SG_ 995 NarrowPathReq 4;
BA_ "SignalLongName" SG_ 995 NarrowPathReq "Narrow Path Request";

BA_ "GenMsgSendType" BO_ 1015 0;
BA_ "GenMsgStartDelayTime" BO_ 1015 10;
BA_ "GenMsgCycleTime" BO_ 1015 100;
BA_ "GenMsgILSupport" BO_ 1015 1;
BA_ "VFrameFormat" BO_ 1015 14;

BA_ "GenSigSendType" SG_ 1015 EPTRgtnBtnDisableSts 0;
BA_ "SignalLongName" SG_ 1015 EPTRgtnBtnDisableSts "EPTRgtnBtnDisableSts";

BA_ "GenSigSendType" SG_ 1015 PrplsnSysLimit 0;
BA_ "SignalLongName" SG_ 1015 PrplsnSysLimit "Prop Iolation System Limit";

BA_ "GenSigSendType" SG_ 1015 RgnLvReqDisb 0;
BA_ "SignalLongName" SG_ 1015 RgnLvReqDisb "RgnLvReqDisb";

BA_ "GenSigSendType" SG_ 1015 SigPdlMdResp 0;
BA_ "SignalLongName" SG_ 1015 SigPdlMdResp "SigPdlMdResp";

BA_ "GenSigSendType" SG_ 1015 VCUSecyWrnngInfo 0;
BA_ "SignalLongName" SG_ 1015 VCUSecyWrnngInfo "Vehicle Control Unit Secondary Warning Information";

BA_ "GenSigSendType" SG_ 1015 VCUSecyWrnngInfo_RllCnt 0;
BA_ "SignalLongName" SG_ 1015 VCUSecyWrnngInfo_RllCnt "VCUSecyWrnngInfo Rolling Counter";

BA_ "GenSigSendType" SG_ 1015 VCUSecyWrnngInfo_ChkSum 0;
BA_ "SignalLongName" SG_ 1015 VCUSecyWrnngInfo_ChkSum "VCUSecyWrnngInfo CheckSum";

BA_ "NmAsrMessage" BO_ 1089 1;
BA_ "VFrameFormat" BO_ 1089 14;

BA_ "SignalLongName" SG_ 1089 FICM_SrcNdID "FICM Source Node ID";

BA_ "SignalLongName" SG_ 1089 FICM_CBV_RMR "FICM Control Bit Vector Repeat Message Request";

BA_ "SignalLongName" SG_ 1089 FICM_CBV_CS "FICM Control Bit Vector Coordinator Sleep Bit";

BA_ "SignalLongName" SG_ 1089 FICM_CBV_AW "FICM Control Bit Vector Active Wakeup Bit";

BA_ "SignalLongName" SG_ 1089 FICM_CBV_PNI "FICM Control Bit Vector Partial Network Information Bit";

BA_ "SignalLongName" SG_ 1089 FICM_NM_BSMtoRMS "FICM Network Management BSM TO RMS";

BA_ "SignalLongName" SG_ 1089 FICM_NM_PBSMtoRMS "FICM Network Management PBSM TO RMS";

BA_ "SignalLongName" SG_ 1089 FICM_NM_RMStoNOS "FICM Network Management RMS TO NOS";

BA_ "SignalLongName" SG_ 1089 FICM_NM_RSStoNOS "FICM Network Management RSS TO NOS";

BA_ "SignalLongName" SG_ 1089 FICM_NM_RSStoRMS "FICM Network Management RSS TO RMS";

BA_ "SignalLongName" SG_ 1089 FICM_NM_NOStoRMS "FICM Network Management NOS TO RMS";

BA_ "SignalLongName" SG_ 1089 FICM_NM_NOSSta "FICM Network Management NOSSta";

BA_ "SignalLongName" SG_ 1089 FICM_NM_RMSSta "FICM Network Management RMSSta";

BA_ "SignalLongName" SG_ 1089 FICM_UD_WR "FICM Wakeup reason";

BA_ "SignalLongName" SG_ 1089 FICM_UD_PNC "FICM Partial Network Code";

BA_ "SignalLongName" SG_ 1089 FICM_UD_KWR_IGN "FICM Keep Wakeup reasons IGN";

BA_ "SignalLongName" SG_ 1089 FICM_UD_KWR_Diag "FICM Keep Wakeup reasons Diag";

BA_ "SignalLongName" SG_ 1089 FICM_UD_KWR_RMRNotExpired "FICM Keep Wakeup reasons Repeat Message Timer has not expired";

BA_ "SignalLongName" SG_ 1089 FICM_UD_KWR_ECU_Def1 "FICM Keep Wakeup reasons ECU Define 1";

BA_ "SignalLongName" SG_ 1089 FICM_UD_KWR_ECU_Def2 "FICM Keep Wakeup reasons ECU Define 2";

BA_ "SignalLongName" SG_ 1089 FICM_UD_KWR_ECU_Def3 "FICM Keep Wakeup reasons ECU Define 3";

BA_ "SignalLongName" SG_ 1089 FICM_UD_KWR_ECU_Def4 "FICM Keep Wakeup reasons ECU Define 4";

BA_ "SignalLongName" SG_ 1089 FICM_UD_KWR_ECU_Def5 "FICM Keep Wakeup reasons ECU Define 5";

BA_ "SignalLongName" SG_ 1089 FICM_UD_KWR_ECU_Def6 "FICM Keep Wakeup reasons ECU Define 6";

BA_ "SignalLongName" SG_ 1089 FICM_UD_KWR_ECU_Def7 "FICM Keep Wakeup reasons ECU Define 7";

BA_ "SignalLongName" SG_ 1089 FICM_UD_KWR_ECU_Def8 "FICM Keep Wakeup reasons ECU Define 8";

BA_ "SignalLongName" SG_ 1089 FICM_UD_KWR_ECU_Def9 "FICM Keep Wakeup reasons ECU Define 9";

BA_ "SignalLongName" SG_ 1089 FICM_UD_KWR_ECU_Def10 "FICM Keep Wakeup reasons ECU Define 10";

BA_ "SignalLongName" SG_ 1089 FICM_UD_KWR_ECU_Def11 "FICM Keep Wakeup reasons ECU Define 11";

BA_ "SignalLongName" SG_ 1089 FICM_UD_KWR_ECU_Def12 "FICM Keep Wakeup reasons ECU Define 12";

BA_ "SignalLongName" SG_ 1089 FICM_UD_KWR_ECU_Def13 "FICM Keep Wakeup reasons ECU Define 13";

BA_ "GenMsgStartDelayTime" BO_ 1233 10;
BA_ "GenMsgILSupport" BO_ 1233 1;
BA_ "GenMsgCycleTimeFast" BO_ 1233 1000;
BA_ "GenMsgDelayTime" BO_ 1233 1000;
BA_ "VFrameFormat" BO_ 1233 14;

BA_ "GenSigSendType" SG_ 1233 FICMDTCSeriousLvl 5;
BA_ "SignalLongName" SG_ 1233 FICMDTCSeriousLvl "FICM DTC Serious Level";

BA_ "GenSigSendType" SG_ 1233 FICMDTCHiByte 5;
BA_ "SignalLongName" SG_ 1233 FICMDTCHiByte "FICM DTC High Byte";

BA_ "GenSigSendType" SG_ 1233 FICMDTCLowByte 5;
BA_ "SignalLongName" SG_ 1233 FICMDTCLowByte "FICM DTC Low Byte";

BA_ "GenSigSendType" SG_ 1233 FICMDTCFlrTypByte 5;
BA_ "SignalLongName" SG_ 1233 FICMDTCFlrTypByte "FICM DTC Failure Type Byte";

BA_ "GenSigSendType" SG_ 1233 FICMDTCSts 5;
BA_ "SignalLongName" SG_ 1233 FICMDTCSts "FICM DTC Status";

BA_ "GenSigSendType" SG_ 1233 FICMDTCTyp 5;
BA_ "SignalLongName" SG_ 1233 FICMDTCTyp "FICM DTC Type";

BA_ "GenMsgSendType" BO_ 1745 0;
BA_ "GenMsgStartDelayTime" BO_ 1745 30;
BA_ "GenMsgCycleTime" BO_ 1745 1000;
BA_ "GenMsgILSupport" BO_ 1745 1;
BA_ "GenMsgCycleTimeFast" BO_ 1745 200;
BA_ "GenMsgNrOfRepetition" BO_ 1745 3;
BA_ "GenMsgDelayTime" BO_ 1745 200;
BA_ "VFrameFormat" BO_ 1745 14;

BA_ "GenSigSendType" SG_ 1745 FICM_MCUDiagSession 4;
BA_ "SignalLongName" SG_ 1745 FICM_MCUDiagSession "FICM MCU Session Status";

BA_ "DiagRequest" BO_ 1857 1;
BA_ "VFrameFormat" BO_ 1857 14;

BA_ "SignalLongName" SG_ 1857 DiagReqData_FICM "FICM Diagnosis Request Data";

BA_ "DiagResponse" BO_ 1969 1;
BA_ "VFrameFormat" BO_ 1969 14;

BA_ "SignalLongName" SG_ 1969 DiagRespData_FICM "FICM Diagnosis Response Data";

BA_ "DiagState" BO_ 2015 1;
BA_ "VFrameFormat" BO_ 2015 14;

BA_ "SignalLongName" SG_ 2015 DiagReqData_Func "Functional Diagnosis Request Data";

BA_ "GenMsgSendType" BO_ 128 0;
BA_ "GenMsgStartDelayTime" BO_ 128 10;
BA_ "GenMsgCycleTime" BO_ 128 20;
BA_ "GenMsgILSupport" BO_ 128 1;
BA_ "VFrameFormat" BO_ 128 14;

BA_ "GenSigSendType" SG_ 128 DrvrStOcpd 0;
BA_ "SignalLongName" SG_ 128 DrvrStOcpd "Driver Seat Occupied";

BA_ "GenSigSendType" SG_ 128 PsngStOcpd 0;
BA_ "SignalLongName" SG_ 128 PsngStOcpd "Passenger Seat Occupied";

BA_ "GenSigSendType" SG_ 128 SecRowLStOcpd 0;
BA_ "SignalLongName" SG_ 128 SecRowLStOcpd "Second Row Left Seat Occupied";

BA_ "GenSigSendType" SG_ 128 SecRowMidStOcpd 0;
BA_ "SignalLongName" SG_ 128 SecRowMidStOcpd "Second Row Middle Seat Occupied";

BA_ "GenSigSendType" SG_ 128 SecRowRStOcpd 0;
BA_ "SignalLongName" SG_ 128 SecRowRStOcpd "Second Row Right Seat Occupied";

BA_ "GenSigSendType" SG_ 128 ThrdRowLStOcpd 0;
BA_ "SignalLongName" SG_ 128 ThrdRowLStOcpd "Third Row Left Seat Occupied";

BA_ "GenSigSendType" SG_ 128 ThrdRowMidStOcpd 0;
BA_ "SignalLongName" SG_ 128 ThrdRowMidStOcpd "Third Row Middle Seat Occupied";

BA_ "GenSigSendType" SG_ 128 ThrdRowRStOcpd 0;
BA_ "SignalLongName" SG_ 128 ThrdRowRStOcpd "Third Row Right Seat Occupied";

BA_ "GenSigSendType" SG_ 128 VehCrshTyp 0;
BA_ "SignalLongName" SG_ 128 VehCrshTyp "Vehicle Crash Type";

BA_ "GenSigSendType" SG_ 128 VehCrshTypV 0;
BA_ "SignalLongName" SG_ 128 VehCrshTypV "Vehicle Crash Type Validity";

BA_ "GenSigSendType" SG_ 128 DrvrSbltAtc 0;
BA_ "SignalLongName" SG_ 128 DrvrSbltAtc "Driver Seatbelt Attached";

BA_ "GenSigSendType" SG_ 128 DrvrSbltAtcV 0;
BA_ "SignalLongName" SG_ 128 DrvrSbltAtcV "Driver Seatbelt Attached Validity";
BA_ "GenSigStartValue" SG_ 128 DrvrSbltAtcV 1;

BA_ "GenSigSendType" SG_ 128 FrtMidStOcpd 0;
BA_ "SignalLongName" SG_ 128 FrtMidStOcpd "Front Middle Seat Occupied";

BA_ "GenMsgSendType" BO_ 146 0;
BA_ "GenMsgStartDelayTime" BO_ 146 10;
BA_ "GenMsgCycleTime" BO_ 146 10;
BA_ "GenMsgILSupport" BO_ 146 1;
BA_ "VFrameFormat" BO_ 146 14;

BA_ "GenSigSendType" SG_ 146 EnFanReq 0;
BA_ "SignalLongName" SG_ 146 EnFanReq "Engine Fan Request";

BA_ "GenSigSendType" SG_ 146 TCM_92h_RllCnt 0;
BA_ "SignalLongName" SG_ 146 TCM_92h_RllCnt "TCM_92h_RllCnt";

BA_ "GenSigSendType" SG_ 146 TCM_92h_Chksum 0;
BA_ "SignalLongName" SG_ 146 TCM_92h_Chksum "TCM_92h_Chksum";

BA_ "GenMsgSendType" BO_ 148 0;
BA_ "GenMsgStartDelayTime" BO_ 148 10;
BA_ "GenMsgCycleTime" BO_ 148 10;
BA_ "GenMsgILSupport" BO_ 148 1;
BA_ "VFrameFormat" BO_ 148 14;

BA_ "GenSigSendType" SG_ 148 TrCrntShftLvrPosV 0;
BA_ "SignalLongName" SG_ 148 TrCrntShftLvrPosV "Trasmission Current Shift Lever Position Validity";

BA_ "GenSigSendType" SG_ 148 TrCrntShftLvrPos 0;
BA_ "SignalLongName" SG_ 148 TrCrntShftLvrPos "Trasmission Current Shift Lever Position";

BA_ "GenSigSendType" SG_ 148 TrShftLvrPos 0;
BA_ "SignalLongName" SG_ 148 TrShftLvrPos "Transmission Shift Lever Position";

BA_ "GenSigSendType" SG_ 148 TrShftLvrPosV 0;
BA_ "SignalLongName" SG_ 148 TrShftLvrPosV "Transmission Shift Lever Position Validity";

BA_ "GenSigSendType" SG_ 148 TrSysOpngMd 0;
BA_ "SignalLongName" SG_ 148 TrSysOpngMd "Transmission System Operating Mode";

BA_ "GenMsgSendType" BO_ 152 0;
BA_ "GenMsgStartDelayTime" BO_ 152 10;
BA_ "GenMsgCycleTime" BO_ 152 10;
BA_ "GenMsgILSupport" BO_ 152 1;
BA_ "VFrameFormat" BO_ 152 14;

BA_ "GenSigSendType" SG_ 152 PTBrkPdlPos 0;
BA_ "SignalLongName" SG_ 152 PTBrkPdlPos "Powertrain Brake Pedal Position";

BA_ "GenSigSendType" SG_ 152 EnSpd 0;
BA_ "SignalLongName" SG_ 152 EnSpd "Engine Speed";

BA_ "GenSigSendType" SG_ 152 AccelEfctvPos 0;
BA_ "SignalLongName" SG_ 152 AccelEfctvPos "Accelerator Effective Position";

BA_ "GenSigSendType" SG_ 152 AccelActuPos 0;
BA_ "SignalLongName" SG_ 152 AccelActuPos "Accelerator Actual Position";

BA_ "GenSigSendType" SG_ 152 AccelActuPosV 0;
BA_ "SignalLongName" SG_ 152 AccelActuPosV "Accelerator Actual Position Validity";

BA_ "GenSigSendType" SG_ 152 AccelEfctvPosV 0;
BA_ "SignalLongName" SG_ 152 AccelEfctvPosV "Accelerator Effective Position Validity";

BA_ "GenSigSendType" SG_ 152 PTBrkPdlDscrtInptSts 0;
BA_ "SignalLongName" SG_ 152 PTBrkPdlDscrtInptSts "Powertrain Brake Pedal Discrete Input Status";

BA_ "GenSigSendType" SG_ 152 PTBrkPdlDscrtInptStsV 0;
BA_ "SignalLongName" SG_ 152 PTBrkPdlDscrtInptStsV "Powertrain Brake Pedal Discrete Input Status Validity";

BA_ "GenSigSendType" SG_ 152 EnSpdSts 0;
BA_ "SignalLongName" SG_ 152 EnSpdSts "Engine Speed Status";
BA_REL_ "GenSigTimeoutTime" BU_SG_REL_ FICM_FD SG_ 953 SldDrPos_L 5000;
BA_REL_ "GenSigTimeoutTime" BU_SG_REL_ FICM_FD SG_ 953 SldDrOprtSts_L 5000;
BA_REL_ "GenSigTimeoutTime" BU_SG_REL_ FICM_FD SG_ 953 SldDrOprtMd_L 5000;
BA_REL_ "GenSigTimeoutTime" BU_SG_REL_ FICM_FD SG_ 953 SldDrPosSts_L 5000;
BA_REL_ "GenSigTimeoutTime" BU_SG_REL_ FICM_FD SG_ 953 ChldLckSts_L 5000;
BA_REL_ "GenSigTimeoutTime" BU_SG_REL_ FICM_FD SG_ 953 SldDrAbsAlrm_L 5000;
BA_REL_ "GenSigTimeoutTime" BU_SG_REL_ FICM_FD SG_ 954 SldDrPos_R 5000;
BA_REL_ "GenSigTimeoutTime" BU_SG_REL_ FICM_FD SG_ 954 SldDrOprtSts_R 5000;
BA_REL_ "GenSigTimeoutTime" BU_SG_REL_ FICM_FD SG_ 954 SldDrOprtMd_R 5000;
BA_REL_ "GenSigTimeoutTime" BU_SG_REL_ FICM_FD SG_ 954 SldDrPosSts_R 5000;
BA_REL_ "GenSigTimeoutTime" BU_SG_REL_ FICM_FD SG_ 954 ChldLckSts_R 5000;
BA_REL_ "GenSigTimeoutTime" BU_SG_REL_ FICM_FD SG_ 954 SldDrLtcSts_R 5000;
BA_REL_ "GenSigTimeoutTime" BU_SG_REL_ FICM_FD SG_ 954 SldDrAbsAlrm_R 5000;
BA_REL_ "GenSigTimeoutTime" BU_SG_REL_ FICM_FD SG_ 957 HybCampMdDrvrItndSOCMaxAch 1000;
BA_REL_ "GenSigTimeoutTime" BU_SG_REL_ FICM_FD SG_ 957 HybCampMdGennPwrDsp 1000;
BA_REL_ "GenSigTimeoutTime" BU_SG_REL_ FICM_FD SG_ 957 HybCampMdDrvrItndSOCMinAch 1000;
BA_REL_ "GenSigTimeoutTime" BU_SG_REL_ FICM_FD SG_ 957 HybCampMdDrvrItndGennLvlAch 1000;
BA_REL_ "GenSigTimeoutTime" BU_SG_REL_ FICM_FD SG_ 965 VehUnLckForm_VAN 2000;
BA_REL_ "GenSigTimeoutTime" BU_SG_REL_ FICM_FD SG_ 965 RainPrvtMdSts 2000;
BA_REL_ "GenSigTimeoutTime" BU_SG_REL_ FICM_FD SG_ 965 LckAutoWdwClsSts 2000;
BA_REL_ "GenSigTimeoutTime" BU_SG_REL_ FICM_FD SG_ 965 StWelcomeSts_DR 2000;
BA_REL_ "GenSigTimeoutTime" BU_SG_REL_ FICM_FD SG_ 965 TempParkMdSetSts 2000;
BA_REL_ "GenSigTimeoutTime" BU_SG_REL_ FICM_FD SG_ 965 TempParkMode 2000;
BA_REL_ "GenSigTimeoutTime" BU_SG_REL_ FICM_FD SG_ 965 VehUnLckForm 2000;
BA_REL_ "GenSigTimeoutTime" BU_SG_REL_ FICM_FD SG_ 965 LckFdbkSts 2000;
BA_REL_ "GenSigTimeoutTime" BU_SG_REL_ FICM_FD SG_ 965 MrrAutoDipSts 2000;
BA_REL_ "GenSigTimeoutTime" BU_SG_REL_ FICM_FD SG_ 965 MrrAutoFldSts 2000;
BA_REL_ "GenSigTimeoutTime" BU_SG_REL_ FICM_FD SG_ 965 DrvrFatigueReminderSetReqFdbck 2000;
BA_REL_ "GenSigTimeoutTime" BU_SG_REL_ FICM_FD SG_ 965 StWelcomeSts_PR 2000;
BA_REL_ "GenSigTimeoutTime" BU_SG_REL_ FICM_FD SG_ 965 FlwMHmSts 2000;
BA_REL_ "GenSigTimeoutTime" BU_SG_REL_ FICM_FD SG_ 965 IntltWlcmMdSts 2000;
BA_REL_ "GenSigTimeoutTime" BU_SG_REL_ FICM_FD SG_ 965 LockVehRcvrMdSts 2000;
BA_REL_ "GenSigTimeoutTime" BU_SG_REL_ FICM_FD SG_ 965 FndMyCarSts 2000;
BA_REL_ "GenSigTimeoutTime" BU_SG_REL_ FICM_FD SG_ 965 FndMyCarTmSts 2000;
BA_REL_ "GenSigTimeoutTime" BU_SG_REL_ FICM_FD SG_ 965 DrvMod 2000;
BA_REL_ "GenSigTimeoutTime" BU_SG_REL_ FICM_FD SG_ 965 DrvMdReqV 2000;
BA_REL_ "GenSigTimeoutTime" BU_SG_REL_ FICM_FD SG_ 965 MemFdbk 2000;
BA_REL_ "GenSigTimeoutTime" BU_SG_REL_ FICM_FD SG_ 965 MemClrFdbk 2000;
BA_REL_ "GenSigTimeoutTime" BU_SG_REL_ FICM_FD SG_ 965 SnsSldDrSetReqFdbck 2000;
BA_REL_ "GenSigTimeoutTime" BU_SG_REL_ FICM_FD SG_ 965 AutoUnlockingSts 2000;
BA_REL_ "GenSigTimeoutTime" BU_SG_REL_ FICM_FD SG_ 965 MovingAutoLockSts 2000;
BA_REL_ "GenSigTimeoutTime" BU_SG_REL_ FICM_FD SG_ 965 iBDUFctryDeftSetFnsh 2000;
BA_REL_ "GenSigTimeoutTime" BU_SG_REL_ FICM_FD SG_ 965 RunPowMdAutoOffSts 2000;
BA_REL_ "GenSigTimeoutTime" BU_SG_REL_ FICM_FD SG_ 965 RunPowMdAutoOffRmndrReq 2000;
BA_REL_ "GenSigTimeoutTime" BU_SG_REL_ FICM_FD SG_ 969 TireStsWrn_FL 5000;
BA_REL_ "GenSigTimeoutTime" BU_SG_REL_ FICM_FD SG_ 969 TireStsWrn_FR 5000;
BA_REL_ "GenSigTimeoutTime" BU_SG_REL_ FICM_FD SG_ 969 TireStsWrn_RL 5000;
BA_REL_ "GenSigTimeoutTime" BU_SG_REL_ FICM_FD SG_ 969 TireStsWrn_RR 5000;
BA_REL_ "GenSigTimeoutTime" BU_SG_REL_ FICM_FD SG_ 969 TireStsWrn_RLOS 5000;
BA_REL_ "GenSigTimeoutTime" BU_SG_REL_ FICM_FD SG_ 969 TireStsWrn_RROS 5000;
BA_REL_ "GenSigTimeoutTime" BU_SG_REL_ FICM_FD SG_ 970 TirePrs_FL 5000;
BA_REL_ "GenSigTimeoutTime" BU_SG_REL_ FICM_FD SG_ 970 TirePrs_FR 5000;
BA_REL_ "GenSigTimeoutTime" BU_SG_REL_ FICM_FD SG_ 970 TirePrs_RL 5000;
BA_REL_ "GenSigTimeoutTime" BU_SG_REL_ FICM_FD SG_ 970 TirePrs_RR 5000;
BA_REL_ "GenSigTimeoutTime" BU_SG_REL_ FICM_FD SG_ 970 TireTmp_FL 5000;
BA_REL_ "GenSigTimeoutTime" BU_SG_REL_ FICM_FD SG_ 970 TireTmp_FR 5000;
BA_REL_ "GenSigTimeoutTime" BU_SG_REL_ FICM_FD SG_ 970 TireTmp_RL 5000;
BA_REL_ "GenSigTimeoutTime" BU_SG_REL_ FICM_FD SG_ 970 TireTmp_RR 5000;
BA_REL_ "GenSigTimeoutTime" BU_SG_REL_ FICM_FD SG_ 972 StTrkPos_DR 5000;
BA_REL_ "GenSigTimeoutTime" BU_SG_REL_ FICM_FD SG_ 972 StTiltPos_DR 5000;
BA_REL_ "GenSigTimeoutTime" BU_SG_REL_ FICM_FD SG_ 972 StPhaPos_DR 5000;
BA_REL_ "GenSigTimeoutTime" BU_SG_REL_ FICM_FD SG_ 972 StRtaPos_DR 5000;
BA_REL_ "GenSigTimeoutTime" BU_SG_REL_ FICM_FD SG_ 972 StHtSts_DR 5000;
BA_REL_ "GenSigTimeoutTime" BU_SG_REL_ FICM_FD SG_ 972 StVtSts_DR 5000;
BA_REL_ "GenSigTimeoutTime" BU_SG_REL_ FICM_FD SG_ 972 StMsgSts_DR 5000;
BA_REL_ "GenSigTimeoutTime" BU_SG_REL_ FICM_FD SG_ 973 StTrkPos_PR 5000;
BA_REL_ "GenSigTimeoutTime" BU_SG_REL_ FICM_FD SG_ 973 StRtaPos_PR 5000;
BA_REL_ "GenSigTimeoutTime" BU_SG_REL_ FICM_FD SG_ 973 StHtSts_PR 5000;
BA_REL_ "GenSigTimeoutTime" BU_SG_REL_ FICM_FD SG_ 973 StMsgIntstySts_DR 5000;
BA_REL_ "GenSigTimeoutTime" BU_SG_REL_ FICM_FD SG_ 973 StMsgIntstySts_PR 5000;
BA_REL_ "GenSigTimeoutTime" BU_SG_REL_ FICM_FD SG_ 973 StVtSts_PR 5000;
BA_REL_ "GenSigTimeoutTime" BU_SG_REL_ FICM_FD SG_ 973 StMsgSts_PR 5000;
BA_REL_ "GenSigTimeoutTime" BU_SG_REL_ FICM_FD SG_ 973 MemCalOtExctSts_PR 5000;
BA_REL_ "GenSigTimeoutTime" BU_SG_REL_ FICM_FD SG_ 973 MemSts_Set1_PR 5000;
BA_REL_ "GenSigTimeoutTime" BU_SG_REL_ FICM_FD SG_ 973 MemSts_Set2_PR 5000;
BA_REL_ "GenSigTimeoutTime" BU_SG_REL_ FICM_FD SG_ 973 MemSts_Set3_PR 5000;
BA_REL_ "GenSigTimeoutTime" BU_SG_REL_ FICM_FD SG_ 974 MemSts_Set1_RL 5000;
BA_REL_ "GenSigTimeoutTime" BU_SG_REL_ FICM_FD SG_ 974 StTrkPos_RL 5000;
BA_REL_ "GenSigTimeoutTime" BU_SG_REL_ FICM_FD SG_ 974 StSldPos_RL 5000;
BA_REL_ "GenSigTimeoutTime" BU_SG_REL_ FICM_FD SG_ 974 MemSts_Set2_RL 5000;
BA_REL_ "GenSigTimeoutTime" BU_SG_REL_ FICM_FD SG_ 974 MemSts_Set3_RL 5000;
BA_REL_ "GenSigTimeoutTime" BU_SG_REL_ FICM_FD SG_ 974 StRtaPos_RL 5000;
BA_REL_ "GenSigTimeoutTime" BU_SG_REL_ FICM_FD SG_ 974 StLgRtaPos_RL 5000;
BA_REL_ "GenSigTimeoutTime" BU_SG_REL_ FICM_FD SG_ 974 StLgLgthPos_RL 5000;
BA_REL_ "GenSigTimeoutTime" BU_SG_REL_ FICM_FD SG_ 974 StHdrstPos_RL 5000;
BA_REL_ "GenSigTimeoutTime" BU_SG_REL_ FICM_FD SG_ 974 StMsgSts_RL 5000;
BA_REL_ "GenSigTimeoutTime" BU_SG_REL_ FICM_FD SG_ 974 StMsgIntstySts_RL 5000;
BA_REL_ "GenSigTimeoutTime" BU_SG_REL_ FICM_FD SG_ 975 MemSts_Set1_RR 5000;
BA_REL_ "GenSigTimeoutTime" BU_SG_REL_ FICM_FD SG_ 975 StTrkPos_RR 5000;
BA_REL_ "GenSigTimeoutTime" BU_SG_REL_ FICM_FD SG_ 975 StSldPos_RR 5000;
BA_REL_ "GenSigTimeoutTime" BU_SG_REL_ FICM_FD SG_ 975 MemSts_Set2_RR 5000;
BA_REL_ "GenSigTimeoutTime" BU_SG_REL_ FICM_FD SG_ 975 MemSts_Set3_RR 5000;
BA_REL_ "GenSigTimeoutTime" BU_SG_REL_ FICM_FD SG_ 975 StRtaPos_RR 5000;
BA_REL_ "GenSigTimeoutTime" BU_SG_REL_ FICM_FD SG_ 975 StLgRtaPos_RR 5000;
BA_REL_ "GenSigTimeoutTime" BU_SG_REL_ FICM_FD SG_ 975 StLgLgthPos_RR 5000;
BA_REL_ "GenSigTimeoutTime" BU_SG_REL_ FICM_FD SG_ 975 StHdrstPos_RR 5000;
BA_REL_ "GenSigTimeoutTime" BU_SG_REL_ FICM_FD SG_ 975 StMsgSts_RR 5000;
BA_REL_ "GenSigTimeoutTime" BU_SG_REL_ FICM_FD SG_ 975 StMsgIntstySts_RR 5000;
BA_REL_ "GenSigTimeoutTime" BU_SG_REL_ FICM_FD SG_ 976 StTrkPos_3rdR 5000;
BA_REL_ "GenSigTimeoutTime" BU_SG_REL_ FICM_FD SG_ 976 StRtaPos_3rdR 5000;
BA_REL_ "GenSigTimeoutTime" BU_SG_REL_ FICM_FD SG_ 976 StLgRtaPos_3rdR 5000;
BA_REL_ "GenSigTimeoutTime" BU_SG_REL_ FICM_FD SG_ 976 StLgLgthPos_3rdR 5000;
BA_REL_ "GenSigTimeoutTime" BU_SG_REL_ FICM_FD SG_ 976 StHtSts_3rdR 5000;
BA_REL_ "GenSigTimeoutTime" BU_SG_REL_ FICM_FD SG_ 976 StVtSts_3rdR 5000;
BA_REL_ "GenSigTimeoutTime" BU_SG_REL_ FICM_FD SG_ 976 StMsgSts_3rdR 5000;
BA_REL_ "GenSigTimeoutTime" BU_SG_REL_ FICM_FD SG_ 976 StMsgIntstySts_3rdR 5000;
BA_REL_ "GenSigTimeoutTime" BU_SG_REL_ FICM_FD SG_ 977 StTrkPos_3rdL 5000;
BA_REL_ "GenSigTimeoutTime" BU_SG_REL_ FICM_FD SG_ 977 StRtaPos_3rdL 5000;
BA_REL_ "GenSigTimeoutTime" BU_SG_REL_ FICM_FD SG_ 977 StLgRtaPos_3rdL 5000;
BA_REL_ "GenSigTimeoutTime" BU_SG_REL_ FICM_FD SG_ 977 StLgLgthPos_3rdL 5000;
BA_REL_ "GenSigTimeoutTime" BU_SG_REL_ FICM_FD SG_ 977 StHtSts_3rdL 5000;
BA_REL_ "GenSigTimeoutTime" BU_SG_REL_ FICM_FD SG_ 977 StVtSts_3rdL 5000;
BA_REL_ "GenSigTimeoutTime" BU_SG_REL_ FICM_FD SG_ 977 StMsgSts_3rdL 5000;
BA_REL_ "GenSigTimeoutTime" BU_SG_REL_ FICM_FD SG_ 977 StMsgIntstySts_3rdL 5000;
BA_REL_ "GenSigTimeoutTime" BU_SG_REL_ FICM_FD SG_ 978 PhoneRmdrReq 5000;
BA_REL_ "GenSigTimeoutTime" BU_SG_REL_ FICM_FD SG_ 978 FODAlrm 5000;
BA_REL_ "GenSigTimeoutTime" BU_SG_REL_ FICM_FD SG_ 978 WPCChrgSts 5000;
BA_REL_ "GenSigTimeoutTime" BU_SG_REL_ FICM_FD SG_ 983 SRD_LACRearSetTemReq 5000;
BA_REL_ "GenSigTimeoutTime" BU_SG_REL_ FICM_FD SG_ 983 SRD_LRearHVACAcOffSwReq 5000;
BA_REL_ "GenSigTimeoutTime" BU_SG_REL_ FICM_FD SG_ 983 SRD_LACRearBlwrLvlReq 5000;
BA_REL_ "GenSigTimeoutTime" BU_SG_REL_ FICM_FD SG_ 983 SRD_LACRearBlwrLvlupdownReq 5000;
BA_REL_ "GenSigTimeoutTime" BU_SG_REL_ FICM_FD SG_ 983 SRD_LRearAutoSwReq 5000;
BA_REL_ "GenSigTimeoutTime" BU_SG_REL_ FICM_FD SG_ 983 SRD_LACRearAirMdReq 5000;
BA_REL_ "GenSigTimeoutTime" BU_SG_REL_ FICM_FD SG_ 983 StdMdReq_Lf 5000;
BA_REL_ "GenSigTimeoutTime" BU_SG_REL_ FICM_FD SG_ 983 RlxMdReq_Lf 5000;
BA_REL_ "GenSigTimeoutTime" BU_SG_REL_ FICM_FD SG_ 983 CmfrtMdReq_Lf 5000;
BA_REL_ "GenSigTimeoutTime" BU_SG_REL_ FICM_FD SG_ 983 SlpMdReq_Lf 5000;
BA_REL_ "GenSigTimeoutTime" BU_SG_REL_ FICM_FD SG_ 983 WkMdReq_Lf 5000;
BA_REL_ "GenSigTimeoutTime" BU_SG_REL_ FICM_FD SG_ 983 WmMdReq_Lf 5000;
BA_REL_ "GenSigTimeoutTime" BU_SG_REL_ FICM_FD SG_ 983 ZenMdReq_Lf 5000;
BA_REL_ "GenSigTimeoutTime" BU_SG_REL_ FICM_FD SG_ 983 ClMdReq_Lf 5000;
BA_REL_ "GenSigTimeoutTime" BU_SG_REL_ FICM_FD SG_ 983 MtngMdReq_Lf 5000;
BA_REL_ "GenSigTimeoutTime" BU_SG_REL_ FICM_FD SG_ 983 StBOSSVIP_L 5000;
BA_REL_ "GenSigTimeoutTime" BU_SG_REL_ FICM_FD SG_ 984 SRD_RACRearSetTemReq 5000;
BA_REL_ "GenSigTimeoutTime" BU_SG_REL_ FICM_FD SG_ 984 SRD_RRearHVACAcOffSwReq 5000;
BA_REL_ "GenSigTimeoutTime" BU_SG_REL_ FICM_FD SG_ 984 SRD_RACRearBlwrLvlReq 5000;
BA_REL_ "GenSigTimeoutTime" BU_SG_REL_ FICM_FD SG_ 984 SRD_RACRearBlwrLvlupdownReq 5000;
BA_REL_ "GenSigTimeoutTime" BU_SG_REL_ FICM_FD SG_ 984 SRD_RRearAutoSwReq 5000;
BA_REL_ "GenSigTimeoutTime" BU_SG_REL_ FICM_FD SG_ 984 SRD_RACRearAirMdReq 5000;
BA_REL_ "GenSigTimeoutTime" BU_SG_REL_ FICM_FD SG_ 984 StdMdReq_Rt 5000;
BA_REL_ "GenSigTimeoutTime" BU_SG_REL_ FICM_FD SG_ 984 RlxMdReq_Rt 5000;
BA_REL_ "GenSigTimeoutTime" BU_SG_REL_ FICM_FD SG_ 984 CmfrtMdReq_Rt 5000;
BA_REL_ "GenSigTimeoutTime" BU_SG_REL_ FICM_FD SG_ 984 SlpMdReq_Rt 5000;
BA_REL_ "GenSigTimeoutTime" BU_SG_REL_ FICM_FD SG_ 984 WkMdReq_Rt 5000;
BA_REL_ "GenSigTimeoutTime" BU_SG_REL_ FICM_FD SG_ 984 WmMdReq_Rt 5000;
BA_REL_ "GenSigTimeoutTime" BU_SG_REL_ FICM_FD SG_ 984 ZenMdReq_Rt 5000;
BA_REL_ "GenSigTimeoutTime" BU_SG_REL_ FICM_FD SG_ 984 ClMdReq_Rt 5000;
BA_REL_ "GenSigTimeoutTime" BU_SG_REL_ FICM_FD SG_ 984 MtngMdReq_Rt 5000;
BA_REL_ "GenSigTimeoutTime" BU_SG_REL_ FICM_FD SG_ 984 SmkMdReq_Rt 5000;
BA_REL_ "GenSigTimeoutTime" BU_SG_REL_ FICM_FD SG_ 984 StBOSSVIP_R 5000;
BA_REL_ "GenSigTimeoutTime" BU_SG_REL_ FICM_FD SG_ 985 HMIMtSw_L 5000;
BA_REL_ "GenSigTimeoutTime" BU_SG_REL_ FICM_FD SG_ 985 HMICallPhReq_L 5000;
BA_REL_ "GenSigTimeoutTime" BU_SG_REL_ FICM_FD SG_ 985 HMIVolUpAdjReq_L 5000;
BA_REL_ "GenSigTimeoutTime" BU_SG_REL_ FICM_FD SG_ 985 HMIVolDwAdjReq_L 5000;
BA_REL_ "GenSigTimeoutTime" BU_SG_REL_ FICM_FD SG_ 985 HMIMscPreAdjReq_L 5000;
BA_REL_ "GenSigTimeoutTime" BU_SG_REL_ FICM_FD SG_ 985 HMIMscNextAdjReq_L 5000;
BA_REL_ "GenSigTimeoutTime" BU_SG_REL_ FICM_FD SG_ 985 HMIVoiceReq_L 5000;
BA_REL_ "GenSigTimeoutTime" BU_SG_REL_ FICM_FD SG_ 985 OMSEyeCntrlReq_L 5000;
BA_REL_ "GenSigTimeoutTime" BU_SG_REL_ FICM_FD SG_ 985 HMIAudioScChs_L 5000;
BA_REL_ "GenSigTimeoutTime" BU_SG_REL_ FICM_FD SG_ 985 HMIMscCntrlReq_L 5000;
BA_REL_ "GenSigTimeoutTime" BU_SG_REL_ FICM_FD SG_ 986 HMIMtSw_R 5000;
BA_REL_ "GenSigTimeoutTime" BU_SG_REL_ FICM_FD SG_ 986 HMICallPhReq_R 5000;
BA_REL_ "GenSigTimeoutTime" BU_SG_REL_ FICM_FD SG_ 986 HMIVolUpAdjReq_R 5000;
BA_REL_ "GenSigTimeoutTime" BU_SG_REL_ FICM_FD SG_ 986 HMIVolDwAdjReq_R 5000;
BA_REL_ "GenSigTimeoutTime" BU_SG_REL_ FICM_FD SG_ 986 HMIMscPreAdjReq_R 5000;
BA_REL_ "GenSigTimeoutTime" BU_SG_REL_ FICM_FD SG_ 986 HMIMscNextAdjReq_R 5000;
BA_REL_ "GenSigTimeoutTime" BU_SG_REL_ FICM_FD SG_ 986 HMIVoiceReq_R 5000;
BA_REL_ "GenSigTimeoutTime" BU_SG_REL_ FICM_FD SG_ 986 OMSEyeCntrlReq_R 5000;
BA_REL_ "GenSigTimeoutTime" BU_SG_REL_ FICM_FD SG_ 986 OMSChldRfReq_R 5000;
BA_REL_ "GenSigTimeoutTime" BU_SG_REL_ FICM_FD SG_ 986 HMIAudioScChs_R 5000;
BA_REL_ "GenSigTimeoutTime" BU_SG_REL_ FICM_FD SG_ 986 HMIMscCntrlReq_R 5000;
BA_REL_ "GenSigTimeoutTime" BU_SG_REL_ FICM_FD SG_ 1015 EPTRgtnBtnDisableSts 1000;
BA_REL_ "GenSigTimeoutTime" BU_SG_REL_ FICM_FD SG_ 1015 PrplsnSysLimit 1000;
BA_REL_ "GenSigTimeoutTime" BU_SG_REL_ FICM_FD SG_ 1015 RgnLvReqDisb 1000;
BA_REL_ "GenSigTimeoutTime" BU_SG_REL_ FICM_FD SG_ 1015 SigPdlMdResp 1000;
BA_REL_ "GenSigTimeoutTime" BU_SG_REL_ FICM_FD SG_ 1015 VCUSecyWrnngInfo 1000;
BA_REL_ "GenSigTimeoutTime" BU_SG_REL_ FICM_FD SG_ 1015 VCUSecyWrnngInfo_RllCnt 1000;
BA_REL_ "GenSigTimeoutTime" BU_SG_REL_ FICM_FD SG_ 1015 VCUSecyWrnngInfo_ChkSum 1000;
BA_REL_ "GenSigTimeoutTime" BU_SG_REL_ FICM_FD SG_ 128 DrvrStOcpd 250;
BA_REL_ "GenSigTimeoutTime" BU_SG_REL_ FICM_FD SG_ 128 PsngStOcpd 250;
BA_REL_ "GenSigTimeoutTime" BU_SG_REL_ FICM_FD SG_ 128 SecRowLStOcpd 250;
BA_REL_ "GenSigTimeoutTime" BU_SG_REL_ FICM_FD SG_ 128 SecRowMidStOcpd 250;
BA_REL_ "GenSigTimeoutTime" BU_SG_REL_ FICM_FD SG_ 128 SecRowRStOcpd 250;
BA_REL_ "GenSigTimeoutTime" BU_SG_REL_ FICM_FD SG_ 128 ThrdRowLStOcpd 250;
BA_REL_ "GenSigTimeoutTime" BU_SG_REL_ FICM_FD SG_ 128 ThrdRowMidStOcpd 250;
BA_REL_ "GenSigTimeoutTime" BU_SG_REL_ FICM_FD SG_ 128 ThrdRowRStOcpd 250;
BA_REL_ "GenSigTimeoutTime" BU_SG_REL_ FICM_FD SG_ 128 VehCrshTyp 250;
BA_REL_ "GenSigTimeoutTime" BU_SG_REL_ FICM_FD SG_ 128 VehCrshTypV 250;
BA_REL_ "GenSigTimeoutTime" BU_SG_REL_ FICM_FD SG_ 128 DrvrSbltAtc 250;
BA_REL_ "GenSigTimeoutTime" BU_SG_REL_ FICM_FD SG_ 128 DrvrSbltAtcV 250;
BA_REL_ "GenSigTimeoutTime" BU_SG_REL_ FICM_FD SG_ 128 FrtMidStOcpd 250;
BA_REL_ "GenSigTimeoutTime" BU_SG_REL_ FICM_FD SG_ 146 EnFanReq 250;
BA_REL_ "GenSigTimeoutTime" BU_SG_REL_ FICM_FD SG_ 146 TCM_92h_RllCnt 250;
BA_REL_ "GenSigTimeoutTime" BU_SG_REL_ FICM_FD SG_ 146 TCM_92h_Chksum 250;
BA_REL_ "GenSigTimeoutTime" BU_SG_REL_ FICM_FD SG_ 148 TrCrntShftLvrPosV 250;
BA_REL_ "GenSigTimeoutTime" BU_SG_REL_ FICM_FD SG_ 148 TrCrntShftLvrPos 250;
BA_REL_ "GenSigTimeoutTime" BU_SG_REL_ FICM_FD SG_ 148 TrShftLvrPos 250;
BA_REL_ "GenSigTimeoutTime" BU_SG_REL_ FICM_FD SG_ 148 TrShftLvrPosV 250;
BA_REL_ "GenSigTimeoutTime" BU_SG_REL_ FICM_FD SG_ 148 TrSysOpngMd 250;
BA_REL_ "GenSigTimeoutTime" BU_SG_REL_ FICM_FD SG_ 152 PTBrkPdlPos 250;
BA_REL_ "GenSigTimeoutTime" BU_SG_REL_ FICM_FD SG_ 152 EnSpd 250;
BA_REL_ "GenSigTimeoutTime" BU_SG_REL_ FICM_FD SG_ 152 AccelEfctvPos 250;
BA_REL_ "GenSigTimeoutTime" BU_SG_REL_ FICM_FD SG_ 152 AccelActuPos 250;
BA_REL_ "GenSigTimeoutTime" BU_SG_REL_ FICM_FD SG_ 152 AccelActuPosV 250;
BA_REL_ "GenSigTimeoutTime" BU_SG_REL_ FICM_FD SG_ 152 AccelEfctvPosV 250;
BA_REL_ "GenSigTimeoutTime" BU_SG_REL_ FICM_FD SG_ 152 PTBrkPdlDscrtInptSts 250;
BA_REL_ "GenSigTimeoutTime" BU_SG_REL_ FICM_FD SG_ 152 PTBrkPdlDscrtInptStsV 250;
BA_REL_ "GenSigTimeoutTime" BU_SG_REL_ FICM_FD SG_ 152 EnSpdSts 250;
VAL_ 934 StTrkAdjReq_DR 0 "No Request" 1 "Foreward" 2 "Backward" ;
VAL_ 934 StRtaAdjReq_DR 0 "No Request" 1 "Foreward" 2 "Backward" ;
VAL_ 934 StRtaAdjReq_3rdL_FICM 0 "No Request" 1 "Foreward" 2 "Backward" ;
VAL_ 934 StRtaAdjReq_3rdR_FICM 0 "No Request" 1 "Foreward" 2 "Backward" ;
VAL_ 934 StHtReq_RL_HMI 0 "No Request" 1 "Off" 2 "Low" 3 "Medium" 4 "High" ;
VAL_ 934 StVtReq_RL_HMI 0 "No Request" 1 "Off" 2 "Low" 3 "Medium" 4 "High" ;
VAL_ 934 StPstrCmd_RL 0 "No Request" 1 "Sitting position" 2 "Middle position" 3 "Stretch position" ;
VAL_ 934 StHtReq_RR_HMI 0 "No Request" 1 "Off" 2 "Low" 3 "Medium" 4 "High" ;
VAL_ 934 StVtReq_RR_HMI 0 "No Request" 1 "Off" 2 "Low" 3 "Medium" 4 "High" ;
VAL_ 934 StPstrCmd_RR 0 "No Request" 1 "Sitting position" 2 "Middle position" 3 "Stretch position" ;
VAL_ 934 StLgRtaAdjReq_3rdR_FICM 0 "No Request" 1 "UP" 2 "Down" ;
VAL_ 934 StLgRtaAdjReq_3rdL_FICM 0 "No Request" 1 "UP" 2 "Down" ;
VAL_ 934 StTiltAdjReq_DR_FICM 0 "No Request" 1 "UP" 2 "Down" ;
VAL_ 934 StPhaAdjReq_DR_FICM 0 "No Request" 1 "UP" 2 "Down" ;
VAL_ 934 StSldAdjReq_RL_FICM 0 "No Request" 1 "Toward left " 2 "Toward Right" ;
VAL_ 934 StLgLgthAdjReq_RL_FICM 0 "No Request" 1 "Foreward" 2 "Backward" ;
VAL_ 934 StLgRtaAdjReq_RL_FICM 0 "No Request" 1 "UP" 2 "Down" ;
VAL_ 934 StSldAdjReq_RR_FICM 0 "No Request" 1 "Toward left " 2 "Toward Right" ;
VAL_ 934 StLgLgthAdjReq_RR_FICM 0 "No Request" 1 "Foreward" 2 "Backward" ;
VAL_ 934 StLgRtaAdjReq_RR_FICM 0 "No Request" 1 "UP" 2 "Down" ;
VAL_ 934 StHdrstAdjReq_RL_FICM 0 "No Request" 1 "UP" 2 "Down" ;
VAL_ 934 StHdrstAdjReq_RR_FICM 0 "No Request" 1 "UP" 2 "Down" ;
VAL_ 934 StMemCmd_RL_HMI 0 "No Request" 1 "Position1 Memory Reqeust" 2 "Position2 Memory Request" 3 "Position3 Memory Request" ;
VAL_ 934 StMemPstnCalloutCmd_RL_HMI 0 "No Request" 1 "Position1 Callout Request" 2 "Position2 Callout Request" 3 "Position3 Callout Request" ;
VAL_ 934 StMemCmd_RR_HMI 0 "No Request" 1 "Position1 Memory Reqeust" 2 "Position2 Memory Request" 3 "Position3 Memory Request" ;
VAL_ 934 StMemPstnCalloutCmd_RR_HMI 0 "No Request" 1 "Position1 Callout Request" 2 "Position2 Callout Request" 3 "Position3 Callout Request" ;
VAL_ 934 StPstrCmd_DR 0 "No Request" 1 "Sitting position坐姿位" 2 "Middle position舒展位" 3 "Stretch position平躺位" ;
VAL_ 934 StPstrCmd_PR 0 "No Request" 1 "Sitting position" 2 "Middle position" 3 "Stretch position" ;
VAL_ 943 StMsgReq_RL_HMI 0 "No Request" 1 "Mode1" 2 "Mode2" 3 "Mode3" 4 "Mode4" 5 "Mode5" 6 "Mode6" 7 "Mode7" 8 "Mode8" 15 "OFF" ;
VAL_ 943 StMsgReq_RR_HMI 0 "No Request" 1 "Mode1" 2 "Mode2" 3 "Mode3" 4 "Mode4" 5 "Mode5" 6 "Mode6" 7 "Mode7" 8 "Mode8" 15 "OFF" ;
VAL_ 943 StMsgIntstyReq_RL_HMI 0 "No Request" 1 "Level 1" 2 "Level 2" 3 "Level 3" 4 "OFF" ;
VAL_ 943 StMsgIntstyReq_RR_HMI 0 "No Request" 1 "Level 1" 2 "Level 2" 3 "Level 3" 4 "OFF" ;
VAL_ 944 SnsSldDrSetReq 0 "No Request" 1 "OFF" 2 "ON" 3 "Reserved" ;
VAL_ 944 SnsSldDrActnTypSetReq 0 "No Request" 1 "Step On" 2 "Kick Out" ;
VAL_ 944 PDCBeepOffReq_F 0 "No Request" 1 "Beep Off" 2 "Beep On" 3 "Reserved" ;
VAL_ 944 ShowroomMdSts 0 "Off" 1 "On" ;
VAL_ 944 StWelcomeSet_PR 0 "No Request" 1 "On" 2 "Off" ;
VAL_ 944 SldDrOprtMdSt 0 "No Request" 1 "Auto" 2 "Manual" ;
VAL_ 944 FndMyCarSet 0 "No Request(Default)" 1 "Lights Only" 2 "Horn And Lights On" 3 "Reserved" ;
VAL_ 944 PDCBeepOffReq_R 0 "No Request" 1 "Beep Off" 2 "Beep On" 3 "Reserved" ;
VAL_ 944 RstrFctryDfltSttngRqst 0 "False(Default)" 1 "True" ;
VAL_ 944 RemoteLockingFdbckChgReq 0 "No Request(Default)" 1 "Horn And Lights" 2 "Flash Lights Only" 3 "Reserved" ;
VAL_ 944 IntLgtOprtMdSet 0 "No Request" 1 "Auto" 2 "Off / NonAuto（65）" 3 "On" ;
VAL_ 944 VehUnLckFormSet 0 "No Request(Default)" 1 "Unlock Driver Door Only" 2 "Unlock All" ;
VAL_ 944 SentryMdSetReq 0 "No Request" 1 "Sentry Mode On" 2 "Sentry Mode Off" 3 "Reserved" ;
VAL_ 944 TmDsplyFmt 1 "24 hour mode" 0 "12 hour mode" ;
VAL_ 944 MovingAutoLockChgReq 0 "No Request(Default)" 1 "Disable" 2 "Enable" 3 "Reserved" ;
VAL_ 944 LanguageSettingAdj 0 "Simplified Chinese" 1 "UK English" 2 "Norwegian" 3 "German" 4 "French" 5 "Dutch" 6 "Spanish " 7 "Italian" 8 "Arabic" 9 "Hebrew" 10 "Danish" 11 "Swedish" 12 "Finnish" 13 "Turkish" 14 "Portuguese" 15 "Polish" ;
VAL_ 944 DrvMdReq_HMI 0 "No Request" 1 "Normal" 2 "SPORT" 3 "ECO" ;
VAL_ 944 LckAutoWdwClsSet 0 "No Request" 1 "Off" 2 "On" ;
VAL_ 944 AutoUnlockingChgReq 0 "No Request(Default)" 1 "Function Off" 2 "Power OFF Auto Unlock" 3 "Gear P Auto Unlock" 4 "Reserved" ;
VAL_ 944 FolwMeHmSet 0 "No Request" 1 "Off" 2 "30s" 3 "60s" 4 "90s" ;
VAL_ 944 MrrAutoFldSet 0 "No Request" 1 "Off" 2 "On" ;
VAL_ 944 WprSnstvtytSet 0 "No Request" 1 "Position 1(low)" 2 "Position 2" 3 "Position 3" 4 "Position 4" 5 "Position 5(high)" ;
VAL_ 944 RvsGearActvtRrWprSet 0 "No Request" 1 "Off" 2 "On" ;
VAL_ 944 RainPrvtMdSet 0 "No Request" 1 "Off" 2 "On" ;
VAL_ 944 MemReq 0 "No Request" 1 "Set 1" 2 "Set 2" 3 "Set 3" ;
VAL_ 944 MemClrReq 0 "No Request" 1 "Clear Set 1" 2 "Clear Set 2" 3 "Clear Set 3" 4 "Clear All" ;
VAL_ 944 MemCalOtReq 0 "No Request" 1 "Set 1" 2 "Set 2" 3 "Set 3" ;
VAL_ 945 FICMOverSpdThreshholdVal 0 "No Request" ;
VAL_ 945 TempParkReq 0 "No Request" 1 "ON" 2 "OFF " ;
VAL_ 945 ThemeSettingAdj 0 "DayTheme" 1 "NightTheme " ;
VAL_ 945 VehMaintenanceSts 0 "Status OK" 1 "Suggest to maintain" 2 "Maintain immediately" 3 "Reserved" ;
VAL_ 945 FICMOverSpdSwitchReq 0 "NO Request" 1 "OFF" 2 "ON" ;
VAL_ 945 DrvMdRcmdnDispReqFdbck 0 "No Selection" 1 "Select Mode1（EPS Normal+EB Normal）" 2 "Select Mode2（EPS Normal+EB Sport）" 3 "Select Mode3（EPS Sport+EB Normal ）" 4 "Select Mode4（EPS Sport+EB Sport）" ;
VAL_ 945 FICMDispRcmdnInfoEnbSts 0 "Enable" 1 "Disable" ;
VAL_ 945 HMIMtSwSts_L 0 "Mute On" 1 "Mute Off" ;
VAL_ 945 HMICallPhReqSts 0 "Answer the Phone" 1 "Hang Off" ;
VAL_ 945 TempParkMdSet 0 "No Request" 1 "BrakeOpendoor" 2 "Pagelayoutchoice" 3 "Reserved" ;
VAL_ 945 HMIMtSwSts_R 0 "Mute On" 1 "Mute Off" ;
VAL_ 945 RemnDstcDsplyExchgReq 0 "No request（default）" 1 "Dynamic" 2 "Standard" 3 "Reserved" ;
VAL_ 945 DspMeasUntSetReq 0 "NO Request" 1 "MPH" 2 "KPH" ;
VAL_ 945 IntLgtOffReq 0 "No Request" 1 "Request" ;
VAL_ 945 RemnDstcDsplyCycReq 0 "No request" 1 "CLTC" 2 "WLTC" 3 "Reserved" ;
VAL_ 945 ChldLckSw_R 0 "No request" 1 "Lock" 2 "Unlock" 3 "Reserved" ;
VAL_ 945 LockVehRcvrMdSet 0 "No Request" 1 "On" 2 "Off" 3 "Reserved" ;
VAL_ 945 IntltWlcmMdSet 0 "No Request" 1 "On" 2 "Off" 3 "Reserved" ;
VAL_ 945 ThemeSettingAdj_2 0 "No Request " 1 "Theme1 " 2 "Theme2" 3 "Reserved" ;
VAL_ 945 RunPowMdAutoOffReq 0 "No Request" 1 "On（功能开启）" 2 "Off（功能关闭）" ;
VAL_ 945 CPDWrnngLvl 0 "No Warnning" 1 "Warnning Level 1" 2 "Warnning Level 2" 3 "Reserved" ;
VAL_ 945 SldDrCtrlReq_R_HMI 0 "No request" 1 "Open" 2 "Close" 3 "Hold" ;
VAL_ 945 ChldLckSw_L 0 "No request" 1 "Lock" 2 "Unlock" 3 "Reserved" ;
VAL_ 945 CPDFnSwReq 0 "No Request" 1 "Function On" 2 "Function Off" ;
VAL_ 945 RunPowMdAutoOffRmndrFdbck 0 "No Request" 1 "Confirmed（确认）" 2 "Cancel（取消）" ;
VAL_ 945 ESSSwapCnfmFICM 0 "False" 1 "True" ;
VAL_ 945 ESSSwapCnfmFICMV 0 "Valid" 1 "Invalid" ;
VAL_ 945 LanguageSettingAdj_2 0 "Simplified Chinese " 1 "UK English " 2 "Norwegian(挪威语) " 3 "German(德语) " 4 "French(法语) " 5 "Dutch(荷兰语) " 6 "Spanish (西班牙语) " 7 "Italian(意大利语) " 8 "Arabic(阿拉伯语) " 9 "Hebrew(希伯来语) " 10 "Danish(丹麦语) " 11 "Swedish(瑞典语) " 12 "Finnish(芬兰语) " 13 "Turkish(土耳其语) " 14 "Portuguese(葡萄牙语) " 15 "Polish(波兰语)" 16 "Japanese(日语)" 17 "Farsi(波斯语）" 18 "Ukrainian(乌克兰语)" 19 "Traditional Chinese_Taiwan(繁体中文台湾版)" 20 "Traditional Chinese_HongKong(繁体中文香港版)" 21 "Russian(俄语)" 22 "Thai(泰语)" 23 "Portuguese_Brazil(巴西的葡萄牙语)" 24 "Spanish_Argentina(阿根廷的西班牙语)" 25 "USA English(美式英语）" 26 "Hungarian(匈牙利语)" 27 "Spanish_Mexican(墨西哥的西班牙语)" 28 "Spanish_Chilean(智利的西班牙语)" 29 "Greek(希腊语)" 30 "Romanian(罗马尼亚语)" 31 "Czech(捷克语)" 32 "Slovenian(斯洛文尼亚语)" 33 "Croatian(克罗地亚语)" 34 "Vietnamese(越南语)" 35 "Kazakh(哈萨克语)" 36 "Slovak(斯洛伐克语)" 255 "Reserved" ;
VAL_ 946 HdLmpAdjReq 0 "No Request" 1 "Level 1(Lowest)" 2 "Level 2" 3 "Level 3" 4 "Level 4（Highest）" ;
VAL_ 946 VisionMdReq 0 "No request" 1 "ON" 2 "OFF" ;
VAL_ 946 TlgtOprtMdSt 0 "No Request" 1 "Manual（手动模式，仅支持解锁）" 2 "Park（车库模式）" 3 "Norm（正常/全开模式）" ;
VAL_ 946 TlgtOprtReq 0 "No request" 1 "Manual release" 2 "Normal request" 3 "Open" 4 "Close" 5 "Hold" ;
VAL_ 946 PDCMainSWReq_ICU 0 "No Request" 1 "ON" 2 "OFF" ;
VAL_ 946 ChrIndReq_HMI 0 "No Request" 1 "Enable" 2 "Disable" ;
VAL_ 946 WPCEnblReq 0 "No Request" 1 "On" 2 "Off" ;
VAL_ 946 BkltLumSet 0 "No Request" 1 "5%" 2 "10%" 20 "100%" ;
VAL_ 946 FrtFogLmpOprtMdSet 0 "No Request " 1 "Front Lamp " 2 "Reserved " 3 "Off" ;
VAL_ 946 HdLmpOprtMdSet 0 "No Request" 1 "Position Lamp" 2 "Low Beam" 3 "Auto Lamp" 4 "Off" ;
VAL_ 946 FogLmpOprtMdSet 0 "No Request" 1 "Rear Lamp" 2 "Reserved " 3 "Off" ;
VAL_ 946 PMMOFFReq 0 "No Request" 1 "Power Off Request" ;
VAL_ 946 TlgtPrkMdPosSt 127 "No Request" ;
VAL_ 946 MrrAutoDipSet 0 "No Request" 1 "OFF" 2 "Dip Both" 3 "Left Only" 4 "Right Only" ;
VAL_ 946 FrtWprOprtReq 0 "No Request" 1 "Slow Mode" 2 "Fast Mode" 3 "Wiper Off" ;
VAL_ 946 FICMBssMdReq 0 "No Request" 1 "Enter Boss Mode" 2 "Exit Boss Mode" 3 "Reserved" ;
VAL_ 946 PckLgtOprtMdSet 0 "No Request" 1 "Auto" 2 "Off" ;
VAL_ 947 HDCFnSwReq 0 "No Request" 1 "HDC Function ON" 2 "HDC Function OFF" 3 "Reserved" ;
VAL_ 947 ESCFnSwReq 0 "No Request" 1 "ESC Function ON" 2 "ESC Function OFF" 3 "Reserved" ;
VAL_ 947 EPBIgnoffAutoAppFnSwReq 0 "No Request" 1 "EPBIgnoffAutoapplyFunction ON" 2 "EPBIgnoffAutoapplyFunction OFF" 3 "Reserved" ;
VAL_ 947 AVHFnSwReq 0 "No Request" 1 "AVH Function ON" 2 "AVH Function OFF" 3 "Reserved" ;
VAL_ 947 EPBRlseFuSwReq 0 "No Request" 1 "Request" ;
VAL_ 947 EPSCurrModReq 0 "No Request" 1 "Normal" 2 "Sport" 3 "Comfort" ;
VAL_ 947 BrkFlngMdStsReq 0 "No Request" 1 "Normal" 2 "Sport" ;
VAL_ 947 RGNSwReq 0 "No Request" 1 "RGN Request" 2 "RGN Off" 3 "Reserved" ;
VAL_ 947 FrtPsngAirbagOnOffReq 0 "No Request" 1 "OFF" 2 "ON" 3 "Reserved" ;
VAL_ 947 RGNSwReqV 0 "Invalid" 1 "Valid" ;
VAL_ 947 RGNResReq 0 "No request" 1 "RGNRes request" ;
VAL_ 947 RGNResReqV 0 "Invalid" 1 "Valid" ;
VAL_ 947 ASSBtnReq 0 "Button No request" 1 "Button Request " ;
VAL_ 947 SBRSetReq_R 0 "No Request" 1 "OFF" 2 "ON" 3 "Reserved" ;
VAL_ 947 CCOFnSoftSw 0 "OFF" 1 "ON" 2 "Error" 3 "No Request" ;
VAL_ 947 WadeModeReq 0 "No Request" 1 "ON" 2 "OFF" ;
VAL_ 949 HVACOnOffSwReq_HMI 0 "No request" 1 "On" 2 "Off" 3 "Reserved" ;
VAL_ 949 HVACComprOnOffSwReq_HMI 0 "No request" 1 "On" 2 "Off" 3 "Reserved" ;
VAL_ 949 HVACAutoSwReq_HMI 0 "No request" 1 "On" 2 "Off" 3 "Reserved" ;
VAL_ 949 FrtDfstOnSwReq_HMI 0 "No request" 1 "On" 2 "Off" 3 "Reserved" ;
VAL_ 949 RrWndDfstSwReq_HMI 0 "No request" 1 "On" 2 "Off" 3 "Reserved" ;
VAL_ 949 HVACRcctnSwReq_HMI 0 "No request" 1 "InteriorCirculation" 2 "ExteriorCirculation" 3 "Reserved" ;
VAL_ 949 HVACSYNCSwReq_HMI 0 "No request" 1 "On" 2 "Off" 3 "Reserved" ;
VAL_ 949 FICMAirClnrUserCustAutoReq 0 "No request" 1 "On" 2 "Off" 3 "Reserved" ;
VAL_ 949 HVACFLTemReq_HMI 255 "Invalid" ;
VAL_ 949 HVACFRTemReq_HMI 255 "Invalid" ;
VAL_ 949 HVACBlwrLvlReq_HMI 0 "0" 1 "1" 2 "2" 3 "3" 4 "4" 5 "5" 6 "6" 7 "7" 8 "8" 9 "auto blower level" 10 "Reserved" 11 "Reserved" 12 "Reserved" 13 "Reserved" 14 "Reserved" 15 "Invalid" ;
VAL_ 949 HVACAirMdReq_HMI 15 "Invalid" 8 "auto air distribute mode" 7 "Face&Foot&Defrost" 6 "Foot&Defrost" 5 "Face&Defrost" 4 "Face&Foot" 3 "Defrost" 2 "Foot" 1 "Face" 0 "Default" ;
VAL_ 949 HVACFrtBlwrLvlupdownReq_HMI 0 "No request" 1 "Up" 2 "Down" 3 "Invalid" ;
VAL_ 949 HVACFLTemupdownReq_HMI 0 "No request" 1 "Up" 2 "Down" 3 "Invalid" ;
VAL_ 949 HVACFRTemupdownReq_HMI 0 "No request" 1 "Up" 2 "Down" 3 "Invalid" ;
VAL_ 949 HVACFRACMaxSwReq_HMI 0 "No request" 1 "On" 2 "Off" 3 "Reserved" ;
VAL_ 950 HVACRearOnOffSwReq_HMI 0 "No request" 1 "On" 2 "Off" 3 "Reserved" ;
VAL_ 950 HVACRearAutoSwReq_HMI 0 "No request" 1 "On" 2 "Off" 3 "Reserved" ;
VAL_ 950 HVACRearAirMdReq_HMI 15 "Invalid" 8 "auto air distribute mode" 7 "Face&Foot&Defrost" 6 "Foot&Defrost" 5 "Face&Defrost" 4 "Face&Foot" 3 "Defrost" 2 "Foot" 1 "Face" 0 "Default" ;
VAL_ 950 HVACRearSetTemReq_HMI 255 "Invalid" ;
VAL_ 950 HVACRearBlwrLvlReq_HMI 0 "0" 1 "1" 2 "2" 3 "3" 4 "4" 5 "5" 6 "6" 7 "7" 8 "8" 9 "auto blower level" 10 "Reserved" 11 "Reserved" 12 "Reserved" 13 "Reserved" 14 "Reserved" 15 "Invalid" ;
VAL_ 950 HVACRearBlwrLvlupdownReq_HMI 0 "No request" 1 "Up" 2 "Down" 3 "Invalid" ;
VAL_ 950 HVACRearComprOnOffSwReq_HMI 0 "No request" 1 "On" 2 "Off" 3 "Reserved" ;
VAL_ 950 HVACRearBlwr2LvlReq_HMI 0 "0" 1 "1" 2 "2" 3 "3" 4 "4" 5 "5" 6 "6" 7 "7" 8 "8" 9 "auto blower level" 10 "Reserved" 11 "Reserved" 12 "Reserved" 13 "Reserved" 14 "Reserved" 15 "Invalid" ;
VAL_ 950 HVACRearBlwr2LvlupdownReq_HMI 0 "No request" 1 "Up" 2 "Down" 3 "Invalid" ;
VAL_ 950 RFGEngOffOprtReq 0 "Disable" 1 "Enable" 3 "No request" ;
VAL_ 950 RFGOprtReq 0 "OFF" 1 "ON" 3 "No Request" ;
VAL_ 950 RFGTrgtTempReq 63 "No request" ;
VAL_ 950 RFGEngOffOprtDurReq 31 "No request" ;
VAL_ 950 RFGOprtMdReq 0 "Cooling" 1 "Heat" 3 "No Request" ;
VAL_ 951 LeftArVetLRSwingReq_HMI 0 "No Request" ;
VAL_ 951 LeftMidArVetLRSwingReq_HMI 0 "No Request" ;
VAL_ 951 RightMidArVetLRSwingReq_HMI 0 "No Request" ;
VAL_ 951 RightArVetSwingLRReq_HMI 0 "No Request" ;
VAL_ 951 LeftArVetUDSwingReq_HMI 0 "No Request" ;
VAL_ 951 LeftMidArVetUDSwingReq_HMI 0 "No Request" ;
VAL_ 951 RightMidArVetUDSwingReq_HMI 0 "No Request" ;
VAL_ 951 RightArVetSwingUDReq_HMI 0 "No Request" ;
VAL_ 951 LeftArVetFosReq_HMI 0 "No request" 1 "On" 2 "Off" 3 "Reserved" ;
VAL_ 951 RightArVetFosReq_HMI 0 "No request" 1 "On" 2 "Off" 3 "Reserved" ;
VAL_ 951 LeftArVetDistribReq_HMI 0 "No request" 1 "On" 2 "Off" 3 "Reserved" ;
VAL_ 951 RightArVetDistribReq_HMI 0 "No request" 1 "On" 2 "Off" 3 "Reserved" ;
VAL_ 951 LeftArVetSweepReq_HMI 0 "No request" 1 "On" 2 "Off" 3 "Reserved" ;
VAL_ 951 RightArVetSweepReq_HMI 0 "No request" 1 "On" 2 "Off" 3 "Reserved" ;
VAL_ 951 LeftArVetOnOffReq_HMI 0 "No request" 1 "On" 2 "Off" 3 "Reserved" ;
VAL_ 951 RightArVetOnOffReq_HMI 0 "No request" 1 "On" 2 "Off" 3 "Reserved" ;
VAL_ 953 SldDrPos_L 0 "0%（Fully Closed）" 1 "1% " 2 "2%" 100 "100% (Fully Open)" 127 "Invalid" ;
VAL_ 953 SldDrOprtSts_L 0 "Idle" 1 "Opening" 2 "Closing" 3 "Reserved" ;
VAL_ 953 SldDrOprtMd_L 0 "Auto（自动模式）" 1 "Manual（手动模式，按开关仅支持解锁）" ;
VAL_ 953 SldDrPosSts_L 0 "Status Unkown" 1 "Fully Closed (Ajar Inactive)" 2 "Half Locked (Ajar Active)" 3 "Door Open (Ajar Active)" ;
VAL_ 953 ChldLckSts_L 0 "Unlock" 1 "Lock" ;
VAL_ 953 SldDrAbsAlrm_L 0 "No Abuse" 1 "Abuse 1#" 2 "Abuse 2#" 3 "Abuse 3#" ;
VAL_ 954 SldDrPos_R 0 "0%（Fully Closed）" 1 "1% " 2 "2%" 100 "100% (Fully Open)" 127 "Invalid" ;
VAL_ 954 SldDrOprtSts_R 0 "Idle" 1 "Opening" 2 "Closing" 3 "Reserved" ;
VAL_ 954 SldDrOprtMd_R 0 "Auto（自动模式）" 1 "Manual（手动模式，按开关仅支持解锁）" ;
VAL_ 954 SldDrPosSts_R 0 "Status Unkown" 1 "Fully Closed (Ajar Inactive)" 2 "Half Locked (Ajar Active)" 3 "Door Open (Ajar Active)" ;
VAL_ 954 ChldLckSts_R 0 "Unlock" 1 "Lock" ;
VAL_ 954 SldDrLtcSts_R 0 "Status Unkown" 1 "Latch UnLocked" 2 "Latch HalfLocked" 3 "Latch Cinching（自吸动作）" 4 "Latch Locked" 5 "Latch Releasing（释放动作）" 6 "LatchReseting After Cinching" 7 "LatchReseting After Releasing" ;
VAL_ 954 SldDrAbsAlrm_R 0 "No Abuse" 1 "Abuse 1#" 2 "Abuse 2#" 3 "Abuse 3#" ;
VAL_ 956 HMIRfLmp1Cmd 0 "No Request" 1 "Off" 2 "On" ;
VAL_ 956 Wdw_DRAutoOprtnReq 31 "No Request" ;
VAL_ 956 Wdw_PRAutoOprtnReq 31 "No Request" ;
VAL_ 956 AprchngLghtSt 0 "No Request" 1 "Off" 2 "On" 3 "reverse" ;
VAL_ 956 IntWlcmLampSetReq 0 "No Request" 1 "Enable" 2 "Disable" ;
VAL_ 956 HMIRfLmp2Cmd 0 "No Request" 1 "Off" 2 "On" ;
VAL_ 956 Wdw_RLAutoOprtnReq 31 "No Request" ;
VAL_ 956 Wdw_RRAutoOprtnReq 31 "No Request" ;
VAL_ 956 DrvrFatigueReminderSetReq 0 "No Request" 1 "On" 2 "Off" 3 "Reserved" ;
VAL_ 956 LogoLgtOnPGearSetReq 0 "No Request" 1 "Enable" 2 "Disable" ;
VAL_ 956 HMIRfLmp3Cmd 0 "No Request" 1 "Off" 2 "On" ;
VAL_ 956 HMIRfLmp4Cmd 0 "No Request" 1 "Off" 2 "On" ;
VAL_ 956 PSRTrgtSlct 0 "No Request" 1 "Roof" 2 "Shade" 3 "Reserved" ;
VAL_ 956 PSRManualOprtReq 0 "No Request" 1 "Open" 2 "Close/Down" 3 "Tilt Up" ;
VAL_ 956 HMIRfLmpTrdRowCmd 0 "No Request" 1 "Off" 2 "On" ;
VAL_ 956 PSRAutoOprtReq 0 "Full Close (0%)" 1 "Tilt (5%)" 2 "Open (10%)" 3 "Open (15%)" 19 "Open (95%)" 20 "Full Open (100%)" 31 "No Request" ;
VAL_ 956 SRFAutoOprtReq 0 "Full Close (0%)" 1 "Tilt (5%)" 2 "Open (10%)" 3 "Open (15%)" 19 "Open (95%)" 20 "Full Open (100%)" 31 "No Request" ;
VAL_ 956 SRFManualOprtReq 0 "No Request" 1 "Open" 2 "Close/Down" 3 "Tilt Up" ;
VAL_ 956 HVFuelCmd 0 "No Request" 1 "Lock" 2 "UnLock" ;
VAL_ 956 TlgtOprtPosReq 127 "No Request" ;
VAL_ 958 HUDEnbSetReq 0 "No Request" 1 "Disable" 2 "Enable" 3 "Reserved" ;
VAL_ 958 HUDPctAlttdAdjReq 31 "No Request" ;
VAL_ 958 HUDPctInclntAdjReq 15 "No Request" ;
VAL_ 958 HUDDmAdjReq 31 "No Request" ;
VAL_ 958 LVDSSts 0 "Ready" 1 "No ready" ;
VAL_ 965 VehUnLckForm_VAN 0 "Invalid" 1 "All door" 2 "Driver door only" 3 "Passenger Compartment Door Only" ;
VAL_ 965 RainPrvtMdSts 0 "Off" 1 "On" ;
VAL_ 965 LckAutoWdwClsSts 0 "Off" 1 "On" ;
VAL_ 965 StWelcomeSts_DR 0 "On" 1 "Off" ;
VAL_ 965 TempParkMdSetSts 0 "Pagelayoutchoice" 1 "BrakeOpendoor" ;
VAL_ 965 TempParkMode 0 "Off" 1 "On" ;
VAL_ 965 VehUnLckForm 0 "All door" 1 "Driver door only" ;
VAL_ 965 LckFdbkSts 0 "Horn And Lights" 1 "Flash Lights Only" 2 "Reserved" ;
VAL_ 965 MrrAutoDipSts 0 "Off" 1 "Both" 2 "Left Only" 3 "Right Only" ;
VAL_ 965 MrrAutoFldSts 0 "Off" 1 "On" ;
VAL_ 965 DrvrFatigueReminderSetReqFdbck 0 "Off" 1 "On" ;
VAL_ 965 StWelcomeSts_PR 0 "Off" 1 "On" ;
VAL_ 965 FlwMHmSts 0 "Off" 1 "30s" 2 "60s" 3 "90s" ;
VAL_ 965 IntltWlcmMdSts 0 "Off" 1 "On" ;
VAL_ 965 LockVehRcvrMdSts 0 "Off" 1 "On" ;
VAL_ 965 FndMyCarSts 0 "Lights Only" 1 "Horn And Lights" 2 "Reserved" ;
VAL_ 965 FndMyCarTmSts 0 "NoRequest" 1 "10s" 2 "30s" 3 "60s" ;
VAL_ 965 DrvMod 0 "Normal" 1 "SPORT" 2 "ECO" 3 "reserved" ;
VAL_ 965 DrvMdReqV 0 "Invalid" 1 "Valid" ;
VAL_ 965 MemFdbk 0 "No Process" 1 "Success" 2 "Failure" ;
VAL_ 965 MemClrFdbk 0 "No Process" 1 "Success" 2 "Failure" ;
VAL_ 965 SnsSldDrSetReqFdbck 0 "OFF" 1 "ON" ;
VAL_ 965 AutoUnlockingSts 0 "Function Off" 1 "Power OFF Auto Unlock" 2 "Gear P Auto Unlock" 3 "Reserved" ;
VAL_ 965 MovingAutoLockSts 0 "Enable" 1 "Disable" ;
VAL_ 965 iBDUFctryDeftSetFnsh 0 "No Request(Default)" 1 "Successed" 2 "Failed" 3 "Reserved" ;
VAL_ 965 RunPowMdAutoOffSts 0 "On（开关显示开启）" 1 "Off（开关显示关闭）" ;
VAL_ 965 RunPowMdAutoOffRmndrReq 0 "Off（弹框消失）" 1 "On（弹框保持）" ;
VAL_ 969 TireStsWrn_FL 0 "No warning" 1 "High pressure warning" 2 "Low pressure warning" 3 "Quik leakage" 4 "Lost Sensor" 5 "Sensor battery low" 6 "Temperature warning" 7 "Low pressure warning&Quik leakage" 8 "Sensor failure" 9 "Reserved" 10 "Reserved" 11 "Reserved" 12 "Reserved" 13 "Reserved" 14 "Reserved" 15 "Reserved" ;
VAL_ 969 TireStsWrn_FR 0 "No warning" 1 "High pressure warning" 2 "Low pressure warning" 3 "Quik leakage" 4 "Lost Sensor" 5 "Sensor battery low" 6 "Temperature warning" 7 "Low pressure warning&Quik leakage" 8 "Sensor failure" 9 "Reserved" 10 "Reserved" 11 "Reserved" 12 "Reserved" 13 "Reserved" 14 "Reserved" 15 "Reserved" ;
VAL_ 969 TireStsWrn_RL 0 "No warning" 1 "High pressure warning" 2 "Low pressure warning" 3 "Quik leakage" 4 "Lost Sensor" 5 "Sensor battery low" 6 "Temperature warning" 7 "Low pressure warning&Quik leakage" 8 "Sensor failure" 9 "Reserved" 10 "Reserved" 11 "Reserved" 12 "Reserved" 13 "Reserved" 14 "Reserved" 15 "Reserved" ;
VAL_ 969 TireStsWrn_RR 0 "No warning" 1 "High pressure warning" 2 "Low pressure warning" 3 "Quik leakage" 4 "Lost Sensor" 5 "Sensor battery low" 6 "Temperature warning" 7 "Low pressure warning&Quik leakage" 8 "Sensor failure" 9 "Reserved" 10 "Reserved" 11 "Reserved" 12 "Reserved" 13 "Reserved" 14 "Reserved" 15 "Reserved" ;
VAL_ 969 TireStsWrn_RLOS 0 "No warning" 1 "High pressure warning" 2 "Low pressure warning" 3 "Quik leakage" 4 "lost sensor" 5 "Sensor battery low" 6 "Temperature warning" 7 "Low pressure warning&Quik leakage" 8 "Sensor failure" 9 "Reserved" 10 "Reserved" 11 "Reserved" 12 "Reserved" 13 "Reserved" 14 "Reserved" 15 "Reserved" ;
VAL_ 969 TireStsWrn_RROS 0 "No warning" 1 "High pressure warning" 2 "Low pressure warning" 3 "Quik leakage" 4 "lost sensor" 5 "Sensor battery low" 6 "Temperature warning" 7 "Low pressure warning&Quik leakage" 8 "Sensor failure" 9 "Reserved" 10 "Reserved" 11 "Reserved" 12 "Reserved" 13 "Reserved" 14 "Reserved" 15 "Reserved" ;
VAL_ 970 TirePrs_FL 255 "Invalid Value" ;
VAL_ 970 TirePrs_FR 255 "Invalid Value" ;
VAL_ 970 TirePrs_RL 255 "Invalid Value" ;
VAL_ 970 TirePrs_RR 255 "Invalid Value" ;
VAL_ 970 TireTmp_FL 255 "Invalid Value" ;
VAL_ 970 TireTmp_FR 255 "Invalid Value" ;
VAL_ 970 TireTmp_RL 255 "Invalid Value" ;
VAL_ 970 TireTmp_RR 255 "Invalid Value" ;
VAL_ 972 StTrkPos_DR 127 "Invalid" ;
VAL_ 972 StTiltPos_DR 127 "Invalid" ;
VAL_ 972 StPhaPos_DR 127 "Invalid" ;
VAL_ 972 StRtaPos_DR 127 "Invalid" ;
VAL_ 972 StHtSts_DR 0 "OFF" 1 "LOW" 2 "MEDIUM" 3 "HIGH" ;
VAL_ 972 StVtSts_DR 0 "OFF" 1 "LOW" 2 "MEDIUM" 3 "HIGH" ;
VAL_ 972 StMsgSts_DR 0 "OFF" 1 "Mode1" 2 "Mode2" 3 "Mode3" 4 "Mode4" 5 "Mode5" 6 "Mode6" 7 "Mode7" 8 "Mode8" ;
VAL_ 973 StTrkPos_PR 127 "Invalid" ;
VAL_ 973 StRtaPos_PR 127 "Invalid" ;
VAL_ 973 StHtSts_PR 0 "OFF" 1 "LOW" 2 "MEDIUM" 3 "HIGH" ;
VAL_ 973 StMsgIntstySts_DR 0 "OFF(Default)" 1 "Level 1" 2 "Level 2" 3 "Level 3" ;
VAL_ 973 StMsgIntstySts_PR 0 "OFF(Default)" 1 "Level 1" 2 "Level 2" 3 "Level 3" ;
VAL_ 973 StVtSts_PR 0 "OFF" 1 "LOW" 2 "MEDIUM" 3 "HIGH" ;
VAL_ 973 StMsgSts_PR 0 "OFF" 1 "Mode1" 2 "Mode2" 3 "Mode3" 4 "Mode4" 5 "Mode5" 6 "Mode6" 7 "Mode7" 8 "Mode8" ;
VAL_ 973 MemCalOtExctSts_PR 0 "Idle" 1 "In Progress" 2 "Failed" 3 "Completed" ;
VAL_ 973 MemSts_Set1_PR 0 "Invalid" 1 "Valid" ;
VAL_ 973 MemSts_Set2_PR 0 "Invalid" 1 "Valid" ;
VAL_ 973 MemSts_Set3_PR 0 "Invalid" 1 "Valid" ;
VAL_ 974 MemSts_Set1_RL 0 "Invalid" 1 "Valid" ;
VAL_ 974 StTrkPos_RL 127 "Invalid" ;
VAL_ 974 StSldPos_RL 127 "Invalid" ;
VAL_ 974 MemSts_Set2_RL 0 "Invalid" 1 "Valid" ;
VAL_ 974 MemSts_Set3_RL 0 "Invalid" 1 "Valid" ;
VAL_ 974 StRtaPos_RL 127 "Invalid" ;
VAL_ 974 StLgRtaPos_RL 127 "Invalid" ;
VAL_ 974 StLgLgthPos_RL 127 "Invalid" ;
VAL_ 974 StHdrstPos_RL 127 "Invalid" ;
VAL_ 974 StMsgSts_RL 0 "OFF" 1 "Mode1" 2 "Mode2" 3 "Mode3" 4 "Mode4" 5 "Mode5" 6 "Mode6" 7 "Mode7" 8 "Mode8" ;
VAL_ 974 StMsgIntstySts_RL 0 "OFF(Default)" 1 "Level 1" 2 "Level 2" 3 "Level 3" ;
VAL_ 975 MemSts_Set1_RR 0 "Invalid" 1 "Valid" ;
VAL_ 975 StTrkPos_RR 127 "Invalid" ;
VAL_ 975 StSldPos_RR 127 "Invalid" ;
VAL_ 975 MemSts_Set2_RR 0 "Invalid" 1 "Valid" ;
VAL_ 975 MemSts_Set3_RR 0 "Invalid" 1 "Valid" ;
VAL_ 975 StRtaPos_RR 127 "Invalid" ;
VAL_ 975 StLgRtaPos_RR 127 "Invalid" ;
VAL_ 975 StLgLgthPos_RR 127 "Invalid" ;
VAL_ 975 StHdrstPos_RR 127 "Invalid" ;
VAL_ 975 StMsgSts_RR 0 "OFF" 1 "Mode1" 2 "Mode2" 3 "Mode3" 4 "Mode4" 5 "Mode5" 6 "Mode6" 7 "Mode7" 8 "Mode8" ;
VAL_ 975 StMsgIntstySts_RR 0 "OFF(Default)" 1 "Level 1" 2 "Level 2" 3 "Level 3" ;
VAL_ 976 StTrkPos_3rdR 127 "Invalid" ;
VAL_ 976 StRtaPos_3rdR 127 "Invalid" ;
VAL_ 976 StLgRtaPos_3rdR 127 "Invalid" ;
VAL_ 976 StLgLgthPos_3rdR 127 "Invalid" ;
VAL_ 976 StHtSts_3rdR 0 "OFF" 1 "LOW" 2 "MEDIUM" 3 "HIGH" ;
VAL_ 976 StVtSts_3rdR 0 "OFF" 1 "LOW" 2 "MEDIUM" 3 "HIGH" ;
VAL_ 976 StMsgSts_3rdR 0 "OFF" 1 "Mode1" 2 "Mode2" 3 "Mode3" 4 "Mode4" 5 "Mode5" 6 "Mode6" 7 "Mode7" 8 "Mode8" ;
VAL_ 976 StMsgIntstySts_3rdR 0 "OFF(Default)" 1 "Level 1" 2 "Level 2" 3 "Level 3" ;
VAL_ 977 StTrkPos_3rdL 127 "Invalid" ;
VAL_ 977 StRtaPos_3rdL 127 "Invalid" ;
VAL_ 977 StLgRtaPos_3rdL 127 "Invalid" ;
VAL_ 977 StLgLgthPos_3rdL 127 "Invalid" ;
VAL_ 977 StHtSts_3rdL 0 "OFF" 1 "LOW" 2 "MEDIUM" 3 "HIGH" ;
VAL_ 977 StVtSts_3rdL 0 "OFF" 1 "LOW" 2 "MEDIUM" 3 "HIGH" ;
VAL_ 977 StMsgSts_3rdL 0 "OFF" 1 "Mode1" 2 "Mode2" 3 "Mode3" 4 "Mode4" 5 "Mode5" 6 "Mode6" 7 "Mode7" 8 "Mode8" ;
VAL_ 977 StMsgIntstySts_3rdL 0 "OFF(Default)" 1 "Level 1" 2 "Level 2" 3 "Level 3" ;
VAL_ 978 PhoneRmdrReq 1 "Alarm On" 0 "No request" ;
VAL_ 978 FODAlrm 1 "Alarm On" 0 "No request" ;
VAL_ 978 WPCChrgSts 0 "Off" 1 "Standby" 2 "Charging" 3 "Fully Charged" 4 "Error" ;
VAL_ 983 SRD_LACRearSetTemReq 255 "Invalid" ;
VAL_ 983 SRD_LRearHVACAcOffSwReq 0 "No request" 1 "On" 2 "Off" 3 "Reserved" ;
VAL_ 983 SRD_LACRearBlwrLvlReq 0 "0" 1 "1" 2 "2" 3 "3" 4 "4" 5 "5" 6 "6" 7 "7" 8 "8" 9 "auto blower level" 15 "Invalid" ;
VAL_ 983 SRD_LACRearBlwrLvlupdownReq 0 "No request" 1 "Up" 2 "Down" 3 "Invalid" ;
VAL_ 983 SRD_LRearAutoSwReq 0 "No request" 1 "On" 2 "Off" 3 "Reserved" ;
VAL_ 983 SRD_LACRearAirMdReq 15 "Invalid" 8 "auto air distribute mode" 7 "Face&Foot&Defrost" 6 "Foot&Defrost" 5 "Face&Defrost" 4 "Face&Foot" 3 "Defrost" 2 "Foot" 1 "Face" 0 "Default" ;
VAL_ 983 StdMdReq_Lf 0 "No Request " 1 "Standard Mode" ;
VAL_ 983 RlxMdReq_Lf 0 "No Request " 1 "Relax Mode" ;
VAL_ 983 CmfrtMdReq_Lf 0 "No Request " 1 "Comfort Mode " ;
VAL_ 983 SlpMdReq_Lf 0 "No Request " 1 "Enter Sleep Mode " 2 "Exit Sleep Mode" 3 "Reserved" ;
VAL_ 983 WkMdReq_Lf 0 "No Request " 1 "Enter Working Mode" 2 "Exit Working Mode" 3 "Reserved" ;
VAL_ 983 WmMdReq_Lf 0 "No Request " 1 "Warming Mode " ;
VAL_ 983 ZenMdReq_Lf 0 "No Request " 1 "Zen Mode" ;
VAL_ 983 ClMdReq_Lf 0 "No Request " 1 "CoolingMode" ;
VAL_ 983 MtngMdReq_Lf 0 "No Request " 1 "Meeting Mode" ;
VAL_ 983 StBOSSVIP_L 0 "No Request" 1 "Enter PRBOSS Mode" 2 "Exit PRBOSS Mode" 3 "Reserved" ;
VAL_ 984 SRD_RACRearSetTemReq 255 "Invalid" ;
VAL_ 984 SRD_RRearHVACAcOffSwReq 0 "No request" 1 "On" 2 "Off" 3 "Reserved" ;
VAL_ 984 SRD_RACRearBlwrLvlReq 0 "0" 1 "1" 2 "2" 3 "3" 4 "4" 5 "5" 6 "6" 7 "7" 8 "8" 9 "auto blower level" 15 "Invalid" ;
VAL_ 984 SRD_RACRearBlwrLvlupdownReq 0 "No request" 1 "Up" 2 "Down" 3 "Invalid" ;
VAL_ 984 SRD_RRearAutoSwReq 0 "No request" 1 "On" 2 "Off" 3 "Reserved" ;
VAL_ 984 SRD_RACRearAirMdReq 15 "Invalid" 8 "auto air distribute mode" 7 "Face&Foot&Defrost" 6 "Foot&Defrost" 5 "Face&Defrost" 4 "Face&Foot" 3 "Defrost" 2 "Foot" 1 "Face" 0 "Default" ;
VAL_ 984 StdMdReq_Rt 0 "No Request " 1 "Standard Mode" ;
VAL_ 984 RlxMdReq_Rt 0 "No Request " 1 "Relax Mode" ;
VAL_ 984 CmfrtMdReq_Rt 0 "No Request " 1 "Comfort Mode " ;
VAL_ 984 SlpMdReq_Rt 0 "No Request " 1 "Enter Sleep Mode " 2 "Exit Sleep Mode" 3 "Reserved" ;
VAL_ 984 WkMdReq_Rt 0 "No Request " 1 "Enter Working Mode" 2 "Exit Working Mode" 3 "Reserved" ;
VAL_ 984 WmMdReq_Rt 0 "No Request " 1 "Warming Mode " ;
VAL_ 984 ZenMdReq_Rt 0 "No Request " 1 "Zen Mode" ;
VAL_ 984 ClMdReq_Rt 0 "No Request " 1 "CoolingMode" ;
VAL_ 984 MtngMdReq_Rt 0 "No Request " 1 "Meeting Mode" ;
VAL_ 984 SmkMdReq_Rt 0 "No Request " 1 "Enter Smoking Mode " 2 "Exit Smoking Mode" 3 "Reserved" ;
VAL_ 984 StBOSSVIP_R 0 "No Request" 1 "Enter PRBOSS Mode" 2 "Exit PRBOSS Mode" 3 "Reserved" ;
VAL_ 985 HMIMtSw_L 0 "No Request" 1 "Mute On" 2 "Mute Off" 3 "Reserved" ;
VAL_ 985 HMICallPhReq_L 0 "No Request" 1 "Answer the Phone" 2 "Hang Off" 3 "Reserved" ;
VAL_ 985 HMIVolUpAdjReq_L 0 "No Request" 1 "Turn Up" ;
VAL_ 985 HMIVolDwAdjReq_L 0 "No Request" 1 "Turn Down" ;
VAL_ 985 HMIMscPreAdjReq_L 0 "No Request" 1 "Pre" ;
VAL_ 985 HMIMscNextAdjReq_L 0 "No Request" 1 "Next" ;
VAL_ 985 HMIVoiceReq_L 0 "No Request" 1 "Voice ON" ;
VAL_ 985 OMSEyeCntrlReq_L 0 "No Request" 1 "Open" 2 "Close" 3 "Reserved" ;
VAL_ 985 HMIAudioScChs_L 0 "No Request" 1 "FM" 2 "AM" 3 "USB Audio" 4 "BTAudio" 5 "在线音乐" 6 "Carplay音乐" 7 "Reserved" 8 "Reserved" 9 "Reserved" 10 "Reserved" 11 "Reserved" 12 "Reserved" 13 "Reserved" 14 "Reserved" 15 "Reserved" ;
VAL_ 985 HMIMscCntrlReq_L 0 "No Request" 1 "Pause" 2 "Music On" 3 "Reserved" ;
VAL_ 986 HMIMtSw_R 0 "No Request" 1 "Mute On" 2 "Mute Off" 3 "Reserved" ;
VAL_ 986 HMICallPhReq_R 0 "No Request" 1 "Answer the Phone" 2 "Hang Off" 3 "Reserved" ;
VAL_ 986 HMIVolUpAdjReq_R 0 "No Request" 1 "Turn Up" ;
VAL_ 986 HMIVolDwAdjReq_R 0 "No Request" 1 "Turn Down" ;
VAL_ 986 HMIMscPreAdjReq_R 0 "No Request" 1 "Pre" ;
VAL_ 986 HMIMscNextAdjReq_R 0 "No Request" 1 "Next" ;
VAL_ 986 HMIVoiceReq_R 0 "No Request" 1 "Voice ON" ;
VAL_ 986 OMSEyeCntrlReq_R 0 "No Request" 1 "Open" 2 "Close" 3 "Reserved" ;
VAL_ 986 OMSChldRfReq_R 0 "No Request" 1 "Open" 2 "Close" 3 "Reserved" ;
VAL_ 986 HMIAudioScChs_R 0 "No Request" 1 "FM" 2 "AM" 3 "USB Audio" 4 "BTAudio" 5 "在线音乐" 6 "Carplay音乐" 7 "Reserved" 8 "Reserved" 9 "Reserved" 10 "Reserved" 11 "Reserved" 12 "Reserved" 13 "Reserved" 14 "Reserved" 15 "Reserved" ;
VAL_ 986 HMIMscCntrlReq_R 0 "No Request" 1 "Pause" 2 "Music On" 3 "Reserved" ;
VAL_ 993 RgnLvReq_HMI 0 "No Request" 1 "Low" 2 "Standard" 3 "High" ;
VAL_ 993 RgnLvReq_HMIV 0 "Valid" 1 "Invalid" ;
VAL_ 995 ParkingInSetReq 0 "No Request" 1 "Request" ;
VAL_ 995 ParkingStReq 0 "No Request" 1 "Request" ;
VAL_ 995 ParkingContinueReq 0 "No Request" 1 "Request" ;
VAL_ 995 ParkingExitReq 0 "No Request" 1 "Request" ;
VAL_ 995 ParkingOutSetReq 0 "No Request" 1 "Request" ;
VAL_ 995 ParkingDragReq 0 "No Request" 1 "Request" ;
VAL_ 995 ParkingOutDircnReq 0 "No Request" 1 "Request Left" 2 "Request Right" ;
VAL_ 995 ParkingDragSlotTypReq 0 "No request" 1 "Vertical Parking" 2 "Horizontal Parking" 3 "Diagonal parking" ;
VAL_ 995 TurnAVMReq 0 "No Request" 1 "OFF" 2 "ON" ;
VAL_ 995 TrackLineSwReq 0 "No Request" 1 "OFF" 2 "ON" ;
VAL_ 995 UnderPerspectiveSwReq 0 "No Request" 1 "OFF" 2 "ON" ;
VAL_ 995 NarrowPathReq 0 "No Request" 1 "Request" ;
VAL_ 1015 EPTRgtnBtnDisableSts 0 "Default" 1 "Low" 2 "Standard" 3 "Low and Standard" 4 "High" 5 "Low and High" 6 "Standard and High" 7 "Reserved" ;
VAL_ 1015 PrplsnSysLimit 0 "Default" 1 "Warning level 1" 2 "Warning level 2" 3 "Warning level 3" 4 "Warning level 4" 5 "Warning level 5" 6 "Warning level 6" 7 "Warning level 7" 8 "Warning level 8" 9 "Warning level 9" 10 "Warning level 10" 11 "Warning level 11" 12 "Warning level 12" 13 "Warning level 13" 14 "Warning level 14" 15 "Warning level 15" 16 "Warning level 16" 17 "Warning level 17" 18 "Warning level 18" 19 "Warning level 19" 20 "Warning level 20" 21 "Warning level 21" 22 "Warning level 22" 23 "Warning level 23" 24 "Warning level 24" 25 "Warning level 25" 26 "Warning level 26" 27 "Warning level 27" 28 "Warning level 28" 29 "Warning level 29" 30 "Warning level 30" 31 "Warning level 31" ;
VAL_ 1015 RgnLvReqDisb 0 "False" 1 "True" ;
VAL_ 1015 SigPdlMdResp 0 "Default_Mode" 1 "Signal_Pedal_Mode" ;
VAL_ 1015 VCUSecyWrnngInfo 0 "None" 1 "HighCellVoltageDifference,PleaseOnboardChargingAndBalancing" 2 "BatteryThermalRunaway,PleaseEvacuateImmediately" 3 "BattertThermalRunawyPre-warning" ;
VAL_ 1089 FICM_CBV_RMR 0 "NoRequest" 1 "Request" ;
VAL_ 1089 FICM_CBV_CS 0 "NoRequest" 1 "Request" ;
VAL_ 1089 FICM_CBV_AW 0 "PassiveWakeup" 1 "ActiveWakeup" ;
VAL_ 1089 FICM_CBV_PNI 0 "NoPNI" 1 "CntnPNI" ;
VAL_ 1089 FICM_NM_BSMtoRMS 0 "False" 1 "True" ;
VAL_ 1089 FICM_NM_PBSMtoRMS 0 "False" 1 "True" ;
VAL_ 1089 FICM_NM_RMStoNOS 0 "False" 1 "True" ;
VAL_ 1089 FICM_NM_RSStoNOS 0 "False" 1 "True" ;
VAL_ 1089 FICM_NM_RSStoRMS 0 "False" 1 "True" ;
VAL_ 1089 FICM_NM_NOStoRMS 0 "False" 1 "True" ;
VAL_ 1089 FICM_NM_NOSSta 0 "False" 1 "True" ;
VAL_ 1089 FICM_NM_RMSSta 0 "False" 1 "True" ;
VAL_ 1089 FICM_UD_WR 0 "Default" 1 "IGN" 2 "ReceivedNMPDU" 3 "Reserved for Platform" 4 "Reserved for Platform" 5 "Reserved for Platform" 6 "Reserved for Platform" 7 "Reserved for Platform" 8 "Reserved for Platform" 9 "Reserved for Platform" 10 "Reserved for Platform" 11 "Reserved for Platform" 12 "Reserved for Platform" 13 "Reserved for Platform" 14 "Reserved for Platform" 15 "Reserved for Platform" ;
VAL_ 1089 FICM_UD_KWR_IGN 0 "Inactive" 1 "IGN保持唤醒" ;
VAL_ 1089 FICM_UD_KWR_Diag 0 "Inactive" 1 "诊断保持唤醒" ;
VAL_ 1089 FICM_UD_KWR_RMRNotExpired 0 "Inactive" 1 "重复消息状态时间未到期" ;
VAL_ 1233 FICMDTCSeriousLvl 0 "Not Used" 1 "Level Ⅰ" 2 "Level Ⅱ" 3 "Level Ⅲ" 4 "Level Ⅳ" ;
VAL_ 1233 FICMDTCTyp 7 "Reserved" 6 "Type F" 5 "Type E" 4 "Type D" 3 "Type C" 2 "Type B" 1 "Type A" 0 "Not Used" ;
VAL_ 1745 FICM_MCUDiagSession 0 "Unknow" 1 "DefaultSessioninBoot" 2 "ProgrammingSessionin Boot(Locked)" 3 "ProgrammingSessionin Boot(Unlocked)" 4 "DefaultSessioninApp" 5 "ExtendedSessioninApp" 6 "ErrorSession" ;
VAL_ 128 DrvrStOcpd 0 "Invalid" 1 "No Occupied" 2 "Occupied" 3 "Error " ;
VAL_ 128 PsngStOcpd 0 "Invalid" 1 "No Occupied" 2 "Occupied" 3 "Error " ;
VAL_ 128 SecRowLStOcpd 0 "Invalid" 1 "No Occupied" 2 "Occupied" 3 "Error " ;
VAL_ 128 SecRowMidStOcpd 0 "Invalid" 1 "No Occupied" 2 "Occupied" 3 "Error " ;
VAL_ 128 SecRowRStOcpd 0 "Invalid" 1 "No Occupied" 2 "Occupied" 3 "Error " ;
VAL_ 128 ThrdRowLStOcpd 0 "Invalid" 1 "No Occupied" 2 "Occupied" 3 "Error " ;
VAL_ 128 ThrdRowMidStOcpd 0 "Invalid" 1 "No Occupied" 2 "Occupied" 3 "Error " ;
VAL_ 128 ThrdRowRStOcpd 0 "Invalid" 1 "No Occupied" 2 "Occupied" 3 "Error " ;
VAL_ 128 VehCrshTyp 0 "No Crash" 1 "Front" 2 "Left Hand Side" 3 "Front and Left Hand Side" 4 "Right Hand Side" 5 "Front and Right Hand Side" 6 "Left Hand Side and Right Hand Side" 7 "Front and Left Hand Side and Right Hand Side" 8 "Rear" 9 "Front and Rear" 10 "Left Hand Side and Rear" 11 "Front and Left Hand Side and Rear" 12 "Right Hand Side and Rear" 13 "Front and Right Hand Side and REAR" 14 "Left Hand Side and Right Hand Side and Rear" 15 "Front and Left Hand Side and Right Hand Side and Rear" ;
VAL_ 128 VehCrshTypV 0 "Invalid" 1 "Valid" ;
VAL_ 128 DrvrSbltAtc 0 "Not attached" 1 "Attached" ;
VAL_ 128 DrvrSbltAtcV 0 "Invalid" 1 "Valid" ;
VAL_ 128 FrtMidStOcpd 0 "Invalid" 1 "No Occupied" 2 "Occupied" 3 "Error " ;
VAL_ 146 EnFanReq 3 "High-Speed control" 2 "Mid-Speed control" 1 "Low-Speed control" 0 "Fan control is not needed" ;
VAL_ 148 TrCrntShftLvrPosV 0 "Invalid" 1 "Valid" ;
VAL_ 148 TrCrntShftLvrPos 15 "Invalid value" 5 "M" 4 "D" 3 "N" 2 "R" 1 "P" 0 "Between Ranges(Reserved)" ;
VAL_ 148 TrShftLvrPos 15 "Invalid value" 14 "Reserved" 13 "Reserved" 12 "Reserved" 11 "Reserved" 10 "Reserved" 9 "Reserved" 8 "Reserved" 7 "Reserved" 6 "Reserved" 5 "M" 4 "D" 3 "N" 2 "R" 1 "P" 0 "Between Ranges(Reserved)" ;
VAL_ 148 TrShftLvrPosV 0 "Invalid" 1 "Valid" ;
VAL_ 148 TrSysOpngMd 0 "Standard" 1 "Sport" 2 "Economic" 3 "Snow Mode" 4 "Mud" 5 "Sand" 6 "4L" 7 "Off-Road" 8 "Rock" 9 "Manual" 10 "Failure" 11 "Invalid" 12 "Reserved" ;
VAL_ 152 PTBrkPdlPos 255 "Invalid" ;
VAL_ 152 EnSpd 65535 "Invalid" ;
VAL_ 152 AccelActuPosV 0 "Invalid" 1 "valid" ;
VAL_ 152 AccelEfctvPosV 0 "Invalid" 1 "valid" ;
VAL_ 152 PTBrkPdlDscrtInptSts 1 "Brake applied" 0 "Brake not applied" ;
VAL_ 152 PTBrkPdlDscrtInptStsV 0 "Invalid" 1 "Valid" ;
VAL_ 152 EnSpdSts 2 "Reserved" 3 "Invalid" 1 "Degraded Operation" 0 "Normal Operation" ;
